VERSION "HNNBNNNYNNNNNNNNNNNNNNNNNNNNNNNNNNNNNNNNNN/4/%%%/4/'%**4NNN///"

NS_ :

BS_:

BU_: BAP_Tester BedienDisp_mi BedienDisp_vo_mi CDI ConMod_CD DashCAM Gateway_Max ICC_IO_Node LSH OCU RDK_RS3 Sound_MIB_ab_Gen3 STH ZR_MIB_EINSTIEG_ab_Gen3 ZR_MIB_OPTION_ab_Gen3 ZR_MIB_TOP_ab_Gen3

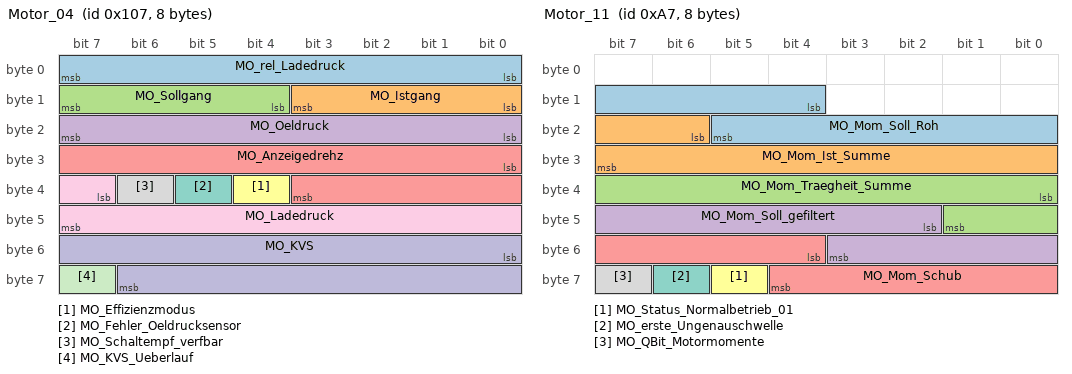
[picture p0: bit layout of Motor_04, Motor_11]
BO_ 263 Motor_04: 8 Gateway_Max
 SG_ MO_rel_Ladedruck : 0|8@1+ (0.4,0) [0.0|100.0] "Unit_PerCent"  ZR_MIB_EINSTIEG_ab_Gen3,ZR_MIB_OPTION_ab_Gen3,ZR_MIB_TOP_ab_Gen3
 SG_ MO_Istgang : 8|4@1+ (1.0,0.0) [0.0|15] ""  OCU,ZR_MIB_EINSTIEG_ab_Gen3,ZR_MIB_OPTION_ab_Gen3,ZR_MIB_TOP_ab_Gen3
 SG_ MO_Sollgang : 12|4@1+ (1.0,0.0) [0.0|15] ""  OCU,ZR_MIB_EINSTIEG_ab_Gen3,ZR_MIB_OPTION_ab_Gen3,ZR_MIB_TOP_ab_Gen3
 SG_ MO_Oeldruck : 16|8@1+ (0.04,0) [0.00|10.00] "Unit_Bar"  Vector__XXX
 SG_ MO_Anzeigedrehz : 24|12@1+ (3,0) [0|12282] "Unit_MinutInver"  OCU,ZR_MIB_EINSTIEG_ab_Gen3,ZR_MIB_OPTION_ab_Gen3,ZR_MIB_TOP_ab_Gen3
 SG_ MO_Effizienzmodus : 36|1@1+ (1.0,0.0) [0.0|1] ""  Vector__XXX
 SG_ MO_Fehler_Oeldrucksensor : 37|1@1+ (1.0,0.0) [0.0|1] ""  OCU
 SG_ MO_Schaltempf_verfbar : 38|1@1+ (1.0,0.0) [0.0|1] ""  OCU,ZR_MIB_EINSTIEG_ab_Gen3,ZR_MIB_OPTION_ab_Gen3,ZR_MIB_TOP_ab_Gen3
 SG_ MO_Ladedruck : 39|9@1+ (0.01,0) [0.00|5.10] "Unit_Bar"  OCU,ZR_MIB_EINSTIEG_ab_Gen3,ZR_MIB_OPTION_ab_Gen3,ZR_MIB_TOP_ab_Gen3
 SG_ MO_KVS : 48|15@1+ (1,0) [0|32767] "Unit_MicroLiter"  OCU
 SG_ MO_KVS_Ueberlauf : 63|1@1+ (1.0,0.0) [0.0|1] ""  OCU

BO_ 1600 Motor_07: 8 Gateway_Max
 SG_ MO_QBit_Ansaugluft_Temp : 0|1@1+ (1.0,0.0) [0.0|1] ""  Vector__XXX
 SG_ MO_QBit_Oel_Temp : 1|1@1+ (1.0,0.0) [0.0|1] ""  OCU,ZR_MIB_OPTION_ab_Gen3
 SG_ MO_QBit_Kuehlmittel_Temp : 2|1@1+ (1.0,0.0) [0.0|1] ""  OCU,ZR_MIB_OPTION_ab_Gen3
 SG_ MO_KL15_Abschaltempfehlung : 3|1@1+ (1.0,0.0) [0.0|1] ""  Vector__XXX
 SG_ MO_HYB_Fehler_HV_Netz : 4|1@1+ (1.0,0.0) [0.0|1] ""  Vector__XXX
 SG_ MO_aktives_Getriebeheizen : 5|1@1+ (1.0,0.0) [0.0|1] ""  Vector__XXX
 SG_ MO_Absperrventil_oeffnen : 6|2@1+ (1.0,0.0) [0.0|3] ""  Vector__XXX
 SG_ MO_Ansaugluft_Temp : 8|8@1+ (0.75,-48) [-48.00|141.75] "Unit_DegreCelsi"  OCU
 SG_ MO_Oel_Temp : 16|8@1+ (1,-60) [-60|192] "Unit_DegreCelsi"  OCU,ZR_MIB_OPTION_ab_Gen3
 SG_ MO_Kuehlmittel_Temp : 24|8@1+ (0.75,-48) [-48.00|141.75] "Unit_DegreCelsi"  OCU,STH,ZR_MIB_OPTION_ab_Gen3
 SG_ MO_Hoeheninfo : 32|8@1+ (0.00781,0) [0.00000|1.98374] ""  LSH,OCU,STH
 SG_ MO_Kennfeldk : 40|1@1+ (1.0,0.0) [0.0|1] ""  Vector__XXX
 SG_ MO_Versionsinfo_02 : 41|5@1+ (1.0,0.0) [0.0|31] ""  Vector__XXX
 SG_ MO_QBit_Hoeheninfo : 46|1@1+ (1.0,0.0) [0.0|1] ""  Vector__XXX
 SG_ MO_Getriebe_kuehlen : 47|1@1+ (1.0,0.0) [0.0|1] ""  Vector__XXX
 SG_ MO_Mom_Traegheit_02 : 48|5@1+ (0.01,0) [0.00|0.31] "Unit_KiloGramMeterSquar"  OCU
 SG_ MO_Heizungspumpenansteuerung : 53|4@1+ (10,0) [0|100] "Unit_PerCent"  STH
 SG_ MO_SpannungsAnf : 57|1@1+ (1.0,0.0) [0.0|1] ""  Vector__XXX
 SG_ MO_Nachlaufzeit_Heizungspumpe : 58|6@1+ (15,0) [0|945] "Unit_Secon"  STH

BO_ 1607 Motor_09: 8 Gateway_Max
 SG_ MO_ITM_Kuehlmittel_Temp : 0|8@1+ (0.75,-48) [-45.75|143.25] "Unit_DegreCelsi"  ZR_MIB_OPTION_ab_Gen3
 SG_ MO_E85_Sensor : 8|4@1+ (10,0) [0|100] "Unit_PerCent"  LSH,STH
 SG_ SCR_Anz_Motorstarts : 12|4@1+ (1.0,0.0) [0.0|15] ""  Vector__XXX
 SG_ SCR_Reichweite : 16|15@1+ (1,0) [0|32766] "Unit_KiloMeter"  Vector__XXX
 SG_ MO_Ethanol_Spuelhinweis : 31|1@1+ (1.0,0.0) [0.0|1] ""  Vector__XXX
 SG_ SCR_Warnstufe_1 : 32|1@1+ (1.0,0.0) [0.0|1] ""  Vector__XXX
 SG_ SCR_Warnstufe_2 : 33|1@1+ (1.0,0.0) [0.0|1] ""  Vector__XXX
 SG_ SCR_Text : 34|3@1+ (1.0,0.0) [0.0|7] ""  Vector__XXX
 SG_ SCR_Akustik : 37|2@1+ (1.0,0.0) [0.0|3] ""  Vector__XXX
 SG_ SCR_verbaut : 39|1@1+ (1.0,0.0) [0.0|1] ""  Vector__XXX
 SG_ MO_Kraftstofffilter_Wasser : 40|1@1+ (1.0,0.0) [0.0|1] ""  Vector__XXX
 SG_ SCR_Systemfehler : 41|1@1+ (1.0,0.0) [0.0|1] ""  Vector__XXX
 SG_ SCR_Inducement_Strategie : 42|2@1+ (1.0,0.0) [0.0|3] ""  Vector__XXX
 SG_ MO_CO2_Faktor : 44|12@1+ (1,0) [1|4094] "Unit_GramPerLiter"  Vector__XXX
 SG_ MO_MKB_MUX M  : 56|2@1+ (1.0,0.0) [0.0|3] ""  Vector__XXX
 SG_ MO_MKB_01 m0  : 59|5@1+ (1.0,0.0) [0.0|31] ""  Vector__XXX
 SG_ MO_MKB_02 m1  : 59|5@1+ (1.0,0.0) [0.0|31] ""  Vector__XXX
 SG_ MO_MKB_03 m2  : 59|5@1+ (1.0,0.0) [0.0|31] ""  Vector__XXX
 SG_ MO_MKB_04 m3  : 59|5@1+ (1.0,0.0) [0.0|31] ""  Vector__XXX

BO_ 167 Motor_11: 8 Gateway_Max
 SG_ MO_Mom_Soll_Roh : 12|10@1+ (1,-509) [-509|509] ""  Vector__XXX
 SG_ MO_Mom_Ist_Summe : 22|10@1+ (1,-509) [-509|509] ""  OCU,ZR_MIB_EINSTIEG_ab_Gen3,ZR_MIB_OPTION_ab_Gen3,ZR_MIB_TOP_ab_Gen3
 SG_ MO_Mom_Traegheit_Summe : 32|10@1+ (1,-509) [-509|509] ""  Vector__XXX
 SG_ MO_Mom_Soll_gefiltert : 42|10@1+ (1,-509) [-509|509] ""  Vector__XXX
 SG_ MO_Mom_Schub : 52|9@1+ (1,-509) [-509|0] ""  Vector__XXX
 SG_ MO_Status_Normalbetrieb_01 : 61|1@1+ (1.0,0.0) [0.0|1] ""  Vector__XXX
 SG_ MO_erste_Ungenauschwelle : 62|1@1+ (1.0,0.0) [0.0|1] ""  Vector__XXX
 SG_ MO_QBit_Motormomente : 63|1@1+ (1.0,0.0) [0.0|1] ""  Vector__XXX

BO_ 958 Motor_14: 8 Gateway_Max
 SG_ Motor_14_CRC : 0|8@1+ (1,0) [0|255] ""  Vector__XXX
 SG_ Motor_14_BZ : 8|4@1+ (1,0) [0|15] ""  Vector__XXX
 SG_ MO_StartStopp_Status : 12|2@1+ (1.0,0.0) [0.0|3] ""  OCU,ZR_MIB_EINSTIEG_ab_Gen3
 SG_ MO_StartStopp_Wiederstart : 14|1@1+ (1.0,0.0) [0.0|1] ""  LSH,STH,ZR_MIB_EINSTIEG_ab_Gen3,ZR_MIB_OPTION_ab_Gen3,ZR_MIB_TOP_ab_Gen3
 SG_ MO_StartStopp_Motorstopp : 15|1@1+ (1.0,0.0) [0.0|1] ""  LSH,OCU,STH,ZR_MIB_EINSTIEG_ab_Gen3,ZR_MIB_OPTION_ab_Gen3,ZR_MIB_TOP_ab_Gen3
 SG_ MO_Freig_Reku : 16|2@1+ (1.0,0.0) [0.0|3] ""  Vector__XXX
 SG_ MO_Kl_75 : 18|1@1+ (1.0,0.0) [0.0|1] ""  OCU,ZR_MIB_EINSTIEG_ab_Gen3,ZR_MIB_OPTION_ab_Gen3,ZR_MIB_TOP_ab_Gen3
 SG_ MO_Kl_50 : 19|1@1+ (1.0,0.0) [0.0|1] ""  ICC_IO_Node,OCU,STH,ZR_MIB_EINSTIEG_ab_Gen3,ZR_MIB_OPTION_ab_Gen3,ZR_MIB_TOP_ab_Gen3
 SG_ MO_Gangposition : 20|4@1+ (1.0,0.0) [0.0|15] ""  OCU,ZR_MIB_EINSTIEG_ab_Gen3,ZR_MIB_OPTION_ab_Gen3
 SG_ MO_StartStopp_Fahrerwunsch : 24|2@1+ (1.0,0.0) [0.0|3] ""  Vector__XXX
 SG_ MO_HYB_Fahrbereitschaft : 26|1@1+ (1.0,0.0) [0.0|1] ""  OCU
 SG_ MO_Ext_E_Fahrt_aktiv : 27|1@1+ (1.0,0.0) [0.0|1] ""  Vector__XXX
 SG_ MO_Fahrer_bremst : 28|1@1+ (1.0,0.0) [0.0|1] ""  OCU,ZR_MIB_EINSTIEG_ab_Gen3,ZR_MIB_OPTION_ab_Gen3,ZR_MIB_TOP_ab_Gen3
 SG_ MO_QBit_Fahrer_bremst : 29|1@1+ (1.0,0.0) [0.0|1] ""  OCU,ZR_MIB_EINSTIEG_ab_Gen3,ZR_MIB_OPTION_ab_Gen3,ZR_MIB_TOP_ab_Gen3
 SG_ MO_BLS : 30|1@1+ (1.0,0.0) [0.0|1] ""  Vector__XXX
 SG_ MO_Konsistenz_Bremsped : 31|1@1+ (1.0,0.0) [0.0|1] ""  Vector__XXX
 SG_ MO_Timeout_ESP : 32|1@1+ (1.0,0.0) [0.0|1] ""  Vector__XXX
 SG_ MO_Klima_Eingr : 33|2@1+ (1.0,0.0) [0.0|3] ""  Vector__XXX
 SG_ MO_Aussp_Anlass : 35|1@1+ (1.0,0.0) [0.0|1] ""  Vector__XXX
 SG_ MO_Freig_Anlass : 36|1@1+ (1.0,0.0) [0.0|1] ""  Vector__XXX
 SG_ MO_Kuppl_schalter : 37|1@1+ (1.0,0.0) [0.0|1] ""  OCU,ZR_MIB_EINSTIEG_ab_Gen3,ZR_MIB_OPTION_ab_Gen3,ZR_MIB_TOP_ab_Gen3
 SG_ MO_Interlock : 38|1@1+ (1.0,0.0) [0.0|1] ""  Vector__XXX
 SG_ MO_Motor_laeuft : 39|1@1+ (1.0,0.0) [0.0|1] ""  LSH,OCU
 SG_ MO_Kickdown : 40|1@1+ (1.0,0.0) [0.0|1] ""  OCU,ZR_MIB_EINSTIEG_ab_Gen3,ZR_MIB_OPTION_ab_Gen3,ZR_MIB_TOP_ab_Gen3
 SG_ MO_QBit_KL_75 : 41|1@1+ (1.0,0.0) [0.0|1] ""  Vector__XXX
 SG_ MO_EKlKomLeiRed : 42|2@1+ (1.0,0.0) [0.0|3] ""  Vector__XXX
 SG_ MO_Handshake_STH : 44|1@1+ (1.0,0.0) [0.0|1] ""  STH
 SG_ MO_BKV_Unterdruckwarnung : 45|1@1+ (1.0,0.0) [0.0|1] ""  Vector__XXX
 SG_ MO_Freigabe_Segeln : 46|1@1+ (1.0,0.0) [0.0|1] ""  Vector__XXX
 SG_ MO_PTC_Status : 47|3@1+ (1.0,0.0) [0.0|7] ""  Vector__XXX
 SG_ MO_QBit_Gangposition : 50|1@1+ (1.0,0.0) [0.0|1] ""  OCU,ZR_MIB_EINSTIEG_ab_Gen3
 SG_ MO_Signalquelle_Gangposition : 51|1@1+ (1.0,0.0) [0.0|1] ""  Vector__XXX
 SG_ MO_Remotestart_Betrieb : 52|1@1+ (1.0,0.0) [0.0|1] ""  OCU
 SG_ MO_Remotestart_moeglich : 53|1@1+ (1.0,0.0) [0.0|1] ""  Vector__XXX
 SG_ MO_FMAus_aktiv : 55|1@1+ (1.0,0.0) [0.0|1] ""  Vector__XXX
 SG_ MO_FMAus_Startvariante : 56|2@1+ (1.0,0.0) [0.0|3] ""  Vector__XXX
 SG_ MO_BMS_NV_Anf_stuetzen : 58|1@1+ (1.0,0.0) [0.0|1] ""  Vector__XXX
 SG_ MO_Zylinderabschaltung : 59|2@1+ (1.0,0.0) [0.0|3] ""  Vector__XXX
 SG_ MO_HYB_VM_aktiv : 61|1@1+ (1.0,0.0) [0.0|1] ""  Vector__XXX
 SG_ MO_StartVorauss_erfuellt : 62|2@1+ (1.0,0.0) [0.0|3] ""  Vector__XXX

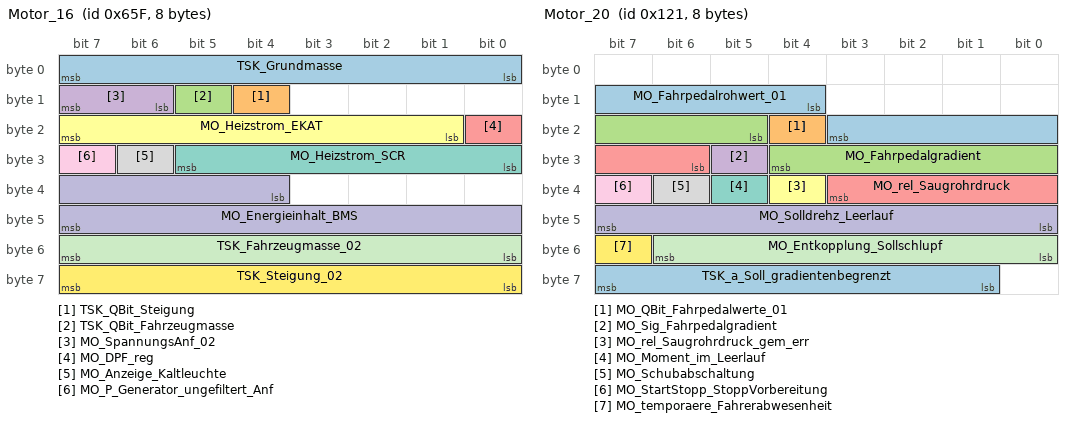
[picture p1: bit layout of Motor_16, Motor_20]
BO_ 1631 Motor_16: 8 Gateway_Max
 SG_ TSK_Grundmasse : 0|8@1+ (32,0) [0|8128] "Unit_KiloGram"  Vector__XXX
 SG_ TSK_QBit_Steigung : 12|1@1+ (1.0,0.0) [0.0|1] ""  OCU,ZR_MIB_EINSTIEG_ab_Gen3,ZR_MIB_TOP_ab_Gen3
 SG_ TSK_QBit_Fahrzeugmasse : 13|1@1+ (1.0,0.0) [0.0|1] ""  Vector__XXX
 SG_ MO_SpannungsAnf_02 : 14|2@1+ (1.0,0.0) [0.0|3] ""  Vector__XXX
 SG_ MO_DPF_reg : 16|1@1+ (1.0,0.0) [0.0|1] ""  OCU
 SG_ MO_Heizstrom_EKAT : 17|7@1+ (1,0) [0|126] "Unit_Amper"  Vector__XXX
 SG_ MO_Heizstrom_SCR : 24|6@1+ (1,0) [0|62] "Unit_Amper"  Vector__XXX
 SG_ MO_Anzeige_Kaltleuchte : 30|1@1+ (1.0,0.0) [0.0|1] ""  Vector__XXX
 SG_ MO_P_Generator_ungefiltert_Anf : 31|1@1+ (1.0,0.0) [0.0|1] ""  Vector__XXX
 SG_ MO_Energieinhalt_BMS : 36|12@1+ (25,0) [0|102325] "Unit_WattHour"  Vector__XXX
 SG_ TSK_Fahrzeugmasse_02 : 48|8@1+ (32,0) [0|8128] "Unit_KiloGram"  OCU
 SG_ TSK_Steigung_02 : 56|8@1+ (0.8,-101.6) [-100.8|101.6] "Unit_PerCent"  OCU,ZR_MIB_EINSTIEG_ab_Gen3

BO_ 1648 Motor_18: 8 Gateway_Max
 SG_ MO_max_Ladedruck : 0|6@1+ (0.1,0) [0.0|6.3] "Unit_Bar"  ZR_MIB_EINSTIEG_ab_Gen3,ZR_MIB_OPTION_ab_Gen3,ZR_MIB_TOP_ab_Gen3
 SG_ MO_ANC_Kennfeld_Anf : 6|2@1+ (1.0,0.0) [0.0|3] ""  Vector__XXX
 SG_ MO_Bremslicht_Reku : 8|1@1+ (1.0,0.0) [0.0|1] ""  Vector__XXX
 SG_ MO_StartStopp_PopUp : 9|2@1+ (1.0,0.0) [0.0|3] ""  Vector__XXX
 SG_ MO1_Sperr_Info_WFS : 11|1@1+ (1.0,0.0) [0.0|1] ""  Vector__XXX
 SG_ MO1_Freigabe_Info_WFS : 12|1@1+ (1.0,0.0) [0.0|1] ""  Vector__XXX
 SG_ MO_EPCL : 13|3@1+ (1.0,0.0) [0.0|7] ""  OCU
 SG_ MO_Zylabsch_Texte_02 : 16|4@1+ (1.0,0.0) [0.0|15] ""  Vector__XXX
 SG_ MO_Fahrzeugtyp : 20|3@1+ (1.0,0.0) [0.0|7] ""  ConMod_CD,OCU
 SG_ MO_NMAX_Schaltanzeige : 23|9@1+ (25,0) [0|12775] "Unit_MinutInver"  Vector__XXX
 SG_ MO_Abstellzeit : 32|8@1+ (8,0) [0|2024] "Unit_Minut"  OCU
 SG_ MO_Abstellzeit_Status : 40|2@1+ (1.0,0.0) [0.0|3] ""  Vector__XXX
 SG_ MO1_Freigabe_Verfallsinfo_WFS : 42|1@1+ (1.0,0.0) [0.0|1] ""  Vector__XXX
 SG_ MO_Hybrid_StartStopp_LED : 43|2@1+ (1.0,0.0) [0.0|3] ""  Vector__XXX
 SG_ MO_Fehler_Zylabsch : 45|2@1+ (1.0,0.0) [0.0|3] ""  Vector__XXX
 SG_ MO_Anzahl_Abgesch_Zyl : 47|3@1+ (1.0,0.0) [0.0|7] ""  Vector__XXX
 SG_ MO_Zylabsch_Texte : 50|2@1+ (1.0,0.0) [0.0|3] ""  Vector__XXX
 SG_ MO_Ethanol_BS_Texte : 52|3@1+ (1.0,0.0) [0.0|7] ""  Vector__XXX
 SG_ MO_Drehzahl_Warnung : 55|1@1+ (1.0,0.0) [0.0|1] ""  Vector__XXX
 SG_ MO_obere_Drehzahlgrenze : 56|8@1+ (50,0) [50|12750] "Unit_MinutInver"  Vector__XXX

BO_ 289 Motor_20: 8 Gateway_Max
 SG_ MO_Fahrpedalrohwert_01 : 12|8@1+ (0.4,0) [0.0|101.6] "Unit_PerCent"  OCU,ZR_MIB_EINSTIEG_ab_Gen3,ZR_MIB_OPTION_ab_Gen3,ZR_MIB_TOP_ab_Gen3
 SG_ MO_QBit_Fahrpedalwerte_01 : 20|1@1+ (1.0,0.0) [0.0|1] ""  Vector__XXX
 SG_ MO_Fahrpedalgradient : 21|8@1+ (25,0) [0|6350] "Unit_PerCentPerSecon"  OCU
 SG_ MO_Sig_Fahrpedalgradient : 29|1@1+ (1.0,0.0) [0.0|1] ""  Vector__XXX
 SG_ MO_rel_Saugrohrdruck : 30|6@1+ (18,0) [0|1116] "Unit_MilliBar"  OCU
 SG_ MO_rel_Saugrohrdruck_gem_err : 36|1@1+ (1.0,0.0) [0.0|1] ""  Vector__XXX
 SG_ MO_Moment_im_Leerlauf : 37|1@1+ (1.0,0.0) [0.0|1] ""  Vector__XXX
 SG_ MO_Schubabschaltung : 38|1@1+ (1.0,0.0) [0.0|1] ""  Vector__XXX
 SG_ MO_StartStopp_StoppVorbereitung : 39|1@1+ (1.0,0.0) [0.0|1] ""  Vector__XXX
 SG_ MO_Solldrehz_Leerlauf : 40|8@1+ (10,0) [0|2540] "Unit_MinutInver"  Vector__XXX
 SG_ MO_Entkopplung_Sollschlupf : 48|7@1+ (20,0) [0|2480] "Unit_MinutInver"  Vector__XXX
 SG_ MO_temporaere_Fahrerabwesenheit : 55|1@1+ (1.0,0.0) [0.0|1] ""  Vector__XXX
 SG_ TSK_a_Soll_gradientenbegrenzt : 57|7@1+ (0.1,-7.2) [-7.2|5.4] "Unit_MeterPerSeconSquar"  Vector__XXX

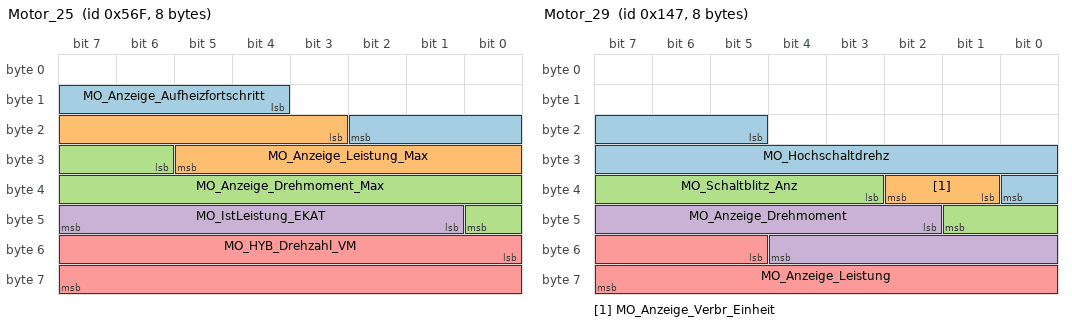
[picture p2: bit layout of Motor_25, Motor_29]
BO_ 1391 Motor_25: 8 Gateway_Max
 SG_ MO_Anzeige_Aufheizfortschritt : 12|7@1+ (1,0) [0|100] "Unit_PerCent"  Vector__XXX
 SG_ MO_Anzeige_Leistung_Max : 19|11@1+ (0.6,0) [0.0|1227.0] "Unit_KiloWatt"  ZR_MIB_TOP_ab_Gen3
 SG_ MO_Anzeige_Drehmoment_Max : 30|11@1+ (1,0) [0|2045] "Unit_NewtoMeter"  ZR_MIB_EINSTIEG_ab_Gen3,ZR_MIB_OPTION_ab_Gen3,ZR_MIB_TOP_ab_Gen3
 SG_ MO_IstLeistung_EKAT : 41|7@1+ (20,0) [0|2500] "Unit_Watt"  Vector__XXX
 SG_ MO_HYB_Drehzahl_VM : 48|16@1+ (0.25,0) [0.00|16256.00] "Unit_MinutInver"  Vector__XXX

BO_ 967 Motor_26: 8 Gateway_Max
 SG_ MO_Kuehlerluefter_MUX M  : 0|1@1+ (1.0,0.0) [0.0|1] ""  Vector__XXX
 SG_ MO_Kuehlerluefter_1 m0  : 1|7@1+ (1,0) [0|100] "Unit_PerCent"  OCU
 SG_ MO_Kuehlerluefter_2 m1  : 1|7@1+ (1,0) [0|100] "Unit_PerCent"  OCU
 SG_ MO_EFLEX_Lampe : 8|2@1+ (1.0,0.0) [0.0|3] ""  Vector__XXX
 SG_ MO_KJS_nicht_bereit : 10|1@1+ (1.0,0.0) [0.0|1] ""  Vector__XXX
 SG_ MO_ITM_Warnung_Pumpe : 11|1@1+ (1.0,0.0) [0.0|1] ""  OCU
 SG_ WIV_Anzeige_aktiv : 12|1@1+ (1.0,0.0) [0.0|1] ""  ZR_MIB_EINSTIEG_ab_Gen3,ZR_MIB_OPTION_ab_Gen3,ZR_MIB_TOP_ab_Gen3
 SG_ WIV_Oelmin_Warn : 13|1@1+ (1.0,0.0) [0.0|1] ""  OCU,ZR_MIB_EINSTIEG_ab_Gen3,ZR_MIB_OPTION_ab_Gen3,ZR_MIB_TOP_ab_Gen3
 SG_ WIV_Sensorfehler : 14|1@1+ (1.0,0.0) [0.0|1] ""  ZR_MIB_EINSTIEG_ab_Gen3,ZR_MIB_OPTION_ab_Gen3,ZR_MIB_TOP_ab_Gen3
 SG_ WIV_Schieflage : 15|1@1+ (1.0,0.0) [0.0|1] ""  OCU,ZR_MIB_EINSTIEG_ab_Gen3,ZR_MIB_OPTION_ab_Gen3,ZR_MIB_TOP_ab_Gen3
 SG_ WIV_Oelstand : 16|4@1+ (12.5,0) [0.0|100.0] "Unit_PerCent"  OCU,ZR_MIB_EINSTIEG_ab_Gen3,ZR_MIB_OPTION_ab_Gen3,ZR_MIB_TOP_ab_Gen3
 SG_ MO_Zustand_HWP : 20|2@1+ (1.0,0.0) [0.0|3] ""  Vector__XXX
 SG_ OLEV_Systemstoerung : 22|1@1+ (1.0,0.0) [0.0|1] ""  ZR_MIB_EINSTIEG_ab_Gen3,ZR_MIB_OPTION_ab_Gen3,ZR_MIB_TOP_ab_Gen3
 SG_ MO_Oelwarnung_max : 23|1@1+ (1.0,0.0) [0.0|1] ""  OCU
 SG_ WIV_Oelsystem_aktiv : 24|1@1+ (1.0,0.0) [0.0|1] ""  ZR_MIB_EINSTIEG_ab_Gen3,ZR_MIB_OPTION_ab_Gen3,ZR_MIB_TOP_ab_Gen3
 SG_ WIV_nicht_betriebswarm : 25|1@1+ (1.0,0.0) [0.0|1] ""  OCU,ZR_MIB_EINSTIEG_ab_Gen3,ZR_MIB_OPTION_ab_Gen3,ZR_MIB_TOP_ab_Gen3
 SG_ WIV_Ueberfuell_Warn : 26|1@1+ (1.0,0.0) [0.0|1] ""  ZR_MIB_EINSTIEG_ab_Gen3,ZR_MIB_OPTION_ab_Gen3,ZR_MIB_TOP_ab_Gen3
 SG_ WIV_laufender_Motor : 27|1@1+ (1.0,0.0) [0.0|1] ""  ZR_MIB_EINSTIEG_ab_Gen3,ZR_MIB_OPTION_ab_Gen3,ZR_MIB_TOP_ab_Gen3
 SG_ MO_E_Warnungen : 28|4@1+ (1.0,0.0) [0.0|15] ""  Vector__XXX
 SG_ MO_Text_Motorstart : 32|4@1+ (1.0,0.0) [0.0|15] ""  Vector__XXX
 SG_ MO_E_Texte : 36|4@1+ (1.0,0.0) [0.0|15] ""  Vector__XXX
 SG_ WIV_Oeldyn_avl : 40|1@1+ (1.0,0.0) [0.0|1] ""  Vector__XXX
 SG_ MO_Text_Partikelfil_Reg : 41|1@1+ (1,0) [0|1] ""  OCU
 SG_ OLEV_Oelstand_nicht_vorhanden : 42|1@1+ (1.0,0.0) [0.0|1] ""  ZR_MIB_EINSTIEG_ab_Gen3,ZR_MIB_OPTION_ab_Gen3,ZR_MIB_TOP_ab_Gen3
 SG_ WIV_Oelmenge : 43|5@1+ (125,0) [0|3875] "Unit_MilliLiter"  OCU,ZR_MIB_EINSTIEG_ab_Gen3,ZR_MIB_OPTION_ab_Gen3,ZR_MIB_TOP_ab_Gen3
 SG_ MO_Systemlampe : 48|1@1+ (1.0,0.0) [0.0|1] ""  OCU
 SG_ MO_OBD2_Lampe : 49|1@1+ (1.0,0.0) [0.0|1] ""  OCU
 SG_ MO_Heissleuchte : 50|1@1+ (1.0,0.0) [0.0|1] ""  OCU,ZR_MIB_TOP_ab_Gen3
 SG_ MO_Partikel_Lampe : 51|1@1+ (1.0,0.0) [0.0|1] ""  OCU
 SG_ MO_RedFahrleistung_Lampe : 52|1@1+ (1.0,0.0) [0.0|1] ""  Vector__XXX
 SG_ WIV_Oelstand_nicht_vorhanden : 53|1@1+ (1.0,0.0) [0.0|1] ""  ZR_MIB_EINSTIEG_ab_Gen3,ZR_MIB_OPTION_ab_Gen3,ZR_MIB_TOP_ab_Gen3
 SG_ WIV_nachfuellanzeige_ein : 54|1@1+ (1.0,0.0) [0.0|1] ""  Vector__XXX
 SG_ WIV_Ueberfuell_deaktiv : 55|1@1+ (1.0,0.0) [0.0|1] ""  Vector__XXX
 SG_ WIV_Unterfuell_Warn : 56|1@1+ (1.0,0.0) [0.0|1] ""  ZR_MIB_EINSTIEG_ab_Gen3,ZR_MIB_OPTION_ab_Gen3,ZR_MIB_TOP_ab_Gen3
 SG_ MO_Tankdeckel_Lampe : 57|1@1+ (1.0,0.0) [0.0|1] ""  Vector__XXX
 SG_ MO_Text_Tankdeckelwarn : 58|1@1+ (1.0,0.0) [0.0|1] ""  Vector__XXX
 SG_ MO_Vorglueh_Lampe : 59|1@1+ (1.0,0.0) [0.0|1] ""  Vector__XXX
 SG_ WIV_Oeldr_Warn_Motor : 60|1@1+ (1.0,0.0) [0.0|1] ""  OCU
 SG_ MO_E_Mode : 61|3@1+ (1.0,0.0) [0.0|7] ""  Vector__XXX

BO_ 327 Motor_29: 8 Gateway_Max
 SG_ MO_Hochschaltdrehz : 21|12@1+ (3,0) [3|12282] "Unit_MinutInver"  Vector__XXX
 SG_ MO_Anzeige_Verbr_Einheit : 33|2@1+ (1.0,0.0) [0.0|3] ""  Vector__XXX
 SG_ MO_Schaltblitz_Anz : 35|7@1+ (1,0) [0|100] "Unit_PerCent"  Vector__XXX
 SG_ MO_Anzeige_Drehmoment : 42|11@1+ (1,0) [0|2045] "Unit_NewtoMeter"  OCU,ZR_MIB_EINSTIEG_ab_Gen3,ZR_MIB_OPTION_ab_Gen3,ZR_MIB_TOP_ab_Gen3
 SG_ MO_Anzeige_Leistung : 53|11@1+ (0.6,0) [0.0|1227.0] "Unit_KiloWatt"  ZR_MIB_EINSTIEG_ab_Gen3,ZR_MIB_OPTION_ab_Gen3,ZR_MIB_TOP_ab_Gen3

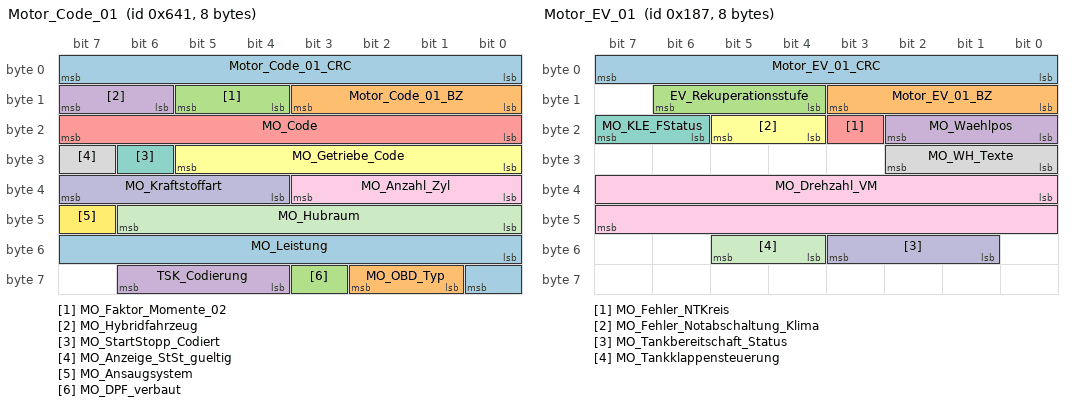
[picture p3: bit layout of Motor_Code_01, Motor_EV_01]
BO_ 1601 Motor_Code_01: 8 Gateway_Max
 SG_ Motor_Code_01_CRC : 0|8@1+ (1,0) [0|255] ""  Vector__XXX
 SG_ Motor_Code_01_BZ : 8|4@1+ (1,0) [0|15] ""  Vector__XXX
 SG_ MO_Faktor_Momente_02 : 12|2@1+ (1,0) [1|3] "Unit_NewtoMeter"  OCU,ZR_MIB_EINSTIEG_ab_Gen3,ZR_MIB_OPTION_ab_Gen3,ZR_MIB_TOP_ab_Gen3
 SG_ MO_Hybridfahrzeug : 14|2@1+ (1.0,0.0) [0.0|3] ""  ConMod_CD,OCU
 SG_ MO_Code : 16|8@1+ (1,0) [0|255] ""  OCU
 SG_ MO_Getriebe_Code : 24|6@1+ (1.0,0.0) [0.0|63] ""  OCU
 SG_ MO_StartStopp_Codiert : 30|1@1+ (1.0,0.0) [0.0|1] ""  Vector__XXX
 SG_ MO_Anzeige_StSt_gueltig : 31|1@1+ (1.0,0.0) [0.0|1] ""  Vector__XXX
 SG_ MO_Anzahl_Zyl : 32|4@1+ (1.0,0.0) [0.0|15] ""  Vector__XXX
 SG_ MO_Kraftstoffart : 36|4@1+ (1.0,0.0) [0.0|15] ""  ConMod_CD,LSH,OCU,STH,ZR_MIB_EINSTIEG_ab_Gen3,ZR_MIB_TOP_ab_Gen3
 SG_ MO_Hubraum : 40|7@1+ (0.1,0) [0.0|12.7] "Unit_Liter"  OCU,ZR_MIB_EINSTIEG_ab_Gen3,ZR_MIB_OPTION_ab_Gen3,ZR_MIB_TOP_ab_Gen3
 SG_ MO_Ansaugsystem : 47|1@1+ (1.0,0.0) [0.0|1] ""  ZR_MIB_EINSTIEG_ab_Gen3,ZR_MIB_OPTION_ab_Gen3,ZR_MIB_TOP_ab_Gen3
 SG_ MO_Leistung : 48|9@1+ (1,0) [0|511] "Unit_KiloWatt"  OCU,ZR_MIB_EINSTIEG_ab_Gen3,ZR_MIB_OPTION_ab_Gen3,ZR_MIB_TOP_ab_Gen3
 SG_ MO_OBD_Typ : 57|2@1+ (1.0,0.0) [0.0|3] ""  OCU
 SG_ MO_DPF_verbaut : 59|1@1+ (1.0,0.0) [0.0|1] ""  Vector__XXX
 SG_ TSK_Codierung : 60|3@1+ (1.0,0.0) [0.0|7] ""  OCU

BO_ 391 Motor_EV_01: 8 Gateway_Max
 SG_ Motor_EV_01_CRC : 0|8@1+ (1,0) [0|255] ""  Vector__XXX
 SG_ Motor_EV_01_BZ : 8|4@1+ (1,0) [0|15] ""  Vector__XXX
 SG_ EV_Rekuperationsstufe : 12|3@1+ (1.0,0.0) [0.0|7] ""  Vector__XXX
 SG_ MO_Waehlpos : 16|3@1+ (1.0,0.0) [0.0|7] ""  ZR_MIB_EINSTIEG_ab_Gen3,ZR_MIB_OPTION_ab_Gen3
 SG_ MO_Fehler_NTKreis : 19|1@1+ (1.0,0.0) [0.0|1] ""  Vector__XXX
 SG_ MO_Fehler_Notabschaltung_Klima : 20|2@1+ (1.0,0.0) [0.0|3] ""  Vector__XXX
 SG_ MO_KLE_FStatus : 22|2@1+ (1.0,0.0) [0.0|3] ""  Vector__XXX
 SG_ MO_WH_Texte : 24|3@1+ (1.0,0.0) [0.0|7] ""  Vector__XXX
 SG_ MO_Drehzahl_VM : 32|16@1+ (0.25,0) [0.00|16383.00] "Unit_MinutInver"  Vector__XXX
 SG_ MO_Tankbereitschaft_Status : 49|3@1+ (1.0,0.0) [0.0|7] ""  Vector__XXX
 SG_ MO_Tankklappensteuerung : 52|2@1+ (1.0,0.0) [0.0|3] ""  Vector__XXX

BO_ 813 Motor_Gas_01: 8 Gateway_Max
 SG_ MO_Fuellstand_LPG m1  : 0|10@1+ (0.125,0) [0.000|127.625] "Unit_Liter"  Vector__XXX
 SG_ MO_CNG_LPG M  : 12|1@1+ (1.0,0.0) [0.0|1] ""  Vector__XXX
 SG_ MO_CNG_Tankstopp m0  : 15|1@1+ (1.0,0.0) [0.0|1] ""  ZR_MIB_TOP_ab_Gen3
 SG_ MO_LPG_Tankstopp m1  : 15|1@1+ (1.0,0.0) [0.0|1] ""  Vector__XXX
 SG_ MO_AnzeigeGasbetrieb : 16|4@1+ (1.0,0.0) [0.0|15] ""  Vector__XXX
 SG_ MO_akt_Betrieb : 20|1@1+ (1.0,0.0) [0.0|1] ""  Vector__XXX
 SG_ MO_Erdgasqualitaet : 21|3@1+ (1.0,0.0) [0.0|7] ""  Vector__XXX
 SG_ MO_Verbrauchsaequivalent : 24|8@1+ (0.008,0) [0.008|2.000] "Unit_None"  Vector__XXX
 SG_ MO_Tankmasse_CNG m0  : 32|8@1+ (0.25,0) [0.25|63.50] "Unit_KiloGram"  Vector__XXX
 SG_ MO_Tankvolumen_LPG m1  : 32|8@1+ (0.5,0) [0.5|127.0] "Unit_Liter"  Vector__XXX
 SG_ MO_Fuellungsgrad_CNG m0  : 40|8@1+ (0.4,0) [0.0|101.2] "Unit_PerCent"  OCU
 SG_ MO_Fuellungsgrad_LPG m1  : 40|8@1+ (0.4,0) [0.0|101.2] "Unit_PerCent"  Vector__XXX
 SG_ MO_CNG_Ueberlauf m0  : 48|1@1+ (1.0,0.0) [0.0|1] ""  Vector__XXX
 SG_ MO_LPG_Ueberlauf m1  : 48|1@1+ (1.0,0.0) [0.0|1] ""  Vector__XXX
 SG_ MO_Verbrauch_CNG m0  : 49|15@1+ (1,0) [0|32767] "Unit_MilliGram"  Vector__XXX
 SG_ MO_Verbrauch_LPG m1  : 49|15@1+ (1,0) [0|32767] "Unit_MicroLiter"  Vector__XXX

BO_ 2589284112 Motor_VTD_01: 8 Gateway_Max
 SG_ MO_VTD_TD_L : 0|32@1+ (0.1,0) [0.0|429496729.3] "Unit_KiloMeter"  ZR_MIB_OPTION_ab_Gen3,ZR_MIB_TOP_ab_Gen3
 SG_ MO_VTD_CDEODT_L : 32|32@1+ (0.1,0) [0.0|429496729.3] "Unit_KiloMeter"  ZR_MIB_OPTION_ab_Gen3,ZR_MIB_TOP_ab_Gen3

BO_ 2589284113 Motor_VTD_01_SOK_Signatur: 8 Gateway_Max
 SG_ SOK_Motor_VTD_01_Signatur : 0|64@1+ (1,0) [0|18446744073709551615] ""  ZR_MIB_OPTION_ab_Gen3,ZR_MIB_TOP_ab_Gen3

BO_ 2589284114 Motor_VTD_02: 8 Gateway_Max
 SG_ MO_VTD_CDFC_L : 0|32@1+ (0.01,0) [0.00|42949672.93] "Unit_Liter"  ZR_MIB_OPTION_ab_Gen3,ZR_MIB_TOP_ab_Gen3
 SG_ MO_VTD_CDERDT_L : 32|32@1+ (0.1,0) [0.0|429496729.3] "Unit_KiloMeter"  ZR_MIB_OPTION_ab_Gen3,ZR_MIB_TOP_ab_Gen3

BO_ 2589284115 Motor_VTD_02_SOK_Signatur: 8 Gateway_Max
 SG_ SOK_Motor_VTD_02_Signatur : 0|64@1+ (1,0) [0|18446744073709551615] ""  ZR_MIB_OPTION_ab_Gen3,ZR_MIB_TOP_ab_Gen3

BO_ 2589284116 Motor_VTD_03: 8 Gateway_Max
 SG_ MO_VTD_CIDT_L : 0|32@1+ (0.1,0) [0.0|429496729.3] "Unit_KiloMeter"  ZR_MIB_OPTION_ab_Gen3,ZR_MIB_TOP_ab_Gen3
 SG_ MO_VTD_GE_L : 32|32@1+ (0.1,0) [0.0|429496729.3] "Unit_KiloWattHour"  ZR_MIB_OPTION_ab_Gen3,ZR_MIB_TOP_ab_Gen3

BO_ 2589284117 Motor_VTD_03_SOK_Signatur: 8 Gateway_Max
 SG_ SOK_Motor_VTD_03_Signatur : 0|64@1+ (1,0) [0|18446744073709551615] ""  ZR_MIB_OPTION_ab_Gen3,ZR_MIB_TOP_ab_Gen3

BO_ 2589284118 Motor_VTD_04: 8 Gateway_Max
 SG_ MO_VTD_CIFC_L : 0|32@1+ (0.01,0) [0.00|42949672.93] "Unit_Liter"  ZR_MIB_OPTION_ab_Gen3,ZR_MIB_TOP_ab_Gen3
 SG_ MO_VTD_FC_L : 32|32@1+ (0.01,0) [0.00|42949672.93] "Unit_Liter"  ZR_MIB_OPTION_ab_Gen3,ZR_MIB_TOP_ab_Gen3

BO_ 2589284119 Motor_VTD_04_SOK_Signatur: 8 Gateway_Max
 SG_ SOK_Motor_VTD_04_Signatur : 0|64@1+ (1,0) [0|18446744073709551615] ""  ZR_MIB_OPTION_ab_Gen3,ZR_MIB_TOP_ab_Gen3

BO_ 2583737729 NAD_AuthTime_SSN_Req: 8 ConMod_CD
 SG_ NAD_AuthTime_SSN_Req_Data : 0|64@1+ (1.0,0.0) [0.0|18446744073709551615] ""  Gateway_Max

BO_ 2583868801 NAD_AuthTime_SSN_Resp: 8 Gateway_Max
 SG_ NAD_AuthTime_SSN_Resp_Data : 0|64@1+ (1.0,0.0) [0.0|18446744073709551615] ""  ConMod_CD

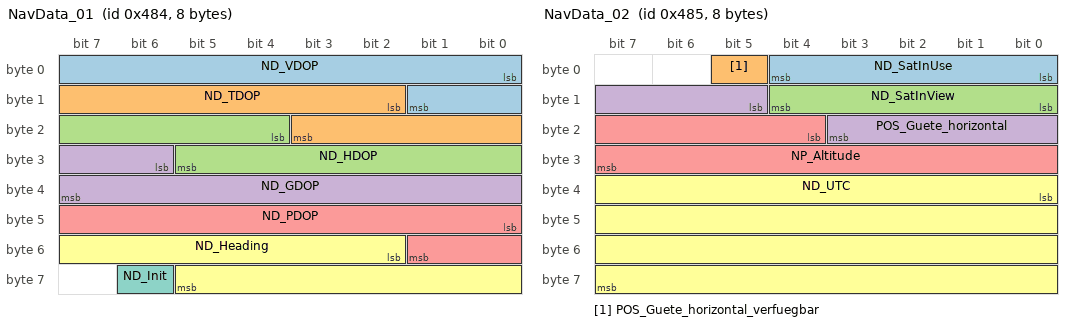
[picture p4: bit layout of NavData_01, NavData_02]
BO_ 1156 NavData_01: 8 ZR_MIB_EINSTIEG_ab_Gen3
 SG_ ND_VDOP : 0|10@1+ (0.025,0) [0.000|25.000] ""  Gateway_Max,OCU
 SG_ ND_TDOP : 10|10@1+ (0.025,0) [0.000|25.000] ""  Gateway_Max,OCU
 SG_ ND_HDOP : 20|10@1+ (0.025,0) [0.000|25.000] ""  Gateway_Max,OCU
 SG_ ND_GDOP : 30|10@1+ (0.025,0) [0.000|25.000] ""  Gateway_Max,OCU
 SG_ ND_PDOP : 40|10@1+ (0.025,0) [0.000|25.000] ""  Gateway_Max,OCU
 SG_ ND_Heading : 50|12@1+ (0.1,0) [0.0|359.9] "Unit_DegreOfArc"  Gateway_Max,OCU
 SG_ ND_Init : 62|1@1+ (1.0,0.0) [0.0|1] ""  Gateway_Max,OCU

BO_ 1157 NavData_02: 8 ZR_MIB_EINSTIEG_ab_Gen3
 SG_ ND_SatInUse : 0|5@1+ (1,0) [0|29] ""  Gateway_Max,OCU
 SG_ POS_Guete_horizontal_verfuegbar : 5|1@1+ (1.0,0.0) [0.0|1] ""  Gateway_Max,OCU
 SG_ ND_SatInView : 8|5@1+ (1,0) [0|29] ""  Gateway_Max,OCU
 SG_ POS_Guete_horizontal : 13|7@1+ (2,0) [0|246] "Unit_Meter"  Gateway_Max,OCU
 SG_ NP_Altitude : 20|12@1+ (2,-500) [-500|7686] "Unit_Meter"  Gateway_Max,OCU
 SG_ ND_UTC : 32|32@1+ (1,0) [0|4294967293] "Unit_Secon"  Gateway_Max,OCU

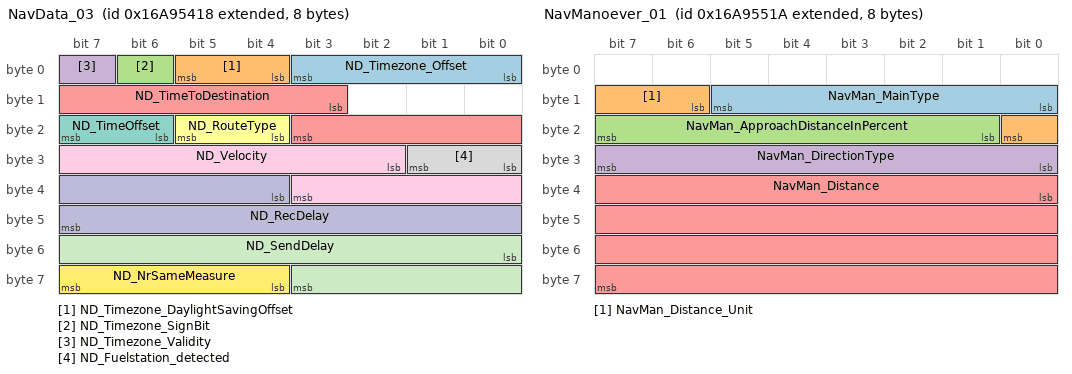
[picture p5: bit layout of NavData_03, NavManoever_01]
BO_ 2527679512 NavData_03: 8 ZR_MIB_TOP_ab_Gen3
 SG_ ND_Timezone_Offset : 0|4@1+ (1,0) [0|12] "Unit_Hours"  Vector__XXX
 SG_ ND_Timezone_DaylightSavingOffset : 4|2@1+ (30,0) [0|60] "Unit_Minut"  Vector__XXX
 SG_ ND_Timezone_SignBit : 6|1@1+ (1.0,0.0) [0.0|1] ""  Vector__XXX
 SG_ ND_Timezone_Validity : 7|1@1+ (1.0,0.0) [0.0|1] ""  Vector__XXX
 SG_ ND_TimeToDestination : 11|9@1+ (1,0) [0|509] "Unit_Minut"  Vector__XXX
 SG_ ND_RouteType : 20|2@1+ (1.0,0.0) [0.0|3] ""  Vector__XXX
 SG_ ND_TimeOffset : 22|2@1+ (1.0,0.0) [0.0|3] ""  Vector__XXX
 SG_ ND_Fuelstation_detected : 24|2@1+ (1.0,0.0) [0.0|3] ""  Vector__XXX
 SG_ ND_Velocity : 26|10@1+ (0.1,0) [0.0|102.1] "Unit_MeterPerSecon"  Vector__XXX
 SG_ ND_RecDelay : 36|12@1+ (1,0) [0|4093] "Unit_MilliSecon"  Vector__XXX
 SG_ ND_SendDelay : 48|12@1+ (1,0) [0|4093] "Unit_MilliSecon"  Vector__XXX
 SG_ ND_NrSameMeasure : 60|4@1+ (1,0) [0|8] ""  Vector__XXX

BO_ 2527679665 NavData_04: 8 Gateway_Max
 SG_ ND_PSD_Street_Category : 53|3@1+ (1.0,0.0) [0.0|7] ""  ConMod_CD,Gateway_Max,OCU
 SG_ ND_Avrg_Speed_RangeData : 56|8@1+ (1,0) [0|253] "Unit_KiloMeterPerHour"  Gateway_Max

BO_ 2527679770 NavManoever_01: 8 ZR_MIB_OPTION_ab_Gen3
 SG_ NavMan_MainType : 8|6@1+ (1.0,0.0) [0.0|63] ""  Gateway_Max
 SG_ NavMan_Distance_Unit : 14|3@1+ (1.0,0.0) [0.0|7] ""  Gateway_Max
 SG_ NavMan_ApproachDistanceInPercent : 17|7@1+ (1,0) [0|100] "Unit_PerCent"  Gateway_Max
 SG_ NavMan_DirectionType : 24|8@1+ (1.411764705882353,0) [0E-15|360.000000000000015] "Unit_DegreOfArc"  Gateway_Max
 SG_ NavMan_Distance : 32|32@1+ (0.1,0) [0.0|429496729.5] "Unit_None"  Gateway_Max

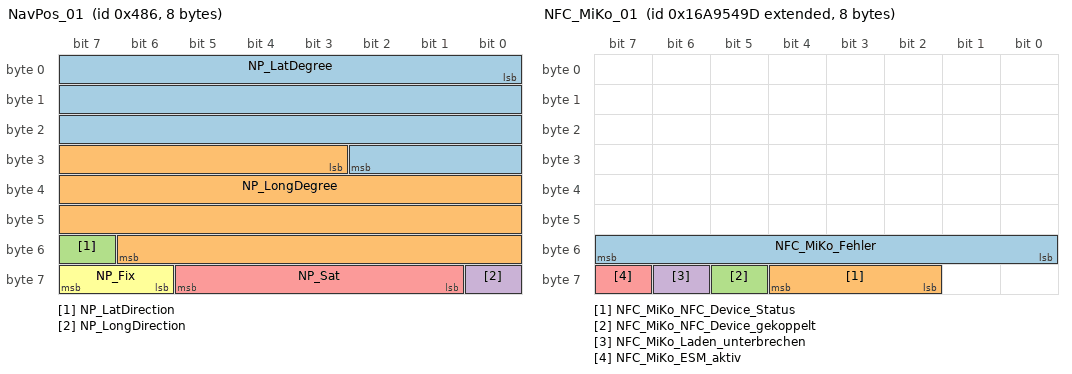
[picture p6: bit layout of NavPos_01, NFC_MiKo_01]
BO_ 1158 NavPos_01: 8 ZR_MIB_EINSTIEG_ab_Gen3
 SG_ NP_LatDegree : 0|27@1+ (0.000001,0) [0.000000|90.000000] "Unit_DegreOfArc"  Gateway_Max,OCU
 SG_ NP_LongDegree : 27|28@1+ (0.000001,0) [0.000000|180.000000] "Unit_DegreOfArc"  Gateway_Max,OCU
 SG_ NP_LatDirection : 55|1@1+ (1.0,0.0) [0.0|1] ""  Gateway_Max,OCU
 SG_ NP_LongDirection : 56|1@1+ (1.0,0.0) [0.0|1] ""  Gateway_Max,OCU
 SG_ NP_Sat : 57|5@1+ (1,0) [0|29] ""  Gateway_Max,OCU
 SG_ NP_Fix : 62|2@1+ (1.0,0.0) [0.0|3] ""  Gateway_Max,OCU

BO_ 2589283496 NavPos_02_Map_Matched: 8 Gateway_Max
 SG_ POS_MUX M  : 0|2@1+ (1.0,0.0) [0.0|3] ""  Gateway_Max,OCU
 SG_ POS_ODD_EVEN : 2|1@1+ (1.0,0.0) [0.0|1] ""  Gateway_Max,OCU
 SG_ POS_PosStati m0  : 3|4@1+ (1.0,0.0) [0.0|15] ""  Gateway_Max,OCU
 SG_ POS_Heading m1  : 4|12@1+ (0.1,0) [0.0|409.5] "Unit_DegreOfArc"  Gateway_Max,OCU
 SG_ POS_LatDirection m0  : 7|1@1+ (1.0,0.0) [0.0|1] ""  Gateway_Max,OCU
 SG_ POS_LatDegree m0  : 8|27@1+ (0.000001,0) [0.000000|90.000000] "Unit_DegreOfArc"  CDI,Gateway_Max,OCU
 SG_ POS_Last_GPS_Sync m1  : 16|14@1+ (1,0) [0|16383] "Unit_Secon"  Gateway_Max,OCU
 SG_ POS_Heading_Trust m1  : 30|2@1+ (1.0,0.0) [0.0|3] ""  Gateway_Max,OCU
 SG_ POS_UTC_REF m1  : 32|32@1+ (1,0) [0|4294967295] "Unit_Secon"  Gateway_Max,OCU
 SG_ POS_LongDirection m0  : 35|1@1+ (1.0,0.0) [0.0|1] ""  Gateway_Max,OCU
 SG_ POS_LongDegree m0  : 36|28@1+ (0.000001,0) [0.000000|180.000000] "Unit_DegreOfArc"  CDI,Gateway_Max,OCU

BO_ 2527679645 NFC_MiKo_01: 8 Gateway_Max
 SG_ NFC_MiKo_Fehler : 48|8@1+ (1.0,0.0) [0.0|255] ""  ICC_IO_Node,ZR_MIB_OPTION_ab_Gen3,ZR_MIB_TOP_ab_Gen3
 SG_ NFC_MiKo_NFC_Device_Status : 58|3@1+ (1.0,0.0) [0.0|7] ""  ICC_IO_Node,ZR_MIB_OPTION_ab_Gen3,ZR_MIB_TOP_ab_Gen3
 SG_ NFC_MiKo_NFC_Device_gekoppelt : 61|1@1+ (1.0,0.0) [0.0|1] ""  ICC_IO_Node,ZR_MIB_OPTION_ab_Gen3,ZR_MIB_TOP_ab_Gen3
 SG_ NFC_MiKo_Laden_unterbrechen : 62|1@1+ (1.0,0.0) [0.0|1] ""  ICC_IO_Node,ZR_MIB_OPTION_ab_Gen3,ZR_MIB_TOP_ab_Gen3
 SG_ NFC_MiKo_ESM_aktiv : 63|1@1+ (1.0,0.0) [0.0|1] ""  ICC_IO_Node,ZR_MIB_OPTION_ab_Gen3,ZR_MIB_TOP_ab_Gen3

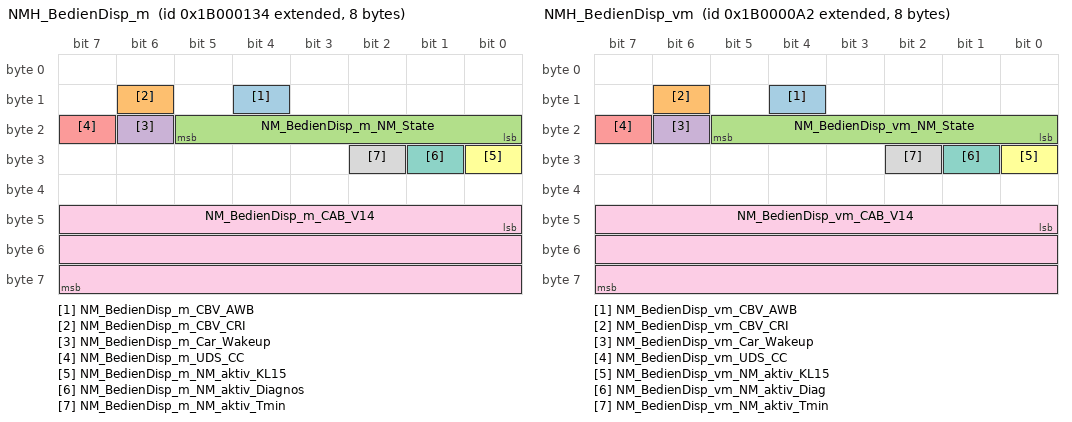
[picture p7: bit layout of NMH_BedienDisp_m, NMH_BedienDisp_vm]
BO_ 2600468788 NMH_BedienDisp_m: 8 BedienDisp_mi
 SG_ NM_BedienDisp_m_CBV_AWB : 12|1@1+ (1.0,0.0) [0.0|1] ""  Gateway_Max
 SG_ NM_BedienDisp_m_CBV_CRI : 14|1@1+ (1.0,0.0) [0.0|1] ""  Gateway_Max
 SG_ NM_BedienDisp_m_NM_State : 16|6@1+ (1.0,0.0) [0.0|63] ""  BedienDisp_vo_mi,CDI,ConMod_CD,DashCAM,ICC_IO_Node,LSH,OCU,RDK_RS3,Sound_MIB_ab_Gen3,STH,ZR_MIB_EINSTIEG_ab_Gen3,ZR_MIB_OPTION_ab_Gen3,ZR_MIB_TOP_ab_Gen3
 SG_ NM_BedienDisp_m_Car_Wakeup : 22|1@1+ (1.0,0.0) [0.0|1] ""  Gateway_Max
 SG_ NM_BedienDisp_m_UDS_CC : 23|1@1+ (1.0,0.0) [0.0|1] ""  Vector__XXX
 SG_ NM_BedienDisp_m_NM_aktiv_KL15 : 24|1@1+ (1.0,0.0) [0.0|1] ""  Vector__XXX
 SG_ NM_BedienDisp_m_NM_aktiv_Diagnos : 25|1@1+ (1.0,0.0) [0.0|1] ""  Vector__XXX
 SG_ NM_BedienDisp_m_NM_aktiv_Tmin : 26|1@1+ (1.0,0.0) [0.0|1] ""  Vector__XXX
 SG_ NM_BedienDisp_m_CAB_V14 : 40|24@1+ (1.0,0.0) [0.0|16777215] ""  Gateway_Max

BO_ 2600468642 NMH_BedienDisp_vm: 8 BedienDisp_vo_mi
 SG_ NM_BedienDisp_vm_CBV_AWB : 12|1@1+ (1.0,0.0) [0.0|1] ""  Gateway_Max
 SG_ NM_BedienDisp_vm_CBV_CRI : 14|1@1+ (1.0,0.0) [0.0|1] ""  Gateway_Max
 SG_ NM_BedienDisp_vm_NM_State : 16|6@1+ (1.0,0.0) [0.0|63] ""  BedienDisp_mi,CDI,ConMod_CD,DashCAM,ICC_IO_Node,LSH,OCU,RDK_RS3,Sound_MIB_ab_Gen3,STH,ZR_MIB_EINSTIEG_ab_Gen3,ZR_MIB_OPTION_ab_Gen3,ZR_MIB_TOP_ab_Gen3
 SG_ NM_BedienDisp_vm_Car_Wakeup : 22|1@1+ (1.0,0.0) [0.0|1] ""  Gateway_Max
 SG_ NM_BedienDisp_vm_UDS_CC : 23|1@1+ (1.0,0.0) [0.0|1] ""  Vector__XXX
 SG_ NM_BedienDisp_vm_NM_aktiv_KL15 : 24|1@1+ (1.0,0.0) [0.0|1] ""  Vector__XXX
 SG_ NM_BedienDisp_vm_NM_aktiv_Diag : 25|1@1+ (1.0,0.0) [0.0|1] ""  Vector__XXX
 SG_ NM_BedienDisp_vm_NM_aktiv_Tmin : 26|1@1+ (1.0,0.0) [0.0|1] ""  Vector__XXX
 SG_ NM_BedienDisp_vm_CAB_V14 : 40|24@1+ (1.0,0.0) [0.0|16777215] ""  Gateway_Max

BO_ 2600468583 NMH_eCall: 8 ConMod_CD
 SG_ NM_eCall_CBV_AWB : 12|1@1+ (1.0,0.0) [0.0|1] ""  Gateway_Max
 SG_ NM_eCall_CBV_CRI : 14|1@1+ (1.0,0.0) [0.0|1] ""  Gateway_Max
 SG_ NM_eCall_NM_State : 16|6@1+ (1.0,0.0) [0.0|63] ""  BedienDisp_mi,BedienDisp_vo_mi,CDI,DashCAM,ICC_IO_Node,LSH,RDK_RS3,Sound_MIB_ab_Gen3,STH,ZR_MIB_EINSTIEG_ab_Gen3,ZR_MIB_OPTION_ab_Gen3,ZR_MIB_TOP_ab_Gen3
 SG_ NM_eCall_Car_Wakeup : 22|1@1+ (1.0,0.0) [0.0|1] ""  Gateway_Max
 SG_ NM_eCall_UDS_CC : 23|1@1+ (1.0,0.0) [0.0|1] ""  Vector__XXX
 SG_ NM_eCall_NM_aktiv_KL15 : 24|1@1+ (1.0,0.0) [0.0|1] ""  Vector__XXX
 SG_ NM_eCall_NM_aktiv_Diagnose : 25|1@1+ (1.0,0.0) [0.0|1] ""  Vector__XXX
 SG_ NM_eCall_NM_aktiv_Tmin : 26|1@1+ (1.0,0.0) [0.0|1] ""  Vector__XXX
 SG_ NM_eCall_NM_aktiv_Laden : 27|1@1+ (1.0,0.0) [0.0|1] ""  Vector__XXX
 SG_ NM_eCall_NM_aktiv_Settings : 28|1@1+ (1.0,0.0) [0.0|1] ""  Vector__XXX
 SG_ NM_eCall_NM_aktiv_Klimatisieren : 29|1@1+ (1.0,0.0) [0.0|1] ""  Vector__XXX
 SG_ NM_eCall_NM_aktiv_Status : 30|1@1+ (1.0,0.0) [0.0|1] ""  Vector__XXX
 SG_ NM_eCall_NM_aktiv_Remote_Control : 31|1@1+ (1.0,0.0) [0.0|1] ""  Vector__XXX
 SG_ NM_eCall_NM_aktiv_Call : 32|1@1+ (1.0,0.0) [0.0|1] ""  Vector__XXX
 SG_ NM_eCall_NM_aktiv_Dienstabfrage : 33|1@1+ (1.0,0.0) [0.0|1] ""  Vector__XXX
 SG_ NM_eCall_NM_aktiv_IAA : 34|1@1+ (1.0,0.0) [0.0|1] ""  Vector__XXX
 SG_ NM_eCall_NM_aktiv_RemoteStart : 35|1@1+ (1.0,0.0) [0.0|1] ""  Vector__XXX
 SG_ NM_eCall_NM_aktiv_MQTT_GW : 36|1@1+ (1.0,0.0) [0.0|1] ""  Vector__XXX
 SG_ NM_eCall_NM_aktiv_RPA : 37|1@1+ (1.0,0.0) [0.0|1] ""  Vector__XXX
 SG_ NM_eCall_NM_aktiv_ORU_OCU : 38|1@1+ (1.0,0.0) [0.0|1] ""  Vector__XXX
 SG_ NM_eCall_NM_aktiv_PSO : 39|1@1+ (1.0,0.0) [0.0|1] ""  Vector__XXX
 SG_ NM_eCall_CAB_V14 : 40|24@1+ (1.0,0.0) [0.0|16777215] ""  Gateway_Max

BO_TX_BU_ 1156 :ZR_MIB_EINSTIEG_ab_Gen3,ZR_MIB_OPTION_ab_Gen3,ZR_MIB_TOP_ab_Gen3;
BO_TX_BU_ 1157 :ZR_MIB_EINSTIEG_ab_Gen3,ZR_MIB_OPTION_ab_Gen3,ZR_MIB_TOP_ab_Gen3;
BO_TX_BU_ 2527679665 :Gateway_Max,ZR_MIB_EINSTIEG_ab_Gen3,ZR_MIB_OPTION_ab_Gen3,ZR_MIB_TOP_ab_Gen3;
BO_TX_BU_ 1158 :ZR_MIB_EINSTIEG_ab_Gen3,ZR_MIB_OPTION_ab_Gen3,ZR_MIB_TOP_ab_Gen3;
BO_TX_BU_ 2589283496 :Gateway_Max,ZR_MIB_EINSTIEG_ab_Gen3,ZR_MIB_OPTION_ab_Gen3,ZR_MIB_TOP_ab_Gen3;
BO_TX_BU_ 2600468583 :ConMod_CD,OCU;
CM_ BO_ 1600 "ab MQB mit QBit Höheneinfo und MO_Versionsinfo_02";
CM_ BO_ 1648 "Kombischnittstelle";
CM_ BO_ 967 "MQB - vorher Motor_06 / Umbenennung wg. ID-Wechsel";
CM_ BO_ 1601 "ab MQB mit CRC-8";
CM_ BO_ 813 "Gesendet nur bei CNG/LPG-Motorprojekten";

CM_ SG_ 263 MO_Anzeigedrehz "Optimierte Anzeigedrehzahl wegen sportlicherem Drehzahlmesser im Kombi. 
Bei Parallelhybrid: Anzeige VKM- Drehzahl nach Anzeigekonzept

Hinweis: Ehemaliger Fehlerwert 0xFFF wird senderseitig nicht unterstützt. Diesen Wert aus Kompatibilitätsgründen nic";
CM_ SG_ 263 MO_Effizienzmodus "Bei Handschaltern wird  das Fahrprogramm Effizienz signalisiert. 
Bei Automatikgetrieben wird das Fahrprogramm 'D' durch 'E' ersetzt.";
CM_ SG_ 263 MO_Fehler_Oeldrucksensor "Steuert  im Kombiinstrument die gelbe zentrale Warnlampe und das Symbol 'gelbe Ölkanne'  mit der Textmeldung 'Sensorfehler: Werkstatt aufsuchen' an
";
CM_ SG_ 263 MO_Istgang "Aktueller Gang für Anzeige Hochschaltempfehlung (gültig, wenn MO_Schaltempf_verfbar = 1).

Anzeige im Kombi:
Sollgang == Istgang         ==> Anzeige Istgang
Sollgang !=   Istgang         ==> Schaltempfehlung
Sollgang == Istgang == 0 ==> keine Anzeige";
CM_ SG_ 263 MO_KVS "Motorsteuergerätinterner Verbrauchszähler, der vom Kombi zyklisch ausgelesen wird, um die Einspritzmenge zur Verbrauchsmessung aufzusummieren; aus diesem Zählerstand werden Momentan- und Durchschnittsverbrauch berechnet; das Überlauf-Bit ist zu berücksich";
CM_ SG_ 263 MO_KVS_Ueberlauf "Der motorsteuergeräteinterne Verbrauchszähler ist mindestens einmal übergelaufen. Dieses Bit wird genutzt, um erkennen zu können, daß das Motorsteuergerät aus dem Reset-Zustand hochläuft.";
CM_ SG_ 263 MO_Ladedruck "absoluter Ladedruck";
CM_ SG_ 263 MO_Oeldruck "Öldruck analog zur Anzeige";
CM_ SG_ 263 MO_rel_Ladedruck "relativer Ladedruck (für Boostanzeige)";
CM_ SG_ 263 MO_Schaltempf_verfbar "Info, ob Schaltempfehlung im Fzg. verfügbar. Statischer Wert, ändert sich für ein Fzg. nicht!";
CM_ SG_ 263 MO_Sollgang "Motor sendet den Sollgang in den der Fahrer schalten soll. Wird im Kombi als Hochschaltempfehlung hervorgehoben (gültig, wenn MO_Schaltempf_verfbar = 1).

Anzeige im Kombi:
Sollgang == Istgang          ==> Anzeige Istgang
Sollgang !=  Istgang         ";

CM_ SG_ 1600 MO_Absperrventil_oeffnen "Signal an Klima-SG das Absperrrventil anzusteuern. Ab D4 auch 0x3 Ventil_schließen.

Im MQB wird hier der Soll-Status des Absperrventils ausgegeben.
Achtung: bei z. B. klemmendem Ventil entspricht das Signal nicht dem tatsächlichen Status!";
CM_ SG_ 1600 MO_aktives_Getriebeheizen "Information für Getriebe, ob ein Ventil für Getriebheizen angesteuert werden muss";
CM_ SG_ 1600 MO_Ansaugluft_Temp "In Fahrzeugen ohne Außentemperatur vom Kombi kann aus der Ansauglufttemperatur auf die Außentemperatur geschlossen werden. Beim SDI ist das mit einer gewissen Genauigkeit gegeben. Genutzt wird es vom ASG.";
CM_ SG_ 1600 MO_Getriebe_kuehlen "Anforderung Getriebekühlventilansteuerung";
CM_ SG_ 1600 MO_Heizungspumpenansteuerung "Anforderung Heizungspumpenansteuerung
MQB und Hybrid: Status der Heizungsunterstützungspumpe am MSG
";
CM_ SG_ 1600 MO_Hoeheninfo "Korrekturfaktor Höhe (1 entspricht 1013 mbar)";
CM_ SG_ 1600 MO_HYB_Fehler_HV_Netz "Im HV-Bordnetz ist fehlerbedingt kein generatorischer Betrieb möglich. Das 12V-Bordnetz wird über den DC/DC-Wandler allein aus der Traktionsbatterie gespeist. Um diesen Zustand möglichst lange aufrechterhalten zu können, sollten Komfort-Verbraucher abgesc";
CM_ SG_ 1600 MO_Kennfeldk "Die Kennfeldkühlung ist in diesem Fahrzeug verbaut und hat keinen Systemfehler";
CM_ SG_ 1600 MO_KL15_Abschaltempfehlung "Kessy Abschaltempfehlung nach Verlassen des Fahrzeugs";
CM_ SG_ 1600 MO_Kuehlmittel_Temp "Kuehlmitteltemperatur";
CM_ SG_ 1600 MO_Mom_Traegheit_02 "Massenträgheit (J) der Motors bzw. der Antriebsmaschinen in kgm².

Zur Berücksichtigung des E-Motor in Hybrid-Projekten:
in MLB-Projekten wird nur der J-Wert des Verbrennungsmotors und nicht der J-Wert des E-Motors berücksichtigt.
In MQB/MLBevo-Projek";
CM_ SG_ 1600 MO_Nachlaufzeit_Heizungspumpe "Nachlaufzeit für Heizungspumpe für Turboladerschutz";
CM_ SG_ 1600 MO_Oel_Temp "Realer Meßbereich ca. -40..150 Grad";
CM_ SG_ 1600 MO_QBit_Ansaugluft_Temp "
";
CM_ SG_ 1600 MO_QBit_Hoeheninfo "Qualifizierungsbit der Höheninfo. Gesetzt bei Ersatzwert, Init oder Fehler.";
CM_ SG_ 1600 MO_QBit_Kuehlmittel_Temp "
";
CM_ SG_ 1600 MO_SpannungsAnf "Forderung des Motor-SGs zur Spannungsanhebung";
CM_ SG_ 1600 MO_Versionsinfo_02 "Versioninformation vom Motor zur Steuerung bei inkompatiblen KMatrix-Änderung bzw. Einführung von neuen Funktionen, die in den Empfängern verriegelt werden müssen. Zu jedem Ereignis wird ein fixer Zählerstand zugeordnet, um dem Empfänger die funktionale Ä";

CM_ SG_ 1607 MO_CO2_Faktor "dynamischer Umrechnungsfaktor von l in CO2";
CM_ SG_ 1607 MO_E85_Sensor "Information über den E85 Gehalt (%-mass.) im Ottokraftstoff";
CM_ SG_ 1607 MO_Ethanol_Spuelhinweis "Hinweis das der Fahrer beim nächsten Tanken Ethanol armen Sprit tanken soll.";
CM_ SG_ 1607 MO_ITM_Kuehlmittel_Temp "Kuehlmitteltemperatur: Ersatzkühlmitteltemperatur für Motoren mit ITM (Thermomanagement)

ACHTUNG: Ab MQB wird in diesem Signal das Anzeigeplateau durch das MSG dargestellt!";
CM_ SG_ 1607 MO_Kraftstofffilter_Wasser "Für Schlechtkraftstoffländer wird das Wasserabscheidevolumen im Dieselkraftstofffilter mit einem  Wassersensor überwacht. Ist das Volumen erschöpft, erfolgt im Kombi eine entsprechende Anzeige.";
CM_ SG_ 1607 MO_MKB_01 "Motorkennbuchstabe 1";
CM_ SG_ 1607 MO_MKB_02 "Motorkennbuchstabe 2";
CM_ SG_ 1607 MO_MKB_03 "Motorkennbuchstabe 3";
CM_ SG_ 1607 MO_MKB_04 "Motorkennbuchstabe 4";
CM_ SG_ 1607 MO_MKB_MUX "Die vier Motorkennbuchstaben werden gemultiplext in MO_MKB übertragen. Das Signal MO_MKB_MUX stellt das Steuersignal für diesen Multiplexer dar.";
CM_ SG_ 1607 SCR_Akustik "Ansteuerung von Summer/Gong bei Aktivieren der SCR-Warnungen.
Bedienung des Signals nur bei Dieseln mit SCR-System. Andere senden Initwert.";
CM_ SG_ 1607 SCR_Anz_Motorstarts "Anzahl noch möglicher Motorstarts, wenn Reichweite = 0 ist
0..13 = Anzeige 'x mögliche Restarts'
14 = Eingeschränkte Fahrfunktion (z. Zt. Audi)
15 = keine Einschränkung (Anzeige Reichweite)
Bedienung des Signals nur bei Dieseln mit SCR-System.";
CM_ SG_ 1607 SCR_Inducement_Strategie "Art des Motor-Inducement-Konzepts. Abhängig von diesem Signal sind die Warntexte zwischen 'Kein Motorstart (in...km)' und 'eingeschränkte Fahrbarkeit (in ...km)' auszuwählen.";
CM_ SG_ 1607 SCR_Reichweite "Gesamtreichweite in km der aktuellen SCR-Tankfüllung, sofern die Reichweite kleiner 2400 km ist. Bei einer Reichweite größer 2400 km wird grundsätzlich der Initwert (32767) übertragen. Bedienung des Signals nur bei Dieseln mit SCR-System.";
CM_ SG_ 1607 SCR_Systemfehler "Ansteuerung Anzeige für SCR-Systemfehler";
CM_ SG_ 1607 SCR_Text "Warntext (z. B. in Kombination mit SCR Warnstufe und SCR-Systemfehler).
Bedienung des Signals nur bei Dieseln mit SCR-System. Andere senden Initwert.";
CM_ SG_ 1607 SCR_verbaut "Die SCR-Signale deren Initwert ungleich 0 sind, werden nur dann ausgewertet, wenn SCR_verbaut == 1 den Verbau des SCR Systems zeigt.";
CM_ SG_ 1607 SCR_Warnstufe_1 "Ansteuerung der SCR Füllstandswarnlampe (Stufe 1) (gelbe Lampe) SCR_Warnstufe_1 (Prio 2).
Bedienung des Signals nur bei Dieseln mit SCR-System. Andere senden Initwert.";
CM_ SG_ 1607 SCR_Warnstufe_2 "Ansteuerung der SCR Füllstandswarnlampe (Stufe 2) (Blinkbit für gelbe Lampe oder rote Lampe) SCR_Warnstufe_2 (Prio 1).
Bedienung des Signals nur bei Dieseln mit SCR-System. Andere senden Initwert.";

CM_ SG_ 167 MO_erste_Ungenauschwelle "Zusätzliche Ungenauigkeit (zur Grundungenauigkeit). Motormomente ungenau >8% (kleinste Ungenauschwelle)
";
CM_ SG_ 167 MO_Mom_Ist_Summe "Einheitenloser Wert! Faktor in MO_Faktor_Momente_02 in Motor_Code_01 beachten!

Ist-Moment als Summe aus Verbrennungsmotor und E-Motor (bei Hybrid-Konzepten) incl. allen Eingriffen und Korrekturen

In Fahrzeugen mit einer Antriebsachse bzw. mit mechan";
CM_ SG_ 167 MO_Mom_Schub "Einheitenloser Wert! Faktor in MO_Faktor_Momente_02 in Motor_Code_01 beachten!

Moment das sich einstellt, wenn der Fahrer 0% Fahrpedal gibt; bei konventionellen Projekten = alle Verluste (mechanische Reibung und sonstige Verluste) des Verbrennungsmotor";
CM_ SG_ 167 MO_Mom_Soll_gefiltert "Einheitenloser Wert! Faktor in MO_Faktor_Momente_02 in Motor_Code_01 beachten!

MO_Mom_Soll_Roh nach Fahrverhaltensfilter, begrenzt nach oben mit MO_Mom_Begr_dyn, Einrechnung der plausibilisierten Bremsen-Eingriffe; ohne Getriebe-Schalt-Eingriffe, ohne ";
CM_ SG_ 167 MO_Mom_Soll_Roh "Einheitenloser Wert! Faktor in MO_Faktor_Momente_02 in Motor_Code_01 beachten!

Momentenanforderung aus Fahrpedal bzw. von ACC/GRA bzw. aus dem Leerlaufregler (quasistatischer Anteil) bzw. aus Rekuperationsanforderung; keine Begrenzungen, keine Filterun";
CM_ SG_ 167 MO_Mom_Traegheit_Summe "Einheitenloser Wert! Faktor in MO_Faktor_Momente (CAN V6.x) bzw. MO_Faktor_Momente_02 (CAN V7.x) in Motor_Code_01 beachten!

Moment, das zur Beschleunigung der trägen Massen aufgewendet wird bzw. frei wird; Summen aus Anteilen für Verbrennungsmotor und ";
CM_ SG_ 167 MO_QBit_Motormomente "AUDI D4: Zykluszeit: 10ms (siehe Zykluszeit schnell/Cycletime Fast)

Ungenaue Momentenangaben, weil die Momente aus Ersatzwerten berechnet wurden (z.B. HFM ausgefallen). Qualifizierungsbit für die Motormomente.

Achtung:
Reduktion der Zykluszeit Moto";
CM_ SG_ 167 MO_Status_Normalbetrieb_01 "Das Motorsteuergerät sendet das Informationsbit, wenn die Initialisierungsphase des Steuergerätes abgeschlossen ist. Zusätzlich muss die Klemme 15 eingeschalten sein und eine applizierbare Mindestdrehzahlschwelle (Kennlinie in Abh. von der Kühlwassertempe";

CM_ SG_ 958 MO_Aussp_Anlass "Das Signal zeigt an, ob die Wiederholstartsperre aktiv ist. D. h. eine Ansteuerung des Anlassers wird auch bei erfüllten Startvoraussetzungen (HS: Interlock betätigt bzw. AT: P/N eingelegt und Bremse betätigt) nicht erfolgen.";
CM_ SG_ 958 MO_BKV_Unterdruckwarnung "Über die Unterdruckwarnung signalisiert das MSG dem ESP, dass kein ausreichender Unterdruck für den BKV zur Verfügung gestellt werden kann.";
CM_ SG_ 958 MO_BLS "Ungefiltertes Rohsignal des Bremslichtschalters, nur wenn HW-Eingang bestückt und ausgewertet wird. Bei Motoren ohne genutzten HW-Eingang wird kein Ersatzwert (bspw. SW-Signal über CAN) ausgegeben!
Bei AUDI muss das Signal wg. Bremslichtfunktion immer be";
CM_ SG_ 958 MO_BMS_NV_Anf_stuetzen "Garantierte Unterstützung des Zusatzspeichers ist erforderlich. Zusatzspeicher muss an das Versorgungsnezt angebunden werden. ";
CM_ SG_ 958 MO_EKlKomLeiRed "Anforderung an die Klimasteuerung, die Leistungsaufnahme des E-Kompressors bei schlechtem SOC und in bestimmten Fahrsituationen zu begrenzen. (Das bereits bestehende Signal 'Klimakompressor aus' als stets umzusetzende Anforderung bleibt unverändert besteh";
CM_ SG_ 958 MO_Ext_E_Fahrt_aktiv "Funktionsrückmeldung zum erw. E-Fahr-Betrieb über Lampe/LED im E-Mode-Taster";
CM_ SG_ 958 MO_Fahrer_bremst "Redundante Bremsinformation vom Motor.

MLB:
AUDI D4: Zykluszeit: 10ms (siehe Zykluszeit schnell/Cycletime Fast)
Im AUDI B8 wird in diesem Bit der Wert der ESP-CAN-Information 'ESP_Fahrer_bremst' ausgegeben.

Achtung:
Reduktion der Zykluszeit Motor";
CM_ SG_ 958 MO_FMAus_aktiv "Das Signal gibt Rückmeldung ob Freilauf Motor aus aktiv ist. Beleibt auch 0km/h (unterhalb der StartStopp Schwelle) weiterhin aktiv.";
CM_ SG_ 958 MO_FMAus_Startvariante "Startvariante beim Motorstart aus der Freilauf-Motor-AUS Phase";
CM_ SG_ 958 MO_Freig_Anlass "Bit wird gesetzt, wenn der Motor beim Automatikstart gestartet werden darf (Motorstillstand, Emissionsmaßnahmen sind erfüllt).";
CM_ SG_ 958 MO_Freig_Reku "Empfehlung des Motor-SG's zur Spannungsabsenkung/-anhebung für den Rekuperationsbetrieb";
CM_ SG_ 958 MO_Freigabe_Segeln "Freigabebit des Segelbetriebs im Getriebe. Bedingt durch bestimmte Diagnosen und Adaptionen des MSGs, die nur im Schub möglich sind, darf nicht jede Schubphase für einen Segelbetrieb genutzt werden. Eine Freigabe bleibt auch außerhalb einer Schubphase bes";
CM_ SG_ 958 MO_Gangposition "MLB:
Stellung des Wählhebels in der Schaltgasse des Handschaltgetriebes.
MLBevo: 
Ausweitung der Bedienung auch auf Automatikgetriebe;
Routing des Signals GE_Fahrstufe: 
1. Position_R (dez. 6) auf MO_Gangposition: Gang_R (dez. 13) wegen Entfall Signa";
CM_ SG_ 958 MO_Handshake_STH "Es gilt: Signalspec MO_Handshake v1.0

Handshake zwischen MSG und STH. Wenn das MSG die EKP aufgrund einer STH-Anforderung ansteuert und kein Fehlereintrag bzgl. EKP/KPE/NDR vorliegt, wird das Bit gesetzt.";
CM_ SG_ 958 MO_HYB_Fahrbereitschaft "Signal steuert u.a. in der Lenkhilfe zusammen mit weiteren Informationen den Modewechsel in den 'Drivemode'
Grüne Anzeige im Kombiinstrument zur Signalisierung der Bereitschaft des Hybridsystems.";
CM_ SG_ 958 MO_HYB_VM_aktiv "0 = VMotor wird nicht aktiv gehalten (nVM < n_min und keine LL-Regelung aktiv)
1 = VMotor aktiv (ab der ersten Einspritzung; gilt auch für Schubbetrieb, wenn VMotor spätestens durch LLRegelung befeuert würde)
Verwendet zur Bestimmung des Ist-Zustandes";
CM_ SG_ 958 MO_Interlock "Das Motorsteuergerät gibt die Information aus, ab wann der Kupplungsschalter durch das Motorsteuergerät als getreten gesehen wird.
Bei Systemen für Start Stopp muss das Interlocksignal für einen Start durch das MSG generiert werden, sobald der Schalthebe";
CM_ SG_ 958 MO_Kickdown "Es gilt: Signalspec MO_Kickdown v1.0";
CM_ SG_ 958 MO_Kl_50 "Klemme 50: Startausführung durch Ritzelstarter

MLB: nicht von allen Motoren gesendet
MQB/MLBevo: gesendet von allen Motoren";
CM_ SG_ 958 MO_Kl_75 "Klemme X
";
CM_ SG_ 958 MO_Klima_Eingr "Eingriffe des Motor bei der Klima";
CM_ SG_ 958 MO_Konsistenz_Bremsped "MLB:

AUDI D4: Zykluszeit: 10ms (siehe Zykluszeit schnell/Cycletime Fast)
Siehe 'Funktionsspezifikation Bremslichtinfo B8'

Achtung:
Reduktion der Zykluszeit Motor_03 auf 10ms geplant.
Projektabhängig soll künftig mit 10ms gesendet werden.
Empfäng";
CM_ SG_ 958 MO_Kuppl_schalter "MLB:
Das Motorsteuergerät gibt die Information aus, ab wann der Kupplungsschalter durch das Motorsteuergerät als getreten gesehen wird
0x0: Schalter sagt betätigt (Ausgekuppelt)
0x1: Schalter sagt nicht betätigt (Eingekuppelt)

MQB:
Nur Handschalter";
CM_ SG_ 958 MO_Motor_laeuft "Das Motorsteuergerät gibt die Information aus, ab wann der Motor verbrennungsbedingt autark läuft und durch zuschaltbare Nebenaggregate mechanisch belastbar ist (z.B. durch Generator, Klimakompressor, etc.).

Die 'Motor läuft' Information wird ausgegebe";
CM_ SG_ 958 MO_PTC_Status "Status-Rückmeldung vom MSG zum aktuellen PTC-Status (stufiges PTC, Relais am MSG). Bei Ansteuerung eines stufigen PTC durch ein anderes SG beschreibt das Signal die vom MSG freigegebene PTC-Stufe.";
CM_ SG_ 958 MO_QBit_Fahrer_bremst "MLB:
AUDI D4: Zykluszeit: 10ms (siehe Zykluszeit schnell/Cycletime Fast)

Achtung:
Reduktion der Zykluszeit Motor_03 auf 10ms geplant.
Projektabhängig soll künftig mit 10ms gesendet werden.
Empfänger die in weiteren Konzern-Projekten eingesetzt werd";
CM_ SG_ 958 MO_QBit_Gangposition "Qualitätsbit zum Signal MO_Gangposition";
CM_ SG_ 958 MO_QBit_KL_75 "Q - Bit für das KL 75 Signal zur Vermeidung der fehlerhaften Erkennung von Motorstarts. 
Wird auf 1 gesetzt, solange das Motorsteuergerät KL15 = AUS erkannt hat.";
CM_ SG_ 958 MO_Remotestart_Betrieb "Das MSG ist für den Remotestart-Betrieb bereit. Nach Empfang der Motorstartanforderung für RSt-Betrieb durch BCM wird der Fahrzeugmotor gestartet und solange der Motor läuft, bleibt dieses Bit aktiv. Dieses Signal ist nur zur Verwendung durch das BCM zur ";
CM_ SG_ 958 MO_Remotestart_moeglich "Wenn Bit gesetzt, würde das MSG bei entsprechender Anforderung durch das BCM den Remotestartbetrieb einleiten, d.h. das MSG ist remotestartfähig und es liegen aktuell keine relevanten Fehler oder andere Abbruchgründe vor.";
CM_ SG_ 958 MO_Signalquelle_Gangposition "Signalquelle des Signals MO_Gangposition
0: Signalquelle Gangpositionssensor
1: Signalquelle Modellwert (v/n)";
CM_ SG_ 958 MO_StartStopp_Fahrerwunsch "Fahreraktivität Start/Stop";
CM_ SG_ 958 MO_StartStopp_Motorstopp "Motor-Stopp durch Start/Stopp-Koordinator
HYBRID:
Wenn MO_Hybridfahrzeug = 1 gilt:
Verbrennungsmotor durch Hybrid-Koordinator im MSG ausgeschaltet. 
Die definierten Start/Stopp-Signale beziehen sich nur auf den Verbrennungsmotor!";
CM_ SG_ 958 MO_StartStopp_Status "Aktivitätsstatus Start/Stopp-Koordinator
HYBRID:
Wenn MO_Hybridfahrzeug = 1 gilt:
Signal bezieht sich nur auf den Verbrennungsmotor, nicht auf den Hybridantrieb
";
CM_ SG_ 958 MO_StartStopp_Wiederstart "Motorwiederstart durch Start/Stopp-Koordinator
HYBRID:
Wenn MO_Hybridfahrzeug =1 gilt:
Warnung vor Spannungseinbruch beim Zustart des Verbrennungsmotors. 
-nicht relevant, da derzeit kein Start über 12V-Starter geplant-
Dieses Signal wird nur vom Hyb";
CM_ SG_ 958 MO_StartVorauss_erfuellt "Dient der Fallunterscheidung bei ZAT-Betätigung im Zustand 'KL15 ein' (bei nicht gesetztem Signal folgt KL15 aus, bei gesetztem Signal folgt setzen KL50-Anf.)

0: Signal nicht bedient 
1: Voraussetzungen zur Antriebsstrangaktivierung / Startvoraussetzu";
CM_ SG_ 958 MO_Timeout_ESP "500 ms Timeout auf Bremsen-Botschaft ist >= 1 mal aufgelaufen, Löschen des Bits nach Neustart (KL15).

MLB:
AUDI D4: Zykluszeit: 10ms (siehe Zykluszeit schnell/Cycletime Fast)

Achtung:
Reduktion der Zykluszeit Motor_03 auf 10ms geplant.
Projektabh";
CM_ SG_ 958 MO_Zylinderabschaltung "Status Zylinderabschaltung Motor";
CM_ SG_ 958 Motor_14_CRC "Ab MQB und MLBevo:
'Berechnung siehe Lastenheft 'End-to-End Kommunikationsabsicherung'

Endwerte siehe Begleitdokument 'S-PDU Kennungsfolgen'";

CM_ SG_ 1631 MO_Anzeige_Kaltleuchte "Fahrleistungseinschänkungen aus dem Motor-Abgasmanagement zur Anzeige als Lampe ohne Hinweistext im Kombiinstrument";
CM_ SG_ 1631 MO_DPF_reg "Regeneration Diesel-Partikel-Filter";
CM_ SG_ 1631 MO_Energieinhalt_BMS "Restenergieinhalt der Traktionsbatterie, beeinflusst durch Fahrstrategie und weiteren Faktoren der Antriebssteuerung.";
CM_ SG_ 1631 MO_Heizstrom_EKAT "Aktuelle Gesamtstromaufnahme des E-Katalysators";
CM_ SG_ 1631 MO_Heizstrom_SCR "Aktuelle Gesamtstromaufnahme der Tank-, Fördermodul- und Leitungsheizung des SCR-Systems";
CM_ SG_ 1631 MO_P_Generator_ungefiltert_Anf "Bei Empfang der Anforderung soll der Sender BEM_P_Generator ungefiltert befüllen.";
CM_ SG_ 1631 MO_SpannungsAnf_02 "Forderung des Motor-SG's zur Spannungsanhebung";
CM_ SG_ 1631 TSK_Fahrzeugmasse_02 "Neue Definition ab D4
Fahrzeugmasse in kg. Das Signal dient der Anpassung der Sollbeschleunigung vom ACC


";
CM_ SG_ 1631 TSK_Grundmasse "Fahrzeuggrundmasse in kg. Das Signal dient der Anpassung der Sollbeschleunigung vom ACC

Hinweis: Ehemaliger Fehlerwert 0x7F wird senderseitig nicht unterstützt. Diesen Wert aus Kompatibilitätsgründen nicht neu belegen!";
CM_ SG_ 1631 TSK_Steigung_02 "Steigung in % Berg. Das Signal dient der Anpassung der Sollbeschleunigung vom ACC

Positive Werte > bergauf; 
Negative Werte < bergab

Fehler: Die Steigung aufgrund eines Fehlers (mit KD-Fehlereintrag) nicht mehr berechnet werden";

CM_ SG_ 1648 MO1_Freigabe_Info_WFS "WFS-Freigabeinformation";
CM_ SG_ 1648 MO1_Freigabe_Verfallsinfo_WFS "WFS-Freigabeverfallsinformation";
CM_ SG_ 1648 MO1_Sperr_Info_WFS "WFS-Sperrinformation";
CM_ SG_ 1648 MO_Abstellzeit "Abstelldauer nach letztem KL15 aus

Hinweis: 
Ehemaliger Fehlerwert 0xFF wird senderseitig nicht unterstützt. 
Diesen Wert aus Kompatibilitätsgründen nicht neu belegen!";
CM_ SG_ 1648 MO_Abstellzeit_Status "Statusinformation zur Abstellzeit
0: Die dem Status zugeordnete Variable konnte noch nicht berechnet werden. 
1: Die dem Status zugehörige Variable wurde korrekt berechnet. 
2: Der Wert der zugehörigen Variablen ist nur ein Minimalwert. 
3: Der Wert d";
CM_ SG_ 1648 MO_ANC_Kennfeld_Anf "Anforderung ANC Kennfeldumschaltung";
CM_ SG_ 1648 MO_Anzahl_Abgesch_Zyl "Gibt die Anzahl der abgeschalteten Zylinder an. In Übergangszuständen wird der Zielbetriebszustand angezeigt.";
CM_ SG_ 1648 MO_Bremslicht_Reku "Bremslicht (ggf. bei Rekuperation durch E-Motor) wird angesteuert";
CM_ SG_ 1648 MO_Drehzahl_Warnung "Warnhinweis zum Kombi im Fall einer fehlerbehafteten Drehzahlbegrenzung";
CM_ SG_ 1648 MO_EPCL "Die Anforderung der EPC-Lampe vom MSG ans Kombi soll durch das Bus-Signal MO_EPCL gemäß folgender Logik erfolgen:
MO_EPCL = 0 dez -> EPC Lampe aus, kein Text
MO_EPCL = 1 dez -> gelbe EPC-Symbolik, Text „Antrieb: Störung! Bitte Service aufsuchen“
MO_EPC";
CM_ SG_ 1648 MO_Ethanol_BS_Texte "Ethanol Brennstoff-Texte im Kombi

0 = kein Text
1 = E85 Warm_Up
2 = FlexFuel Warnung 3.Stufe (Too cold for ethanol)
3 = Warmfahrempfehlung MQB / FlexFuel Warnung 1.Stufe (Refuel with gasoline)
4 = FlexFuel Warnung 2. Stufe (Refuel with gasoline)
5";
CM_ SG_ 1648 MO_Fahrzeugtyp "Unterscheidet die Fahrzeugtypen bzgl. der Antriebsart";
CM_ SG_ 1648 MO_Fehler_Zylabsch "Fehlerstatus der Funktion Zylinderabschaltung ";
CM_ SG_ 1648 MO_Hybrid_StartStopp_LED "Ansteuerung der Funktions-LED der Hybrid Taste bzw. Start/Stop Deaktivierungstaste.
Der Start/Stopp-Master (derzeit im MSG) (oder ein künftiger Hybrid-Master) soll die Ansteuerung senden.";
CM_ SG_ 1648 MO_max_Ladedruck "maximal möglicher Ladedruck (zur Anpassung des Anzeigebereichs bei absoluter Ladedruckanzeige)";
CM_ SG_ 1648 MO_NMAX_Schaltanzeige "Maximaldrehzahl für Schaltanzeige";
CM_ SG_ 1648 MO_obere_Drehzahlgrenze "obere Drehzahlgrenze des Motors";
CM_ SG_ 1648 MO_StartStopp_PopUp "Das Signal zeigt an, ob der StSt-Status mittels Deaktivierungstaster geändert wurde. Ein Wechsel auf die Werte 01 oder 10 löst im Kombi ein entsprechendes PopUp aus. Bei einem Statuswechsel durch andere Signalquellen (z.B. Charisma, fehlerbedingte Abschal";
CM_ SG_ 1648 MO_Zylabsch_Texte "Zylinderabschaltung mode in Kombi, fuer Zylinderabschaltung";
CM_ SG_ 1648 MO_Zylabsch_Texte_02 "ZAS-Anzeige für den Fahrer im Kombi
0: kein ZAS (generell keinerlei ZAS-Anzeigen)  (Init für nicht ZAS-Motor)
1: ZAS im Vollmotorbetrieb  (Init für ZAS-Motor)
2: ZAS im Abschaltbetrieb: 1 Zyl aktiv
3: ZAS im Abschaltbetrieb: 2 Zyl aktiv
4: ZAS im Abs";

CM_ SG_ 289 MO_Entkopplung_Sollschlupf "MSG fordert von GSG an, das Anfahrelement (Fahr-/Wandlerkupplung) zu entkoppeln; das GSG soll die gesendete Drehzahl als Schlupf einstellen und ggf. die Regler-Parameter umschalten, damit Rucke aus dem Antrieb nicht im Fahrzeug spürbar werden; nutzbar z.B";
CM_ SG_ 289 MO_Fahrpedalgradient "Das Motorsteuergerät besitzt 2 analoge Fahrpedalsignale. Das Signal des ersten Kanals wird alle 4ms abgetastet. Um Bitschwankungen des A/D-Wandler herauszufiltern wird das Signal entjittert. Anschließend wird der Gradient berechnet. Entsprechend der Zyklu";
CM_ SG_ 289 MO_Fahrpedalrohwert_01 "AUDI D4: Zykluszeit: 10ms (siehe Zykluszeit schnell/Cycletime Fast)

Stellung des Fahrpedales (Rohwert, ohne Überlagerung durch GRA-Eingriffe etc.)

Die Funktionen zur Berechung des Fahrpedalrohwerts laufen im 10ms Raster. Der Fahrpedalwert berechnet ";
CM_ SG_ 289 MO_Moment_im_Leerlauf "Fahrerwunschmoment ist minimal: keine Momentenanforderung durch Fahrpedal, ACC oder GRA+; (Das Signal ist unabhängig von Momentenerhöhungen durch Leerlaufregler oder MSR).

AUDI D4: Zykluszeit: 10ms (siehe Zykluszeit schnell/Cycletime Fast)

Achtung:";
CM_ SG_ 289 MO_QBit_Fahrpedalwerte_01 "AUDI D4: Zykluszeit: 10ms (siehe Zykluszeit schnell/Cycletime Fast)

QBit für beide Fahrpedalwerte des Motors (Fahrpedalrohsignal für ESP, EPB, ACC; Fahrpedalwert für Getriebe)

Achtung:
Reduktion der Zykluszeit Motor_03 auf 10ms geplant.
Projektabh";
CM_ SG_ 289 MO_rel_Saugrohrdruck "Der Wert gibt an, um wieviel mbar der Saugrohrdruck unterhalb des Umgebungsdrucks liegt. Überdruck im Saugrohr wird nicht ausgegeben.
0: Saugrohrdruck=Umgebungsdruck";
CM_ SG_ 289 MO_rel_Saugrohrdruck_gem_err "0: mind. eine Modellrechnung wird zur Berechnung des relativen Saugdrucks herangezogen
1: Relativer Saugrohrdruck wird ausschließlich über Messgrößen bestimmt";
CM_ SG_ 289 MO_Schubabschaltung "ESP plausibilisiert Unterdrucksensor nur bei aktiver Schubabschaltung

MLBevo:
Signal wird nur in MLBevo Projekten mit PDKII Getriebe bedient. In allen anderen MLBevo Projekten wird das Signal mit '0' bedient
PDKII berücksichtigt Verzugszeiten, die in";
CM_ SG_ 289 MO_Sig_Fahrpedalgradient "Kennzeichnet das Vorzeichen des Signal 'Fahrpedalgradient'. Die Ausgabe erfolgt nur parallel statisch mit gesendetem Signal: 'Steuerungsbit Fahrpedalgradient' ";
CM_ SG_ 289 MO_Solldrehz_Leerlauf "Leerlaufsolldrehzahl, die im Motor eingestellt ist (Bei Parallelhybrid im E-Fahr-Betrieb Leerlaufsolldrehzahl der E-Maschine). Der Motor paßt aufgrund der Anforderung von anderen Steuergeräten seine Leerlaufsolldrehzahl an, bspw. Kat-Heizen, Anforderung v";
CM_ SG_ 289 MO_StartStopp_StoppVorbereitung "Zeigt allen aktiven Start-/Stoppteilnehmern einen möglichen Motorstopp im Anhaltevorgang an (Empfänger notwendige Vorbereitungen treffen)
Es liegen keine Vetos vor.";
CM_ SG_ 289 MO_temporaere_Fahrerabwesenheit "Das Signal dient zur Signalisierung einer temporären Abwesenheit des Fahrers. In dieser Zeit ist es ihm möglich, sich durch gewisse ¿ im Verlassenskonzept definierte ¿ Fahreraktionen im aktuellen Fahrzyklus zurückzumelden.
Das Signal wird gesetzt, sobald";
CM_ SG_ 289 TSK_a_Soll_gradientenbegrenzt "TSK Sollbeschleunigung für Fahrerassistenzsysteme mit aktiver Längsführung (GRA, ACC, IPA...). Der Wert stellt den ruckbegrenzten Sollwert der TSK-Regelung dar und ist Basis der TSK-Antriebs- und Bremsmomentenvorsteuerung.";

CM_ SG_ 1391 MO_Anzeige_Aufheizfortschritt "Anzeigesignal des Aufheizfortschritts des Abgastrakts im Rahmen der Kaltabfahrbegrenzung";
CM_ SG_ 1391 MO_Anzeige_Drehmoment_Max "Signal gibt das max. verfügbare Drehmoment wieder. Bedient die Drehmomentanzeige im Kombiinstrument. ";
CM_ SG_ 1391 MO_Anzeige_Leistung_Max "Signal gibt die max. verfügbare Motorleistung wieder. Bedient die Leistungsanzeige im Kombiinstrument. ";
CM_ SG_ 1391 MO_HYB_Drehzahl_VM "für OBD freeze frame";
CM_ SG_ 1391 MO_IstLeistung_EKAT "Gesamt IST-Leistung der elektrischen Heizscheibe(n)";

CM_ SG_ 967 MO_E_Mode "Anforderung der E-Mode Statusanzeige";
CM_ SG_ 967 MO_E_Texte "Anforderung von Hinweistexten des E-Systems separat für HEV/BEV bzw. erweiterbar für PHEV";
CM_ SG_ 967 MO_E_Warnungen "Anforderung von Warnanzeigen des E-Systems separat für HEV/BEV bzw. erweiterbar für PHEV";
CM_ SG_ 967 MO_EFLEX_Lampe "Um ein Starten mit E100 zu ermöglichen, wird Kraftstoff ggf. vorgeheizt. Das Signal dient der Anzeige des Heizungsstatus.

Heizung aus -> Lampe aus
Heizung ein -> Lampe ein
Heizung ein und Startversuch -> Lampe blinkend
Heizung nicht möglich -> Lampe";
CM_ SG_ 967 MO_Heissleuchte "Ansteuerung der Kühlwassertemperatur-Heißleuchte (Sensor nur noch am Motorsteuergerät): Temperaturschaltschwellen mit Hysterese (bei VW D1/Colorado Kombi derzeit noch nicht genutzt).";
CM_ SG_ 967 MO_ITM_Warnung_Pumpe "Textanzeige: 'Motor sofort abstellen, geschaltete Wasserpumpe defekt / klemmt'";
CM_ SG_ 967 MO_KJS_nicht_bereit "Dieses Signal zeigen einen Fehler der Kühlerjalousie mit unbekannter Stellung der Lamellen. ";
CM_ SG_ 967 MO_Kuehlerluefter_1 "Ansteuertastverhaeltnis (PWM) der Kuehlerluefterendstufe 1";
CM_ SG_ 967 MO_Kuehlerluefter_2 "Ansteuertastverhaeltnis (PWM) der Kuehlerluefterendstufe 2";
CM_ SG_ 967 MO_Kuehlerluefter_MUX "Multiplexer für das Signal 'MO_Kuehlerlüfter'";
CM_ SG_ 967 MO_OBD2_Lampe "OBD bzw. MIL-Lampe wird vom Motorsteuergerät angesteuert, die Information im Signal GE_OBD_Status wird vom Motorsteuergerät an das Kombi weitergereicht";
CM_ SG_ 967 MO_Oelwarnung_max "Ölstandswarnung mit der Aufforderung zum Ölwechsel.
Hintergrund: Bei Kraftstoffeintrag (B20) ins Öl verbleibt der RME-Anteil irreversibel im Öl.";
CM_ SG_ 967 MO_Partikel_Lampe "Partikelfilter-Lampe wird eingeschaltet";
CM_ SG_ 967 MO_RedFahrleistung_Lampe "Ansteuerung der Turtle-Mode Lampe für E-Traktion Fahrzeuge";
CM_ SG_ 967 MO_Systemlampe "EGas Systemlampe (EPC) oder Vorglühlampe im Kombi, Kombi steuert immer gleiche
LED an, nur über Ziffernblatt wird die EPC von der Vorglühlampe differenziert";
CM_ SG_ 967 MO_Tankdeckel_Lampe "Ansteuerung Tankdeckel-Warnlampe Kombiinstrument (nur Ottomotoren) z.Zt. Vorhalt VW";
CM_ SG_ 967 MO_Text_Motorstart "Anzeigetexte für Start/Stopp und Motor-Start
0xB Fehler_Kupplungsschalter nur für PAG-MLB";
CM_ SG_ 967 MO_Text_Partikelfil_Reg "Über dieses Bit im Kombi wird ein Klartextanzeige erzeugt werden: 'Partikelfilter benötigt Regeneration'.
";
CM_ SG_ 967 MO_Text_Tankdeckelwarn "Textbit der Tankdeckelwarnung, z.Zt. Vorhalt VW";
CM_ SG_ 967 MO_Vorglueh_Lampe "Vorglühlampe im Kombi, Kombi steuert immer gleiche LED an. 
Mit Einführung des Einheits-Kombis sind getrennte Signalwege für Vorglühlampe und EPCL notwendig.";
CM_ SG_ 967 MO_Zustand_HWP "Rückmeldung des  Ansteuerzustand der Hauptwasserpumpe an das Klima-SG .
Der Zustand 'HWP fördert' wird übermittelt, wenn die Schaufeln der Hauptwasserpumpe frei drehen können und die Motordrehzahl und damit die Wasserpumpendrehzahl größer als Null ist. B";
CM_ SG_ 967 OLEV_Oelstand_nicht_vorhanden "Kein aktueller Ölstand vorhanden";
CM_ SG_ 967 OLEV_Systemstoerung "Systemstörung im Ölsystem";
CM_ SG_ 967 WIV_Anzeige_aktiv "Peilstabsanzeigefunktion aktiv";
CM_ SG_ 967 WIV_laufender_Motor "Messung bei laufendem Motor nicht möglich";
CM_ SG_ 967 WIV_nachfuellanzeige_ein "Steuert das Aufblenden der Nachfüllanzeige im Kombi, nach Klemme 15 ein und geöffneter Motorhaube";
CM_ SG_ 967 WIV_nicht_betriebswarm "Motor nicht betriebswarm, Messung ungenau";
CM_ SG_ 967 WIV_Oeldr_Warn_Motor "Löst im Kombiinstrument die rote Prio1-Öldruckwarnung (inkl. 3xBeep) aus.
nur MLB: die Warnauslösung erfolgt nur bei gleichzeitig gesetztem 'WIV_Enable_Oeldr_Motor'";
CM_ SG_ 967 WIV_Oeldyn_avl "Ölstand aus dynamischer Messung vorhanden";
CM_ SG_ 967 WIV_Oelmenge "Ölmenge zwischen Min und Max";
CM_ SG_ 967 WIV_Oelmin_Warn "Signal gibt an wenn der Ölstand die Min-Schwelle unterschritten hat";
CM_ SG_ 967 WIV_Oelstand "8 Segmente zur Balkenanzeige des Ölstands";
CM_ SG_ 967 WIV_Oelstand_nicht_vorhanden "Kein aktueller Ölstand vorhanden";
CM_ SG_ 967 WIV_Oelsystem_aktiv "Gesamtölsystem aktiv (entspricht Ölsensor verbaut) und das Ölstand-Untermenu im MMI aktiv";
CM_ SG_ 967 WIV_Schieflage "Fahrzeug steht nicht waagerecht, Messung ungenau";
CM_ SG_ 967 WIV_Sensorfehler "Ölstand/Öltemperatursensor (TOG) defekt";
CM_ SG_ 967 WIV_Ueberfuell_deaktiv "Unterdrückung der Warnung im Kombi die durch Signal WIV_Ueberfuel_Warn ausgelöst wird";
CM_ SG_ 967 WIV_Ueberfuell_Warn "Ölstand hat die Überfüllschwelle überschritten";
CM_ SG_ 967 WIV_Unterfuell_Warn "Ölstand hat die Unterfüllschwelle unterschritten";

CM_ SG_ 327 MO_Anzeige_Drehmoment "Drehmomentssignal für Sport-HMI im Kombi.";
CM_ SG_ 327 MO_Anzeige_Leistung "Leistungssignal für Sport-HMI im Kombi.";
CM_ SG_ 327 MO_Anzeige_Verbr_Einheit "Signal steht im Kontext MO_Anzeige_Verbrauch und überträgt die Verbrauchseinheit der aktuellen Antriebsart. Signal muss in der gleichen Botschaft wie MO_Anzeige_Verbrauch übertragen werden";
CM_ SG_ 327 MO_Hochschaltdrehz "Hochschaltdrehzahl bei manuellem Gangwechsel über Lenkrad Tip-Up oder Gangwahlhebel falls dieser in Tippgasse.
Nur AUDI RS-Modelle!";
CM_ SG_ 327 MO_Schaltblitz_Anz "Signalisierung der drehzahlabhängigen Schaltblitzanzeige im Kombiinstrument (0-100%)";

CM_ SG_ 1601 MO_Ansaugsystem "Art des Ansaugsystems des Verbrennungsmotors";
CM_ SG_ 1601 MO_Anzahl_Zyl "Zylinderzahl des Verbrennungsmotors";
CM_ SG_ 1601 MO_Anzeige_StSt_gueltig "Zeigt die Gültigkeit der neuen StSt-Anzeigesignale an, MO_Anzeige_StSt_Text und  MO_Anzeige_Symbol. Mo_Text_Motorstart 1..5 sind zu ignorieren.";
CM_ SG_ 1601 MO_Code "Motorcodierinformation Version 16 (Details siehe Anhang)";
CM_ SG_ 1601 MO_DPF_verbaut "Verbauinformation Diesel-Partikel-Filter
";
CM_ SG_ 1601 MO_Faktor_Momente_02 "Dieses Signal schaltet den Wertebereich aller Momente vom Motor, Getriebe, TSK, Bremse ... um! Die Momente besitzen somit einen variablen Wertebereich, weil sich durch den Faktor die Momente sowohl in Auflösung als auch Maximalwerten ändert.

0x0 nicht ";
CM_ SG_ 1601 MO_Getriebe_Code "Getriebecodierung des Motors";
CM_ SG_ 1601 MO_Hubraum "Hubraum des Verbrennungsmotors";
CM_ SG_ 1601 MO_Hybridfahrzeug "Anhand dieses Signals plausibilisiert die Lenkhilfe das Bit Fahrbereitschaft.

Im Projekt Cayenne PHEV (und ggf. auch VW526 PHEV) ist aus Gründen der Abwärtskompatibilität der Wert '2' zu senden.";
CM_ SG_ 1601 MO_Kraftstoffart "Primärkraftstoff zum Antrieb des Fahrzeugs";
CM_ SG_ 1601 MO_Leistung "Nennleistung des Verbrennungsmotors

Im reinen E-Fahrzeug (BEV): Ausgabe der elektrischen Systemleistung";
CM_ SG_ 1601 MO_OBD_Typ "Abgastyp OBD
Hinweis: In Fahrzeugen mit dem Zielmarkt China und einer Zertifizierung ab China 6 muss auf dem Signal 'MO_OBD_Typ' der Wert 'US_OBD' gesendet werden.";
CM_ SG_ 1601 MO_StartStopp_Codiert "Funktion StartStopp im aktuellen Klemmenzyklus verbaut";
CM_ SG_ 1601 Motor_Code_01_CRC "Für MLB:
'Berechnung siehe Lastenheft 'Kommunikationsabsicherung für FlexRay und CAN''

Ab MQB und MLBevo:
'Berechnung siehe Lastenheft 'End-to-End Kommunikationsabsicherung''

Endwerte siehe Begleitdokument 'S-PDU Kennungsfolgen'";
CM_ SG_ 1601 TSK_Codierung "Information über den plausibilisierten Codierungszustand des Triebstrangskoordinators auf ACC oder GRA.";

CM_ SG_ 391 EV_Rekuperationsstufe "Im Kombi anzuzeigende Rekuperationsstufe";
CM_ SG_ 391 MO_Drehzahl_VM "Motordrehzahl des Verbrennungsmotors

für OBD freeze frame

Hinweis: 
Ehemaliger Fehlerwert 0xFFFF wird senderseitig nicht unterstützt. 
Diesen Wert aus Kompatibilitätsgründen nicht neu belegen!";
CM_ SG_ 391 MO_Fehler_Notabschaltung_Klima "Das Signal dient der schnellen Abschaltung der Klimakomponenten (EKK, HV-Heizung) durch den HV-Koordinator (MSG) nach einem HV-Interlock Ereignis.";
CM_ SG_ 391 MO_Fehler_NTKreis "Fehlerstatus Niedertemperaturkreis";
CM_ SG_ 391 MO_KLE_FStatus "Fehlerstatus der Kühlerlüfterelektronik";
CM_ SG_ 391 MO_Tankbereitschaft_Status "Meldung der Tankbereitschaft";
CM_ SG_ 391 MO_Tankklappensteuerung "Ansteuerungsanforderung der Tankklappe";
CM_ SG_ 391 MO_Waehlpos "Wählhebelposition (im VW120/7 und MQB BEV ist der Wählhebel am HCAN mit Master Motor-SG angeschlossen)

(wenn das Signal zusätzlich in Botschaft MSG_HYB_03 verortet ist, gilt: Signal nur in der CAN-Welt PQ35/25 zu verwenden, da dort am ACAN die Wählhebe";
CM_ SG_ 391 MO_WH_Texte "Fahrerhinweise für das Kombi";
CM_ SG_ 391 Motor_EV_01_BZ "Fehlende Beschreibung (Import)";
CM_ SG_ 391 Motor_EV_01_CRC "Für MLB:
'Berechnung siehe Lastenheft 'Kommunikationsabsicherung für FlexRay und CAN''

Ab MQB und MLBevo:
'Berechnung siehe Lastenheft 'End-to-End Kommunikationsabsicherung''

Endwerte siehe Begleitdokument 'S-PDU Kennungsfolgen'";

CM_ SG_ 813 MO_akt_Betrieb "Motor läuft aktuell im Benzin- oder Gasbetrieb";
CM_ SG_ 813 MO_AnzeigeGasbetrieb "Anzeige des Betriebszustands bei Umschaltung zwischen Gas- und Benzinbetrieb";
CM_ SG_ 813 MO_CNG_Tankstopp "Der CNG-Tankalgorithmus hat einen Tankstopp (CNG-Tank) erkannt.
Bei separatem CNG-SG gatet das MSG die Information.";
CM_ SG_ 813 MO_CNG_Ueberlauf "Der motorsteuergeräteinterne Verbrauchszähler ist mindestens einmal übergelaufen. Dieses Bit wird genutzt, um erkennen zu können, dass das Motorsteuergerät aus dem Reset-Zustand hochläuft.";
CM_ SG_ 813 MO_Erdgasqualitaet "Erdgas-Qualität abgestuft in 70%, 80%, 90% und 100% (bei CNG bezogen auf 100% Methan). Berechnung erfolgt einmalig nach jeder Betankungserkennung.";
CM_ SG_ 813 MO_Fuellstand_LPG "Tankfüllstand LPG (Sensor am MSG/LPG-SG)";
CM_ SG_ 813 MO_Fuellungsgrad_CNG "Gefilterter temperaturkompensierter Gasdruckwert als Prozentwert vom Maximalwert wird im Kombi als Zeiger dargestellt.";
CM_ SG_ 813 MO_Fuellungsgrad_LPG "Füllungsgrad des LPG-Tanks in %";
CM_ SG_ 813 MO_LPG_Tankstopp "Der LPG-Tankalgorithmus hat einen Tankstopp (LPG-Tank) erkannt.
Bei separatem LPG-SG gatet das MSG die Information.";
CM_ SG_ 813 MO_LPG_Ueberlauf "Der motorsteuergeräteinterne Verbrauchszähler ist mindestens einmal übergelaufen. Dieses Bit wird genutzt, um erkennen zu können, dass das Motorsteuergerät aus dem Reset-Zustand hochläuft.";
CM_ SG_ 813 MO_Tankmasse_CNG "Max. Tankmasse in kg bei einem Tankdruck von 200bar, in Abhängigkeit vom max. Tankvolumen und der CNG-Tanktemperatur beim Befüllen (Verwendung im Kombi zur Reichweitenberechnung)";
CM_ SG_ 813 MO_Tankvolumen_LPG "Volumen des LPG-Tanks";
CM_ SG_ 813 MO_Verbrauch_CNG "Motorsteuergeräteinterner Verbrauchszähler, der vom Kombi zyklisch ausgelesen wird, um die Gasmenge zur Verbrauchsberechnung aufzusummieren; aus diesem Zählerstand werden Momentan- und Durchschnittsverbrauch berechnet; das Überlauf-Bit ist zu berücksichti";
CM_ SG_ 813 MO_Verbrauch_LPG "Motorsteuergeräteinterner Verbrauchszähler, der vom Kombi zyklisch ausgelesen wird, um die Gasmenge zur Verbrauchsberechnung aufzusummieren; aus diesem Zählerstand werden Momentan- und Durchschnittsverbrauch berechnet; das Überlauf-Bit ist zu berücksichti";
CM_ SG_ 813 MO_Verbrauchsaequivalent "Faktor zur Umrechnung des aktuellen/letzten Verbrauchs im LPG/CNG-Betrieb auf einen äquivalenten Benzin-Verbrauch (zur Ermittlung der Gesamtreichweite)";

CM_ SG_ 2589284112 MO_VTD_CDEODT_L "zurückgelegte Strecke insg. im Betrieb bei Entladung bei abgeschaltetem Motor

(Vehicle Tracking Data:Total distance traveled in charge depleting operation with engine off (Lifetime))";
CM_ SG_ 2589284112 MO_VTD_TD_L "zurückgelegte Strecke insgesamt

(Vehicle Tracking Data:Total Distance Traveled (Lifetime))";

CM_ SG_ 2589284113 SOK_Motor_VTD_01_Signatur "Signatur im Rahmen der durch SOK geschützten Broadcast-Kommunikation

Geschützte Funktion: PHEV
Geschützte Botschaft: Motor_VTD_01";

CM_ SG_ 2589284114 MO_VTD_CDERDT_L "zurückgelegte Strecke insg. im Betrieb bei Entladung bei eingeschaltetem Motor

(Vehicle Tracking Data: Total distance traveled in charge depleting operation with engine running (Lifetime))";
CM_ SG_ 2589284114 MO_VTD_CDFC_L "Kraftstoffverbrauch insgesamt im Betrieb bei Entladung

(Vehicle Tracking Data: Total fuel consumed in charge depleting operation (Lifetime))";

CM_ SG_ 2589284115 SOK_Motor_VTD_02_Signatur "Signatur im Rahmen der durch SOK geschützten Broadcast-Kommunikation

Geschützte Funktion: PHEV
Geschützte Botschaft: Motor_VTD_02";

CM_ SG_ 2589284116 MO_VTD_CIDT_L "zurückgelegte Strecke insg. im vom Fahrer wählbaren Betrieb der Ladungserhöhung

(Vehicle Tracking Data: Total distance traveled in driver-selectable charge increasing operation (Lifetime))";
CM_ SG_ 2589284116 MO_VTD_GE_L "der Batterie zugeführte Netzenergie insgesamt

(Vehicle Tracking Data: Total grid energy into the battery (Lifetime))";

CM_ SG_ 2589284117 SOK_Motor_VTD_03_Signatur "Signatur im Rahmen der durch SOK geschützten Broadcast-Kommunikation

Geschützte Funktion: PHEV
Geschützte Botschaft: Motor_VTD_03";

CM_ SG_ 2589284118 MO_VTD_CIFC_L "Kraftstoffverbrauch insgesamt im vom Fahrer wählbaren Betrieb der Ladungserhöhung.

(Vehicle Tracking Data: Total fuel consumed in driver-selectable charge increasing operation (Lifetime))";
CM_ SG_ 2589284118 MO_VTD_FC_L "Kraftstoffverbrauch insgesamt

(Vehicle Tracking Data: Total fuel consumed (Lifetime))";

CM_ SG_ 2589284119 SOK_Motor_VTD_04_Signatur "Signatur im Rahmen der durch SOK geschützten Broadcast-Kommunikation

Geschützte Funktion: PHEV
Geschützte Botschaft: Motor_VTD_04";

CM_ SG_ 2583737729 NAD_AuthTime_SSN_Req_Data "AuthTime - Authentische Zeit
ISO-TP Datenkanal - NA2FID

ConMod_NAD an Funktion Authentische Zeit (Request)";

CM_ SG_ 2583868801 NAD_AuthTime_SSN_Resp_Data "AuthTime - Authentische Zeit
ISO-TP Datenkanal - NA2FID
Response Funktion 0x18 AuthTime

Funktion Authentische Zeit an ConMod_NAD (Response)";

CM_ SG_ 1156 ND_GDOP "geometric dilution of precision (Gesamtgenauigkeit, 3D und Zeit) 
";
CM_ SG_ 1156 ND_HDOP "horizontal dilution of precision (Horizontalrichtung, 2D)
";
CM_ SG_ 1156 ND_Heading "Fahrtrichtung";
CM_ SG_ 1156 ND_Init "Initialisierung";
CM_ SG_ 1156 ND_PDOP "positional dilution of precision (Positionsgenauigkeit, 3D) 
";
CM_ SG_ 1156 ND_TDOP "time dilution of precision (Zeitgenauigkeit)
";
CM_ SG_ 1156 ND_VDOP "vertical dilution of precision (Vertikalrichtung, 1D)
";

CM_ SG_ 1157 ND_SatInUse "Anzahl der zur Berechnung verwendeten Satelliten";
CM_ SG_ 1157 ND_SatInView "Anzahl der sichtbaren Satelliten";
CM_ SG_ 1157 ND_UTC "UTC-Zeit, verstrichene Sekunden seit 01.01.1970 00:00
0xFFFFFFFE = Init
0xFFFFFFFF = Fehler bei Berechnung der UTC-Time";
CM_ SG_ 1157 NP_Altitude "Hoehe ueber NN
0xFFF = Fehler bei der Berechnung der Höhe über NN";
CM_ SG_ 1157 POS_Guete_horizontal "Horizontale Genauigkeit der Position in der Botschaft NavPos_02_MapMatched (Signale
POS_LatDegree, POS_LongDegree)

Abhängig vom Signal
POS_Guete_horizontal_verfuegbar";
CM_ SG_ 1157 POS_Guete_horizontal_verfuegbar "Bei gesetztem Bit wird das Signal POS_Guete_horizontal befüllt und ist verfügbar.";

CM_ SG_ 2527679512 ND_Fuelstation_detected "Signal gibt an ob eine Tankstelle erkannt wurde";
CM_ SG_ 2527679512 ND_NrSameMeasure "GPS Anzahl der gleichen Messungen";
CM_ SG_ 2527679512 ND_RecDelay "Für MLBevo:
Zeit in ms zwischen zwei Interruptauslösungen des GPS Receiver.

Für MLBevoGen2:
Zeit in ms zwischen UTC-Sekunde und Messzeitpunkt des GPS Receiver.";
CM_ SG_ 2527679512 ND_RouteType "Routentyp.";
CM_ SG_ 2527679512 ND_SendDelay "Zeit in ms zwischen Interruptauslösung GPS Receiver (Beginn der Messung) und Senden auf den CAN Bus.";
CM_ SG_ 2527679512 ND_TimeOffset "Offset zu ND_TimeToDestination.";
CM_ SG_ 2527679512 ND_TimeToDestination "Zeit in min bis zum Erreichen des Ziel. Wird ausgegeben bei aktiver Routenführung oder bei gelernter Route (MPR).";
CM_ SG_ 2527679512 ND_Timezone_DaylightSavingOffset "Offest der Sommerzeit/Winterzeit
 
0 = kein Offset ; 
1 = 0,5h;  
2 = 1h";
CM_ SG_ 2527679512 ND_Timezone_Offset "Aktuelle Zeitzonen-Offset des Fahrzeugs.
Vorzeichen und Gültigkeit beachten";
CM_ SG_ 2527679512 ND_Timezone_SignBit "Vorzeichen des Zeitzonenoffsets.";
CM_ SG_ 2527679512 ND_Timezone_Validity "Gültigkeit des Zeitzonensignals.";
CM_ SG_ 2527679512 ND_Velocity "GPS Geschwindigkeit";

CM_ SG_ 2527679665 ND_Avrg_Speed_RangeData "Durchschnittsgeschwindigkeit der aktuell befahrenen Strassenkante (Ist-Position Fahrzeug) fuer die Berechnung der routenbasierenden Reichweite.";
CM_ SG_ 2527679665 ND_PSD_Street_Category "The navigation system shall sent the street category for the current car position within the CAN signal ND_PSD_Street_Category.
The street category shall correspond to the category sent in the signal PSD_Strassenkategorie for this position.";

CM_ SG_ 2527679770 NavMan_ApproachDistanceInPercent "The distance to the maneuver point within the approach range as defined by the service for each maneuver. 100 = maximum distance to the maneuver within the approaching range, 0 = maneuver point reached.";
CM_ SG_ 2527679770 NavMan_DirectionType "The direction type of the maneuver
0 -> Straight
64 -> Left
128 -> Back
192 -> Right";
CM_ SG_ 2527679770 NavMan_Distance "Maneouvering Information for brand specific (SEAT) lighting events";
CM_ SG_ 2527679770 NavMan_Distance_Unit "Maneouvering Information for brand specific (SEAT) lighting events";
CM_ SG_ 2527679770 NavMan_MainType "The type of the requested maneuver encoded in a integer.";

CM_ SG_ 1158 NP_LatDegree "Latitude (Nord-Süd Wert)";
CM_ SG_ 1158 NP_LatDirection "Hemisphäre Nord/Süd";
CM_ SG_ 1158 NP_LongDegree "Longitude (Ost-West Wert)";
CM_ SG_ 1158 NP_LongDirection "Hemisphäre Ost/West";
CM_ SG_ 1158 NP_Sat "Nummer der verwendeten Sateliten beim letzten Fix";

CM_ SG_ 2589283496 POS_Heading "Heading of current position
MUX(1)";
CM_ SG_ 2589283496 POS_Heading_Trust "Vertrauenswert Heading 
MUX(1) ";
CM_ SG_ 2589283496 POS_Last_GPS_Sync "Letztes bekannte GPS Sync in [s]
MUX(1)";
CM_ SG_ 2589283496 POS_LatDegree "latitude - position data of navigation
MUX(0)";
CM_ SG_ 2589283496 POS_LatDirection "latitude direction nav position
MUX(0)";
CM_ SG_ 2589283496 POS_LongDegree "long - position data of navigation
MUX(0)";
CM_ SG_ 2589283496 POS_LongDirection "longitude direction nav position
MUX(0)";
CM_ SG_ 2589283496 POS_MUX "Multiplex-Signal zum schalten des Signals der Positionen von der Navigation.
MUX(0/1)";
CM_ SG_ 2589283496 POS_ODD_EVEN "Synchronisation der MUX Pos Signale
MUX(0/1)";
CM_ SG_ 2589283496 POS_PosStati "Aktueller Status der Navgation:
MUX(0)
0   init
1   no nav available (ready_4_nav)
2   no map available (sd_removed, not_enabled)
3   nav booting
4   nav error
5   nav calibrating
6   nav no gps resync since 1h
7   nav offroad  parkgarage ramp of";
CM_ SG_ 2589283496 POS_UTC_REF "Zeitstempel der Nav
MUX(1)

UTC-Zeit, verstrichene Sekunden seit 01.01.1970 00:00
0xFFFFFFFE = Init
0xFFFFFFFF = Fehler bei Berechnung der UTC-Time

Signal wird nur bei aktiver Navigation-Funktion zyklisch gesendet.";

CM_ SG_ 2527679645 NFC_MiKo_ESM_aktiv "Energiesparmodus ist aktiv, z.B. nach 72h Fahrzeugstillstand";
CM_ SG_ 2527679645 NFC_MiKo_Fehler "Das Steuergeraet hat einen Fehler und ist nicht komplett einsatzfaehig.";
CM_ SG_ 2527679645 NFC_MiKo_Laden_unterbrechen "Anforderung seitens Mittelkonsolen-STG das Laden in der Phonebox zu unterbrechen";
CM_ SG_ 2527679645 NFC_MiKo_NFC_Device_gekoppelt "Ein NFC-Device ist im Empfangsbereich und der NFC-Reader hat eine aktive Verbindung aufgebaut.";
CM_ SG_ 2527679645 NFC_MiKo_NFC_Device_Status "Status der aktuellen NFC Erkennung";

CM_ SG_ 2600468788 NM_BedienDisp_m_CAB_V14 "CAB = Clusteraktivbits (V14)";
CM_ SG_ 2600468788 NM_BedienDisp_m_Car_Wakeup "Car Wakeup (Busmaster wertet aus)";
CM_ SG_ 2600468788 NM_BedienDisp_m_CBV_AWB "Das Signal ist zu setzen, wenn das SG aktiv den Bus geweckt hat
0 = Passiver_WakeUp = SG hat das Netzwerk nicht aktiv geweckt
1 = Akitiver_WakeUp = SG hat das Netzwerk aktiv geweckt";
CM_ SG_ 2600468788 NM_BedienDisp_m_CBV_CRI "Das Signal ist dauerhaft gesetzt, wenn das NM-Layout Cluster- Anforderungen enthält";
CM_ SG_ 2600468788 NM_BedienDisp_m_NM_aktiv_Diagnos "Diagnose befindet sich nach VW80124 in einer NonDefaultDiagnostic-Session, z.B. ExtendedDiagnostic-Session";
CM_ SG_ 2600468788 NM_BedienDisp_m_NM_aktiv_KL15 "Steuergerät hat KL15-EIN erkannt";
CM_ SG_ 2600468788 NM_BedienDisp_m_NM_aktiv_Tmin "Mindestaktivzeit ist noch nicht abgelaufen (bei jedem Weckereignis wird die Mindestaktivzeit neu gestartet)";
CM_ SG_ 2600468788 NM_BedienDisp_m_NM_State "1 = Zustand Repeat Message (<-- Bus-Sleep Mode)
2 = Zustand Repeat Message (<-- Prepare Bus-Sleep Mode)
4 = Zustand Normal Operation (<-- Repeat Message)
8 = Zustand Normal Operation (<-- Ready Sleep)";
CM_ SG_ 2600468788 NM_BedienDisp_m_UDS_CC "Funktionseinschränkung aufgrund aktivem UDS-Communication Control; siehe VW80124";

CM_ SG_ 2600468642 NM_BedienDisp_vm_CAB_V14 "CAB = Clusteraktivbits (V14)";
CM_ SG_ 2600468642 NM_BedienDisp_vm_Car_Wakeup "Car Wakeup (Gateway wertet aus)";
CM_ SG_ 2600468642 NM_BedienDisp_vm_CBV_AWB "Das Signal ist zu setzen, wenn das SG aktiv den Bus geweckt hat";
CM_ SG_ 2600468642 NM_BedienDisp_vm_CBV_CRI "Das Signal ist dauerhaft gesetzt, wenn das NM-Layout dem neuen NM-Layout für Teilnetzbetrieb entspricht";
CM_ SG_ 2600468642 NM_BedienDisp_vm_NM_aktiv_Diag "Diagnose befindet sich nach VW80124 in einer NonDefaultDiagnostic-Session, z.B. ExtendedDiagnostic-Session";
CM_ SG_ 2600468642 NM_BedienDisp_vm_NM_aktiv_KL15 "Steuergerät hat KL15-EIN erkannt";
CM_ SG_ 2600468642 NM_BedienDisp_vm_NM_aktiv_Tmin "Mindestaktivzeit ist noch nicht abgelaufen (bei jedem Weckereignis wird die Mindestaktivzeit neu gestartet)";
CM_ SG_ 2600468642 NM_BedienDisp_vm_NM_State "1 = Zustand Repeat Message (<-- Bus-Sleep Mode)
2 = Zustand Repeat Message (<-- Prepare Bus-Sleep Mode)
4 = Zustand Normal Operation (<-- Repeat Message)
8 = Zustand Normal Operation (<-- Ready Sleep)";
CM_ SG_ 2600468642 NM_BedienDisp_vm_UDS_CC "Funktionseinschränkung aufgrund aktivem UDS-Communication Control, siehe VW80124";

CM_ SG_ 2600468583 NM_eCall_CAB_V14 "Cluster - CAB_02
OCU/ConMod: Laden (Lan-/ausschalten)
OCU: Programmierung eines Fzg.systems z.B. LMM
ConMod: PSO- Übernahme Nutzeränd. (max 60s nach KL15-Aus)
OCU/ConMod: Klimatisierung an oder ausschalten
Cluster - CAB_04
ConMod: PSO- Übernahme Nut";
CM_ SG_ 2600468583 NM_eCall_Car_Wakeup "Car Wakeup (Gateway wertet aus)
MQB:
-Laden an/aus, Klimatisieren an/aus, Programmieren, Abfrage Fahrzeugstatus/Batteriestatus, Anruf aktiv (max 10 Min).
-IAA: Identifizieren, Authentisieren, Autorisieren - Nutzeridentifikation/ Management (max. 10sec)";
CM_ SG_ 2600468583 NM_eCall_CBV_AWB "Das Signal ist zu setzen, wenn das SG aktiv den Bus geweckt hat
0 = Passiver_WakeUp = SG hat das Netzwerk nicht aktiv geweckt
1 = Akitiver_WakeUp = SG hat das Netzwerk aktiv geweckt";
CM_ SG_ 2600468583 NM_eCall_CBV_CRI "Das Signal ist dauerhaft gesetzt, wenn das NM-Layout Cluster- Anforderungen enthält";
CM_ SG_ 2600468583 NM_eCall_NM_aktiv_Call "Anruf aktiv (Automatic Crash Notification, Manual Emergency Call, Concierge Information Call, Roadside Assistance Call)";
CM_ SG_ 2600468583 NM_eCall_NM_aktiv_Diagnose "Diagnose befindet sich nach VW80124 in einer NonDefaultDiagnostic-Session, z.B. ExtendedDiagnostic-Session";
CM_ SG_ 2600468583 NM_eCall_NM_aktiv_Dienstabfrage "Nach Ausschalten der Klemme 15 werden erst alle Dienste in der OCU-SW abgefragt, bevor die CAN Kommunikation beendet wird. (Das hat nichts mit den Online-Diensten zu tun).
Die Abfrage dauert normalerweise ca. 1s.
Spätestens nach 5s ist die Abfrage beend";
CM_ SG_ 2600468583 NM_eCall_NM_aktiv_IAA "IAA: Nutzeridentifikation/ Management ist aktiv";
CM_ SG_ 2600468583 NM_eCall_NM_aktiv_KL15 "Steuergerät hat KL15-EIN erkannt";
CM_ SG_ 2600468583 NM_eCall_NM_aktiv_Klimatisieren "Klimatisieren aktiv";
CM_ SG_ 2600468583 NM_eCall_NM_aktiv_Laden "Laden an/aus, Abfrage SOC";
CM_ SG_ 2600468583 NM_eCall_NM_aktiv_MQTT_GW "MQTT Gateway ist aktiv";
CM_ SG_ 2600468583 NM_eCall_NM_aktiv_ORU_OCU "Anforderung PopUp für ORU der OCU";
CM_ SG_ 2600468583 NM_eCall_NM_aktiv_PSO "Personalisierung benötigt Kommunikation (nur ConMod)";
CM_ SG_ 2600468583 NM_eCall_NM_aktiv_Remote_Control "Remote Control aktiv";
CM_ SG_ 2600468583 NM_eCall_NM_aktiv_RemoteStart "RemoteStart aktiv";
CM_ SG_ 2600468583 NM_eCall_NM_aktiv_RPA "RPA Funktion benötigt Kommunikation";
CM_ SG_ 2600468583 NM_eCall_NM_aktiv_Settings "Settings aktiv";
CM_ SG_ 2600468583 NM_eCall_NM_aktiv_Status "Statusabfrage aktiv";
CM_ SG_ 2600468583 NM_eCall_NM_aktiv_Tmin "Mindestaktivzeit ist noch nicht abgelaufen (bei jedem Weckereignis wird die Mindestaktivzeit neu gestartet)";
CM_ SG_ 2600468583 NM_eCall_NM_State "1 = Zustand Repeat Message (<-- Bus-Sleep Mode)
2 = Zustand Repeat Message (<-- Prepare Bus-Sleep Mode)
4 = Zustand Normal Operation (<-- Repeat Message)
8 = Zustand Normal Operation (<-- Ready Sleep)";
CM_ SG_ 2600468583 NM_eCall_UDS_CC "Funktionseinschränkung aufgrund aktivem UDS-Communication Control, siehe VW80124";
BA_DEF_REL_ BU_SG_REL_  "GenSigTimeoutTime" INT 0 65535;
BA_DEF_ BO_  "DiagRequest" ENUM "No", "Yes";
BA_DEF_ BO_  "DiagResponse" ENUM "No", "Yes";
BA_DEF_ BO_  "DiagState" ENUM "No", "Yes";
BA_DEF_ BO_  "GenMsgChkConstant" HEX 0 4095;
BA_DEF_ BO_  "GenMsgCycleTime" INT 0 65535;
BA_DEF_ BO_  "GenMsgCycleTimeFast" INT 0 65535;
BA_DEF_ BO_  "GenMsgDelayTime" INT 0 100000;
BA_DEF_ BO_  "GenMsgILSupport" ENUM "No", "Yes";
BA_DEF_ BO_  "GenMsgNrOfRepetition" INT 0 100;
BA_DEF_ BO_  "GenMsgPDUConstants" STRING;
BA_DEF_ BO_  "GenMsgSendType" ENUM "Cyclic", "not_used", "not_used", "not_used", "not_used", "not_used", "not_used", "IfActive", "NoMsgSendType";
BA_DEF_ BO_  "GenMsgStartDelayTime" INT 0 100000;
BA_DEF_ BO_  "NmMessage" ENUM "No", "Yes";
BA_DEF_ BO_  "NmhMessage" ENUM "No", "Yes";
BA_DEF_ BO_  "MsgType" ENUM "Application", "NM ", "NMH", "TP2.0", "ISO-TP ", "BAP", "EID", "KS", "XCP_PRE_CONFIGURED", "XCP_RUNTIME_CONFIGURED";
BA_DEF_ BO_  "VAGTP20_API" HEX 0 255;
BA_DEF_ BO_  "VAGTP20_DynConnection" ENUM "No", "Yes";
BA_DEF_ BO_  "VAGTP20_DynSetup" ENUM "No", "Yes";
BA_DEF_ BO_  "VAGTP20_StatConnection" ENUM "No", "Yes";
BA_DEF_ SG_  "GenSigActiveRepetitions" INT -2147483648 2147483647;
BA_DEF_ SG_  "GenSigInactiveValue" INT -2147483648 2147483647;
BA_DEF_ SG_  "GenSigSendType" ENUM "Cyclic", "OnWrite", "OnWriteWithRepetition", "OnChange", "OnChangeWithRepetition", "IfActive", "IfActiveWithRepetition", "NoSigSendType", "OnChangeAndIfActive", "OnChangeAndIfActiveWithRepetition";
BA_DEF_ SG_  "GenSigStartValue" INT -2147483648 2147483647;
BA_DEF_ SG_  "NWM-WakeupAllowed" ENUM "No", "Yes";
BA_DEF_ SG_  "GenSigFuncType" ENUM "NoFunction", "MsgCounter", "CRC-8", "XOR", "XOR-2", "DatedBit", "SW-Kl15", "CHK", "Constant", "Protocol", "CRC-8-SAE_J1850", "CRC-32", "DataLength", "DataID", "MsgCounter16", "SOK-Signatur", "Cluster";
BA_DEF_ SG_  "GenSigSwitchedByIgnition" ENUM "No", "Yes";
BA_DEF_ SG_  "Fehlerwert" HEX 0 2147483647;
BA_DEF_ SG_  "GenSigMissingSourceValue" HEX 0 2147483647;
BA_DEF_DEF_REL_  "GenSigTimeoutTime" 0;
BA_DEF_DEF_  "DiagRequest" "No";
BA_DEF_DEF_  "DiagResponse" "No";
BA_DEF_DEF_  "DiagState" "No";
BA_DEF_DEF_  "GenMsgChkConstant" 0;
BA_DEF_DEF_  "GenMsgCycleTime" 0;
BA_DEF_DEF_  "GenMsgCycleTimeFast" 0;
BA_DEF_DEF_  "GenMsgDelayTime" 0;
BA_DEF_DEF_  "GenMsgILSupport" "No";
BA_DEF_DEF_  "GenMsgNrOfRepetition" 0;
BA_DEF_DEF_  "GenMsgPDUConstants" "";
BA_DEF_DEF_  "GenMsgSendType" "NoMsgSendType";
BA_DEF_DEF_  "GenMsgStartDelayTime" 0;
BA_DEF_DEF_  "NmMessage" "No";
BA_DEF_DEF_  "NmhMessage" "No";
BA_DEF_DEF_  "MsgType" "Application";
BA_DEF_DEF_  "VAGTP20_API" 0;
BA_DEF_DEF_  "VAGTP20_DynConnection" "No";
BA_DEF_DEF_  "VAGTP20_DynSetup" "No";
BA_DEF_DEF_  "VAGTP20_StatConnection" "No";
BA_DEF_DEF_  "GenSigActiveRepetitions" 0;
BA_DEF_DEF_  "GenSigInactiveValue" 0;
BA_DEF_DEF_  "GenSigSendType" "NoSigSendType";
BA_DEF_DEF_  "GenSigStartValue" 0;
BA_DEF_DEF_  "NWM-WakeupAllowed" "No";
BA_DEF_DEF_  "GenSigFuncType" "NoFunction";
BA_DEF_DEF_  "GenSigSwitchedByIgnition" "Yes";
BA_DEF_DEF_  "Fehlerwert" 0;
BA_DEF_DEF_  "GenSigMissingSourceValue" 0;
BA_ "GenMsgCycleTime" BO_ 263 20;
BA_ "GenMsgILSupport" BO_ 263 1;
BA_ "GenMsgSendType" BO_ 263 0;
BA_ "GenMsgCycleTime" BO_ 1600 500;
BA_ "GenMsgILSupport" BO_ 1600 1;
BA_ "GenMsgSendType" BO_ 1600 0;
BA_ "GenMsgCycleTime" BO_ 1607 500;
BA_ "GenMsgILSupport" BO_ 1607 1;
BA_ "GenMsgSendType" BO_ 1607 0;
BA_ "GenMsgCycleTime" BO_ 167 20;
BA_ "GenMsgILSupport" BO_ 167 1;
BA_ "GenMsgSendType" BO_ 167 0;
BA_ "GenMsgCycleTime" BO_ 958 100;
BA_ "GenMsgDelayTime" BO_ 958 10;
BA_ "GenMsgILSupport" BO_ 958 1;
BA_ "GenMsgPDUConstants" BO_ 958 "0x1f,0x28,0xc6,0x85,0xe6,0xf8,0xb0,0x19,0x5b,0x64,0x35,0x21,0xe4,0xf7,0x9c,0x24";
BA_ "GenMsgSendType" BO_ 958 0;
BA_ "GenMsgCycleTime" BO_ 1631 500;
BA_ "GenMsgILSupport" BO_ 1631 1;
BA_ "GenMsgSendType" BO_ 1631 0;
BA_ "GenMsgCycleTime" BO_ 1648 500;
BA_ "GenMsgDelayTime" BO_ 1648 20;
BA_ "GenMsgILSupport" BO_ 1648 1;
BA_ "GenMsgSendType" BO_ 1648 0;
BA_ "GenMsgCycleTime" BO_ 289 20;
BA_ "GenMsgILSupport" BO_ 289 1;
BA_ "GenMsgSendType" BO_ 289 0;
BA_ "GenMsgCycleTime" BO_ 1391 500;
BA_ "GenMsgILSupport" BO_ 1391 1;
BA_ "GenMsgSendType" BO_ 1391 0;
BA_ "GenMsgCycleTime" BO_ 967 100;
BA_ "GenMsgILSupport" BO_ 967 1;
BA_ "GenMsgSendType" BO_ 967 0;
BA_ "GenMsgCycleTime" BO_ 327 20;
BA_ "GenMsgILSupport" BO_ 327 1;
BA_ "GenMsgSendType" BO_ 327 0;
BA_ "GenMsgChkConstant" BO_ 1601 71;
BA_ "GenMsgCycleTime" BO_ 1601 1000;
BA_ "GenMsgILSupport" BO_ 1601 1;
BA_ "GenMsgPDUConstants" BO_ 1601 "0x47,0x47,0x47,0x47,0x47,0x47,0x47,0x47,0x47,0x47,0x47,0x47,0x47,0x47,0x47,0x47";
BA_ "GenMsgSendType" BO_ 1601 0;
BA_ "GenMsgCycleTime" BO_ 391 100;
BA_ "GenMsgDelayTime" BO_ 391 40;
BA_ "GenMsgILSupport" BO_ 391 1;
BA_ "GenMsgPDUConstants" BO_ 391 "0x7f,0xed,0x17,0xc2,0x7c,0xeb,0x44,0x21,0x01,0xfa,0xdb,0x15,0x4a,0x6b,0x23,0x05";
BA_ "GenMsgSendType" BO_ 391 0;
BA_ "GenMsgCycleTime" BO_ 813 50;
BA_ "GenMsgILSupport" BO_ 813 1;
BA_ "GenMsgSendType" BO_ 813 0;
BA_ "GenMsgCycleTime" BO_ 2589284112 2000;
BA_ "GenMsgILSupport" BO_ 2589284112 1;
BA_ "GenMsgSendType" BO_ 2589284112 0;
BA_ "GenMsgCycleTime" BO_ 2589284113 2000;
BA_ "GenMsgSendType" BO_ 2589284113 0;
BA_ "GenMsgCycleTime" BO_ 2589284114 2000;
BA_ "GenMsgILSupport" BO_ 2589284114 1;
BA_ "GenMsgSendType" BO_ 2589284114 0;
BA_ "GenMsgCycleTime" BO_ 2589284115 2000;
BA_ "GenMsgSendType" BO_ 2589284115 0;
BA_ "GenMsgCycleTime" BO_ 2589284116 2000;
BA_ "GenMsgILSupport" BO_ 2589284116 1;
BA_ "GenMsgSendType" BO_ 2589284116 0;
BA_ "GenMsgCycleTime" BO_ 2589284117 2000;
BA_ "GenMsgSendType" BO_ 2589284117 0;
BA_ "GenMsgCycleTime" BO_ 2589284118 2000;
BA_ "GenMsgILSupport" BO_ 2589284118 1;
BA_ "GenMsgSendType" BO_ 2589284118 0;
BA_ "GenMsgCycleTime" BO_ 2589284119 2000;
BA_ "GenMsgSendType" BO_ 2589284119 0;
BA_ "MsgType" BO_ 2583737729 4;
BA_ "MsgType" BO_ 2583868801 4;
BA_ "GenMsgCycleTime" BO_ 1156 200;
BA_ "GenMsgILSupport" BO_ 1156 1;
BA_ "GenMsgSendType" BO_ 1156 0;
BA_ "GenMsgCycleTime" BO_ 1157 200;
BA_ "GenMsgILSupport" BO_ 1157 1;
BA_ "GenMsgSendType" BO_ 1157 0;
BA_ "GenMsgCycleTime" BO_ 2527679512 200;
BA_ "GenMsgILSupport" BO_ 2527679512 1;
BA_ "GenMsgSendType" BO_ 2527679512 0;
BA_ "GenMsgStartDelayTime" BO_ 2527679512 60;
BA_ "GenMsgCycleTime" BO_ 2527679665 200;
BA_ "GenMsgILSupport" BO_ 2527679665 1;
BA_ "GenMsgSendType" BO_ 2527679665 0;
BA_ "GenMsgCycleTime" BO_ 2527679770 200;
BA_ "GenMsgILSupport" BO_ 2527679770 1;
BA_ "GenMsgSendType" BO_ 2527679770 0;
BA_ "GenMsgCycleTime" BO_ 1158 200;
BA_ "GenMsgILSupport" BO_ 1158 1;
BA_ "GenMsgSendType" BO_ 1158 0;
BA_ "GenMsgCycleTime" BO_ 2589283496 500;
BA_ "GenMsgILSupport" BO_ 2589283496 1;
BA_ "GenMsgSendType" BO_ 2589283496 0;
BA_ "GenMsgCycleTime" BO_ 2527679645 200;
BA_ "GenMsgILSupport" BO_ 2527679645 1;
BA_ "GenMsgSendType" BO_ 2527679645 0;
BA_ "GenMsgCycleTime" BO_ 2600468788 200;
BA_ "GenMsgCycleTimeFast" BO_ 2600468788 10;
BA_ "NmhMessage" BO_ 2600468788 1;
BA_ "MsgType" BO_ 2600468788 2;
BA_ "GenMsgCycleTime" BO_ 2600468642 200;
BA_ "GenMsgCycleTimeFast" BO_ 2600468642 10;
BA_ "NmhMessage" BO_ 2600468642 1;
BA_ "MsgType" BO_ 2600468642 2;
BA_ "GenMsgCycleTime" BO_ 2600468583 200;
BA_ "GenMsgCycleTimeFast" BO_ 2600468583 10;
BA_ "NmhMessage" BO_ 2600468583 1;
BA_ "MsgType" BO_ 2600468583 2;
BA_ "GenSigSendType" SG_ 263 MO_Anzeigedrehz 0;
BA_ "GenSigSwitchedByIgnition" SG_ 263 MO_Anzeigedrehz 0;
BA_ "GenSigSendType" SG_ 263 MO_Effizienzmodus 0;
BA_ "GenSigSwitchedByIgnition" SG_ 263 MO_Effizienzmodus 0;
BA_ "GenSigSendType" SG_ 263 MO_Fehler_Oeldrucksensor 0;
BA_ "GenSigSwitchedByIgnition" SG_ 263 MO_Fehler_Oeldrucksensor 0;
BA_ "Fehlerwert" SG_ 263 MO_Fehler_Oeldrucksensor 1;
BA_ "GenSigSendType" SG_ 263 MO_Istgang 0;
BA_ "GenSigSwitchedByIgnition" SG_ 263 MO_Istgang 0;
BA_ "GenSigSendType" SG_ 263 MO_KVS 0;
BA_ "GenSigSwitchedByIgnition" SG_ 263 MO_KVS 0;
BA_ "GenSigSendType" SG_ 263 MO_KVS_Ueberlauf 0;
BA_ "GenSigSwitchedByIgnition" SG_ 263 MO_KVS_Ueberlauf 0;
BA_ "GenSigSendType" SG_ 263 MO_Ladedruck 0;
BA_ "GenSigSwitchedByIgnition" SG_ 263 MO_Ladedruck 0;
BA_ "Fehlerwert" SG_ 263 MO_Ladedruck 511;
BA_ "GenSigSendType" SG_ 263 MO_Oeldruck 0;
BA_ "GenSigStartValue" SG_ 263 MO_Oeldruck 254;
BA_ "GenSigSwitchedByIgnition" SG_ 263 MO_Oeldruck 0;
BA_ "Fehlerwert" SG_ 263 MO_Oeldruck 255;
BA_ "GenSigSendType" SG_ 263 MO_rel_Ladedruck 0;
BA_ "GenSigSwitchedByIgnition" SG_ 263 MO_rel_Ladedruck 0;
BA_ "Fehlerwert" SG_ 263 MO_rel_Ladedruck 255;
BA_ "GenSigSendType" SG_ 263 MO_Schaltempf_verfbar 0;
BA_ "GenSigSwitchedByIgnition" SG_ 263 MO_Schaltempf_verfbar 0;
BA_ "GenSigSendType" SG_ 263 MO_Sollgang 0;
BA_ "GenSigSwitchedByIgnition" SG_ 263 MO_Sollgang 0;
BA_ "GenSigSendType" SG_ 1600 MO_Absperrventil_oeffnen 0;
BA_ "GenSigSwitchedByIgnition" SG_ 1600 MO_Absperrventil_oeffnen 0;
BA_ "GenSigSendType" SG_ 1600 MO_aktives_Getriebeheizen 0;
BA_ "GenSigSwitchedByIgnition" SG_ 1600 MO_aktives_Getriebeheizen 0;
BA_ "GenSigSendType" SG_ 1600 MO_Ansaugluft_Temp 0;
BA_ "GenSigStartValue" SG_ 1600 MO_Ansaugluft_Temp 254;
BA_ "GenSigSwitchedByIgnition" SG_ 1600 MO_Ansaugluft_Temp 0;
BA_ "Fehlerwert" SG_ 1600 MO_Ansaugluft_Temp 255;
BA_ "GenSigSendType" SG_ 1600 MO_Getriebe_kuehlen 0;
BA_ "GenSigSwitchedByIgnition" SG_ 1600 MO_Getriebe_kuehlen 0;
BA_ "GenSigSendType" SG_ 1600 MO_Heizungspumpenansteuerung 0;
BA_ "GenSigStartValue" SG_ 1600 MO_Heizungspumpenansteuerung 14;
BA_ "GenSigSwitchedByIgnition" SG_ 1600 MO_Heizungspumpenansteuerung 0;
BA_ "Fehlerwert" SG_ 1600 MO_Heizungspumpenansteuerung 13;
BA_ "GenSigSendType" SG_ 1600 MO_Hoeheninfo 0;
BA_ "GenSigSwitchedByIgnition" SG_ 1600 MO_Hoeheninfo 0;
BA_ "Fehlerwert" SG_ 1600 MO_Hoeheninfo 255;
BA_ "GenSigSendType" SG_ 1600 MO_HYB_Fehler_HV_Netz 0;
BA_ "GenSigSwitchedByIgnition" SG_ 1600 MO_HYB_Fehler_HV_Netz 0;
BA_ "GenSigSendType" SG_ 1600 MO_Kennfeldk 0;
BA_ "GenSigSwitchedByIgnition" SG_ 1600 MO_Kennfeldk 0;
BA_ "GenSigSendType" SG_ 1600 MO_KL15_Abschaltempfehlung 0;
BA_ "GenSigSwitchedByIgnition" SG_ 1600 MO_KL15_Abschaltempfehlung 0;
BA_ "GenSigSendType" SG_ 1600 MO_Kuehlmittel_Temp 0;
BA_ "GenSigStartValue" SG_ 1600 MO_Kuehlmittel_Temp 254;
BA_ "GenSigSwitchedByIgnition" SG_ 1600 MO_Kuehlmittel_Temp 0;
BA_ "Fehlerwert" SG_ 1600 MO_Kuehlmittel_Temp 255;
BA_ "GenSigSendType" SG_ 1600 MO_Mom_Traegheit_02 0;
BA_ "GenSigSwitchedByIgnition" SG_ 1600 MO_Mom_Traegheit_02 0;
BA_ "GenSigSendType" SG_ 1600 MO_Nachlaufzeit_Heizungspumpe 0;
BA_ "GenSigSwitchedByIgnition" SG_ 1600 MO_Nachlaufzeit_Heizungspumpe 0;
BA_ "GenSigSendType" SG_ 1600 MO_Oel_Temp 0;
BA_ "GenSigStartValue" SG_ 1600 MO_Oel_Temp 254;
BA_ "GenSigSwitchedByIgnition" SG_ 1600 MO_Oel_Temp 0;
BA_ "Fehlerwert" SG_ 1600 MO_Oel_Temp 255;
BA_ "GenSigSendType" SG_ 1600 MO_QBit_Ansaugluft_Temp 0;
BA_ "GenSigStartValue" SG_ 1600 MO_QBit_Ansaugluft_Temp 1;
BA_ "GenSigSwitchedByIgnition" SG_ 1600 MO_QBit_Ansaugluft_Temp 0;
BA_ "GenSigSendType" SG_ 1600 MO_QBit_Hoeheninfo 0;
BA_ "GenSigStartValue" SG_ 1600 MO_QBit_Hoeheninfo 1;
BA_ "GenSigSwitchedByIgnition" SG_ 1600 MO_QBit_Hoeheninfo 0;
BA_ "GenSigSendType" SG_ 1600 MO_QBit_Kuehlmittel_Temp 0;
BA_ "GenSigStartValue" SG_ 1600 MO_QBit_Kuehlmittel_Temp 1;
BA_ "GenSigSwitchedByIgnition" SG_ 1600 MO_QBit_Kuehlmittel_Temp 0;
BA_ "GenSigSendType" SG_ 1600 MO_QBit_Oel_Temp 0;
BA_ "GenSigStartValue" SG_ 1600 MO_QBit_Oel_Temp 1;
BA_ "GenSigSwitchedByIgnition" SG_ 1600 MO_QBit_Oel_Temp 0;
BA_ "GenSigSendType" SG_ 1600 MO_SpannungsAnf 0;
BA_ "GenSigSwitchedByIgnition" SG_ 1600 MO_SpannungsAnf 0;
BA_ "GenSigSendType" SG_ 1600 MO_Versionsinfo_02 0;
BA_ "GenSigSwitchedByIgnition" SG_ 1600 MO_Versionsinfo_02 0;
BA_ "GenSigSendType" SG_ 1607 MO_CO2_Faktor 0;
BA_ "GenSigSwitchedByIgnition" SG_ 1607 MO_CO2_Faktor 0;
BA_ "Fehlerwert" SG_ 1607 MO_CO2_Faktor 4095;
BA_ "GenSigSendType" SG_ 1607 MO_E85_Sensor 0;
BA_ "GenSigStartValue" SG_ 1607 MO_E85_Sensor 14;
BA_ "GenSigSwitchedByIgnition" SG_ 1607 MO_E85_Sensor 0;
BA_ "Fehlerwert" SG_ 1607 MO_E85_Sensor 15;
BA_ "GenSigSendType" SG_ 1607 MO_Ethanol_Spuelhinweis 0;
BA_ "GenSigSwitchedByIgnition" SG_ 1607 MO_Ethanol_Spuelhinweis 0;
BA_ "GenSigSendType" SG_ 1607 MO_ITM_Kuehlmittel_Temp 0;
BA_ "GenSigStartValue" SG_ 1607 MO_ITM_Kuehlmittel_Temp 1;
BA_ "GenSigSwitchedByIgnition" SG_ 1607 MO_ITM_Kuehlmittel_Temp 0;
BA_ "Fehlerwert" SG_ 1607 MO_ITM_Kuehlmittel_Temp 2;
BA_ "GenSigSendType" SG_ 1607 MO_Kraftstofffilter_Wasser 0;
BA_ "GenSigSwitchedByIgnition" SG_ 1607 MO_Kraftstofffilter_Wasser 0;
BA_ "GenSigSwitchedByIgnition" SG_ 1607 MO_MKB_01 0;
BA_ "GenSigSwitchedByIgnition" SG_ 1607 MO_MKB_02 0;
BA_ "GenSigSwitchedByIgnition" SG_ 1607 MO_MKB_03 0;
BA_ "GenSigSwitchedByIgnition" SG_ 1607 MO_MKB_04 0;
BA_ "GenSigSendType" SG_ 1607 MO_MKB_MUX 0;
BA_ "GenSigSwitchedByIgnition" SG_ 1607 MO_MKB_MUX 0;
BA_ "GenSigSendType" SG_ 1607 SCR_Akustik 0;
BA_ "GenSigSwitchedByIgnition" SG_ 1607 SCR_Akustik 0;
BA_ "GenSigSendType" SG_ 1607 SCR_Anz_Motorstarts 0;
BA_ "GenSigStartValue" SG_ 1607 SCR_Anz_Motorstarts 15;
BA_ "GenSigSwitchedByIgnition" SG_ 1607 SCR_Anz_Motorstarts 0;
BA_ "GenSigSendType" SG_ 1607 SCR_Inducement_Strategie 0;
BA_ "GenSigSwitchedByIgnition" SG_ 1607 SCR_Inducement_Strategie 0;
BA_ "GenSigSendType" SG_ 1607 SCR_Reichweite 0;
BA_ "GenSigStartValue" SG_ 1607 SCR_Reichweite 32767;
BA_ "GenSigSwitchedByIgnition" SG_ 1607 SCR_Reichweite 0;
BA_ "GenSigSendType" SG_ 1607 SCR_Systemfehler 0;
BA_ "GenSigSwitchedByIgnition" SG_ 1607 SCR_Systemfehler 0;
BA_ "GenSigSendType" SG_ 1607 SCR_Text 0;
BA_ "GenSigSwitchedByIgnition" SG_ 1607 SCR_Text 0;
BA_ "GenSigSendType" SG_ 1607 SCR_verbaut 0;
BA_ "GenSigFuncType" SG_ 1607 SCR_verbaut 8;
BA_ "GenSigSwitchedByIgnition" SG_ 1607 SCR_verbaut 0;
BA_ "GenSigSendType" SG_ 1607 SCR_Warnstufe_1 0;
BA_ "GenSigSwitchedByIgnition" SG_ 1607 SCR_Warnstufe_1 0;
BA_ "GenSigSendType" SG_ 1607 SCR_Warnstufe_2 0;
BA_ "GenSigSwitchedByIgnition" SG_ 1607 SCR_Warnstufe_2 0;
BA_ "GenSigSendType" SG_ 167 MO_erste_Ungenauschwelle 0;
BA_ "GenSigSwitchedByIgnition" SG_ 167 MO_erste_Ungenauschwelle 0;
BA_ "GenSigSendType" SG_ 167 MO_Mom_Ist_Summe 0;
BA_ "GenSigStartValue" SG_ 167 MO_Mom_Ist_Summe 1022;
BA_ "GenSigSwitchedByIgnition" SG_ 167 MO_Mom_Ist_Summe 0;
BA_ "GenSigSendType" SG_ 167 MO_Mom_Schub 0;
BA_ "GenSigStartValue" SG_ 167 MO_Mom_Schub 510;
BA_ "GenSigSwitchedByIgnition" SG_ 167 MO_Mom_Schub 0;
BA_ "GenSigSendType" SG_ 167 MO_Mom_Soll_gefiltert 0;
BA_ "GenSigStartValue" SG_ 167 MO_Mom_Soll_gefiltert 1022;
BA_ "GenSigSwitchedByIgnition" SG_ 167 MO_Mom_Soll_gefiltert 0;
BA_ "GenSigSendType" SG_ 167 MO_Mom_Soll_Roh 0;
BA_ "GenSigStartValue" SG_ 167 MO_Mom_Soll_Roh 1022;
BA_ "GenSigSwitchedByIgnition" SG_ 167 MO_Mom_Soll_Roh 0;
BA_ "GenSigSendType" SG_ 167 MO_Mom_Traegheit_Summe 0;
BA_ "GenSigStartValue" SG_ 167 MO_Mom_Traegheit_Summe 1022;
BA_ "GenSigSwitchedByIgnition" SG_ 167 MO_Mom_Traegheit_Summe 0;
BA_ "GenSigSendType" SG_ 167 MO_QBit_Motormomente 0;
BA_ "GenSigStartValue" SG_ 167 MO_QBit_Motormomente 1;
BA_ "GenSigSwitchedByIgnition" SG_ 167 MO_QBit_Motormomente 0;
BA_ "GenSigSendType" SG_ 167 MO_Status_Normalbetrieb_01 0;
BA_ "GenSigSwitchedByIgnition" SG_ 167 MO_Status_Normalbetrieb_01 0;
BA_ "GenSigSendType" SG_ 958 MO_Aussp_Anlass 3;
BA_ "GenSigSwitchedByIgnition" SG_ 958 MO_Aussp_Anlass 0;
BA_ "GenSigSendType" SG_ 958 MO_BKV_Unterdruckwarnung 0;
BA_ "GenSigSwitchedByIgnition" SG_ 958 MO_BKV_Unterdruckwarnung 0;
BA_ "GenSigSendType" SG_ 958 MO_BLS 3;
BA_ "GenSigSwitchedByIgnition" SG_ 958 MO_BLS 0;
BA_ "GenSigSendType" SG_ 958 MO_BMS_NV_Anf_stuetzen 3;
BA_ "GenSigSwitchedByIgnition" SG_ 958 MO_BMS_NV_Anf_stuetzen 0;
BA_ "GenSigSendType" SG_ 958 MO_EKlKomLeiRed 0;
BA_ "GenSigSwitchedByIgnition" SG_ 958 MO_EKlKomLeiRed 0;
BA_ "GenSigSendType" SG_ 958 MO_Ext_E_Fahrt_aktiv 3;
BA_ "NWM-WakeupAllowed" SG_ 958 MO_Ext_E_Fahrt_aktiv 1;
BA_ "GenSigSwitchedByIgnition" SG_ 958 MO_Ext_E_Fahrt_aktiv 0;
BA_ "GenSigSendType" SG_ 958 MO_Fahrer_bremst 3;
BA_ "GenSigSwitchedByIgnition" SG_ 958 MO_Fahrer_bremst 0;
BA_ "GenSigSendType" SG_ 958 MO_FMAus_aktiv 3;
BA_ "GenSigSwitchedByIgnition" SG_ 958 MO_FMAus_aktiv 0;
BA_ "GenSigSendType" SG_ 958 MO_FMAus_Startvariante 3;
BA_ "GenSigSwitchedByIgnition" SG_ 958 MO_FMAus_Startvariante 0;
BA_ "GenSigSendType" SG_ 958 MO_Freig_Anlass 3;
BA_ "GenSigSwitchedByIgnition" SG_ 958 MO_Freig_Anlass 0;
BA_ "GenSigSendType" SG_ 958 MO_Freig_Reku 0;
BA_ "GenSigSwitchedByIgnition" SG_ 958 MO_Freig_Reku 0;
BA_ "GenSigSendType" SG_ 958 MO_Freigabe_Segeln 0;
BA_ "GenSigSwitchedByIgnition" SG_ 958 MO_Freigabe_Segeln 0;
BA_ "GenSigSendType" SG_ 958 MO_Gangposition 3;
BA_ "GenSigStartValue" SG_ 958 MO_Gangposition 14;
BA_ "GenSigSwitchedByIgnition" SG_ 958 MO_Gangposition 0;
BA_ "Fehlerwert" SG_ 958 MO_Gangposition 15;
BA_ "GenSigSendType" SG_ 958 MO_Handshake_STH 0;
BA_ "GenSigSwitchedByIgnition" SG_ 958 MO_Handshake_STH 0;
BA_ "GenSigSendType" SG_ 958 MO_HYB_Fahrbereitschaft 0;
BA_ "GenSigSwitchedByIgnition" SG_ 958 MO_HYB_Fahrbereitschaft 0;
BA_ "GenSigSendType" SG_ 958 MO_HYB_VM_aktiv 3;
BA_ "GenSigSwitchedByIgnition" SG_ 958 MO_HYB_VM_aktiv 0;
BA_ "GenSigSendType" SG_ 958 MO_Interlock 3;
BA_ "GenSigSwitchedByIgnition" SG_ 958 MO_Interlock 0;
BA_ "GenSigSendType" SG_ 958 MO_Kickdown 3;
BA_ "GenSigSwitchedByIgnition" SG_ 958 MO_Kickdown 0;
BA_ "GenSigSendType" SG_ 958 MO_Kl_50 3;
BA_ "GenSigSwitchedByIgnition" SG_ 958 MO_Kl_50 0;
BA_ "GenSigSendType" SG_ 958 MO_Kl_75 3;
BA_ "GenSigSwitchedByIgnition" SG_ 958 MO_Kl_75 0;
BA_ "GenSigSendType" SG_ 958 MO_Klima_Eingr 3;
BA_ "GenSigSwitchedByIgnition" SG_ 958 MO_Klima_Eingr 0;
BA_ "GenSigSendType" SG_ 958 MO_Konsistenz_Bremsped 3;
BA_ "GenSigSwitchedByIgnition" SG_ 958 MO_Konsistenz_Bremsped 0;
BA_ "GenSigSendType" SG_ 958 MO_Kuppl_schalter 3;
BA_ "GenSigSwitchedByIgnition" SG_ 958 MO_Kuppl_schalter 0;
BA_ "GenSigSendType" SG_ 958 MO_Motor_laeuft 3;
BA_ "GenSigSwitchedByIgnition" SG_ 958 MO_Motor_laeuft 0;
BA_ "GenSigSendType" SG_ 958 MO_PTC_Status 0;
BA_ "GenSigSwitchedByIgnition" SG_ 958 MO_PTC_Status 0;
BA_ "GenSigSendType" SG_ 958 MO_QBit_Fahrer_bremst 3;
BA_ "GenSigStartValue" SG_ 958 MO_QBit_Fahrer_bremst 1;
BA_ "GenSigSwitchedByIgnition" SG_ 958 MO_QBit_Fahrer_bremst 0;
BA_ "GenSigSendType" SG_ 958 MO_QBit_Gangposition 3;
BA_ "GenSigStartValue" SG_ 958 MO_QBit_Gangposition 1;
BA_ "GenSigSwitchedByIgnition" SG_ 958 MO_QBit_Gangposition 0;
BA_ "GenSigSendType" SG_ 958 MO_QBit_KL_75 3;
BA_ "GenSigStartValue" SG_ 958 MO_QBit_KL_75 1;
BA_ "GenSigSwitchedByIgnition" SG_ 958 MO_QBit_KL_75 0;
BA_ "GenSigSendType" SG_ 958 MO_Remotestart_Betrieb 3;
BA_ "GenSigSwitchedByIgnition" SG_ 958 MO_Remotestart_Betrieb 0;
BA_ "GenSigSendType" SG_ 958 MO_Remotestart_moeglich 0;
BA_ "GenSigSwitchedByIgnition" SG_ 958 MO_Remotestart_moeglich 0;
BA_ "GenSigSendType" SG_ 958 MO_Signalquelle_Gangposition 0;
BA_ "GenSigSwitchedByIgnition" SG_ 958 MO_Signalquelle_Gangposition 0;
BA_ "GenSigSendType" SG_ 958 MO_StartStopp_Fahrerwunsch 0;
BA_ "GenSigSwitchedByIgnition" SG_ 958 MO_StartStopp_Fahrerwunsch 0;
BA_ "GenSigSendType" SG_ 958 MO_StartStopp_Motorstopp 3;
BA_ "GenSigSwitchedByIgnition" SG_ 958 MO_StartStopp_Motorstopp 0;
BA_ "GenSigSendType" SG_ 958 MO_StartStopp_Status 0;
BA_ "GenSigSwitchedByIgnition" SG_ 958 MO_StartStopp_Status 0;
BA_ "GenSigSendType" SG_ 958 MO_StartStopp_Wiederstart 3;
BA_ "GenSigSwitchedByIgnition" SG_ 958 MO_StartStopp_Wiederstart 0;
BA_ "GenSigSendType" SG_ 958 MO_StartVorauss_erfuellt 3;
BA_ "GenSigStartValue" SG_ 958 MO_StartVorauss_erfuellt 1;
BA_ "GenSigSwitchedByIgnition" SG_ 958 MO_StartVorauss_erfuellt 0;
BA_ "GenSigSendType" SG_ 958 MO_Timeout_ESP 3;
BA_ "GenSigSwitchedByIgnition" SG_ 958 MO_Timeout_ESP 0;
BA_ "GenSigSendType" SG_ 958 MO_Zylinderabschaltung 3;
BA_ "GenSigSwitchedByIgnition" SG_ 958 MO_Zylinderabschaltung 0;
BA_ "GenSigSendType" SG_ 958 Motor_14_BZ 0;
BA_ "GenSigFuncType" SG_ 958 Motor_14_BZ 1;
BA_ "GenSigSwitchedByIgnition" SG_ 958 Motor_14_BZ 0;
BA_ "GenSigSendType" SG_ 958 Motor_14_CRC 0;
BA_ "GenSigFuncType" SG_ 958 Motor_14_CRC 2;
BA_ "GenSigSwitchedByIgnition" SG_ 958 Motor_14_CRC 0;
BA_ "GenSigSendType" SG_ 1631 MO_Anzeige_Kaltleuchte 0;
BA_ "GenSigSwitchedByIgnition" SG_ 1631 MO_Anzeige_Kaltleuchte 0;
BA_ "GenSigSendType" SG_ 1631 MO_DPF_reg 0;
BA_ "GenSigSwitchedByIgnition" SG_ 1631 MO_DPF_reg 0;
BA_ "GenSigSendType" SG_ 1631 MO_Energieinhalt_BMS 0;
BA_ "GenSigStartValue" SG_ 1631 MO_Energieinhalt_BMS 4094;
BA_ "GenSigSwitchedByIgnition" SG_ 1631 MO_Energieinhalt_BMS 0;
BA_ "Fehlerwert" SG_ 1631 MO_Energieinhalt_BMS 4095;
BA_ "GenSigSendType" SG_ 1631 MO_Heizstrom_EKAT 0;
BA_ "GenSigSwitchedByIgnition" SG_ 1631 MO_Heizstrom_EKAT 0;
BA_ "Fehlerwert" SG_ 1631 MO_Heizstrom_EKAT 127;
BA_ "GenSigSendType" SG_ 1631 MO_Heizstrom_SCR 0;
BA_ "GenSigSwitchedByIgnition" SG_ 1631 MO_Heizstrom_SCR 0;
BA_ "Fehlerwert" SG_ 1631 MO_Heizstrom_SCR 63;
BA_ "GenSigSendType" SG_ 1631 MO_P_Generator_ungefiltert_Anf 0;
BA_ "GenSigSwitchedByIgnition" SG_ 1631 MO_P_Generator_ungefiltert_Anf 0;
BA_ "GenSigSendType" SG_ 1631 MO_SpannungsAnf_02 0;
BA_ "GenSigSwitchedByIgnition" SG_ 1631 MO_SpannungsAnf_02 0;
BA_ "GenSigSendType" SG_ 1631 TSK_Fahrzeugmasse_02 0;
BA_ "GenSigSwitchedByIgnition" SG_ 1631 TSK_Fahrzeugmasse_02 0;
BA_ "Fehlerwert" SG_ 1631 TSK_Fahrzeugmasse_02 255;
BA_ "GenSigSendType" SG_ 1631 TSK_Grundmasse 0;
BA_ "GenSigSwitchedByIgnition" SG_ 1631 TSK_Grundmasse 0;
BA_ "GenSigSendType" SG_ 1631 TSK_QBit_Fahrzeugmasse 0;
BA_ "GenSigStartValue" SG_ 1631 TSK_QBit_Fahrzeugmasse 1;
BA_ "GenSigSwitchedByIgnition" SG_ 1631 TSK_QBit_Fahrzeugmasse 0;
BA_ "GenSigSendType" SG_ 1631 TSK_QBit_Steigung 0;
BA_ "GenSigStartValue" SG_ 1631 TSK_QBit_Steigung 1;
BA_ "GenSigSwitchedByIgnition" SG_ 1631 TSK_QBit_Steigung 0;
BA_ "GenSigSendType" SG_ 1631 TSK_Steigung_02 0;
BA_ "GenSigSwitchedByIgnition" SG_ 1631 TSK_Steigung_02 0;
BA_ "Fehlerwert" SG_ 1631 TSK_Steigung_02 255;
BA_ "GenSigSendType" SG_ 1648 MO1_Freigabe_Info_WFS 3;
BA_ "GenSigSwitchedByIgnition" SG_ 1648 MO1_Freigabe_Info_WFS 0;
BA_ "GenSigSendType" SG_ 1648 MO1_Freigabe_Verfallsinfo_WFS 3;
BA_ "GenSigSwitchedByIgnition" SG_ 1648 MO1_Freigabe_Verfallsinfo_WFS 0;
BA_ "GenSigSendType" SG_ 1648 MO1_Sperr_Info_WFS 3;
BA_ "GenSigSwitchedByIgnition" SG_ 1648 MO1_Sperr_Info_WFS 0;
BA_ "GenSigSendType" SG_ 1648 MO_Abstellzeit 0;
BA_ "GenSigStartValue" SG_ 1648 MO_Abstellzeit 254;
BA_ "GenSigSwitchedByIgnition" SG_ 1648 MO_Abstellzeit 0;
BA_ "GenSigSendType" SG_ 1648 MO_Abstellzeit_Status 0;
BA_ "GenSigSwitchedByIgnition" SG_ 1648 MO_Abstellzeit_Status 0;
BA_ "GenSigSendType" SG_ 1648 MO_ANC_Kennfeld_Anf 3;
BA_ "GenSigSwitchedByIgnition" SG_ 1648 MO_ANC_Kennfeld_Anf 0;
BA_ "GenSigSendType" SG_ 1648 MO_Anzahl_Abgesch_Zyl 3;
BA_ "GenSigSwitchedByIgnition" SG_ 1648 MO_Anzahl_Abgesch_Zyl 0;
BA_ "GenSigSendType" SG_ 1648 MO_Bremslicht_Reku 3;
BA_ "GenSigSwitchedByIgnition" SG_ 1648 MO_Bremslicht_Reku 0;
BA_ "GenSigSendType" SG_ 1648 MO_Drehzahl_Warnung 0;
BA_ "GenSigSwitchedByIgnition" SG_ 1648 MO_Drehzahl_Warnung 0;
BA_ "GenSigSendType" SG_ 1648 MO_EPCL 3;
BA_ "GenSigSwitchedByIgnition" SG_ 1648 MO_EPCL 0;
BA_ "GenSigSendType" SG_ 1648 MO_Ethanol_BS_Texte 0;
BA_ "GenSigSwitchedByIgnition" SG_ 1648 MO_Ethanol_BS_Texte 0;
BA_ "GenSigSendType" SG_ 1648 MO_Fahrzeugtyp 0;
BA_ "GenSigFuncType" SG_ 1648 MO_Fahrzeugtyp 8;
BA_ "GenSigSwitchedByIgnition" SG_ 1648 MO_Fahrzeugtyp 0;
BA_ "GenSigSendType" SG_ 1648 MO_Fehler_Zylabsch 0;
BA_ "GenSigSwitchedByIgnition" SG_ 1648 MO_Fehler_Zylabsch 0;
BA_ "GenSigSendType" SG_ 1648 MO_Hybrid_StartStopp_LED 3;
BA_ "GenSigSwitchedByIgnition" SG_ 1648 MO_Hybrid_StartStopp_LED 0;
BA_ "GenSigSendType" SG_ 1648 MO_max_Ladedruck 0;
BA_ "GenSigFuncType" SG_ 1648 MO_max_Ladedruck 8;
BA_ "GenSigSwitchedByIgnition" SG_ 1648 MO_max_Ladedruck 0;
BA_ "GenSigSendType" SG_ 1648 MO_NMAX_Schaltanzeige 3;
BA_ "GenSigSwitchedByIgnition" SG_ 1648 MO_NMAX_Schaltanzeige 0;
BA_ "GenSigSendType" SG_ 1648 MO_obere_Drehzahlgrenze 0;
BA_ "GenSigSwitchedByIgnition" SG_ 1648 MO_obere_Drehzahlgrenze 0;
BA_ "GenSigSendType" SG_ 1648 MO_StartStopp_PopUp 3;
BA_ "GenSigSwitchedByIgnition" SG_ 1648 MO_StartStopp_PopUp 0;
BA_ "GenSigSendType" SG_ 1648 MO_Zylabsch_Texte 0;
BA_ "GenSigSwitchedByIgnition" SG_ 1648 MO_Zylabsch_Texte 0;
BA_ "GenSigSendType" SG_ 1648 MO_Zylabsch_Texte_02 3;
BA_ "GenSigSwitchedByIgnition" SG_ 1648 MO_Zylabsch_Texte_02 0;
BA_ "GenSigSendType" SG_ 289 MO_Entkopplung_Sollschlupf 0;
BA_ "GenSigStartValue" SG_ 289 MO_Entkopplung_Sollschlupf 126;
BA_ "GenSigSwitchedByIgnition" SG_ 289 MO_Entkopplung_Sollschlupf 0;
BA_ "GenSigSendType" SG_ 289 MO_Fahrpedalgradient 0;
BA_ "GenSigSwitchedByIgnition" SG_ 289 MO_Fahrpedalgradient 0;
BA_ "Fehlerwert" SG_ 289 MO_Fahrpedalgradient 255;
BA_ "GenSigSendType" SG_ 289 MO_Fahrpedalrohwert_01 0;
BA_ "GenSigSwitchedByIgnition" SG_ 289 MO_Fahrpedalrohwert_01 0;
BA_ "Fehlerwert" SG_ 289 MO_Fahrpedalrohwert_01 255;
BA_ "GenSigSendType" SG_ 289 MO_Moment_im_Leerlauf 0;
BA_ "GenSigSwitchedByIgnition" SG_ 289 MO_Moment_im_Leerlauf 0;
BA_ "GenSigSendType" SG_ 289 MO_QBit_Fahrpedalwerte_01 0;
BA_ "GenSigStartValue" SG_ 289 MO_QBit_Fahrpedalwerte_01 1;
BA_ "GenSigSwitchedByIgnition" SG_ 289 MO_QBit_Fahrpedalwerte_01 0;
BA_ "GenSigSendType" SG_ 289 MO_rel_Saugrohrdruck 0;
BA_ "GenSigSwitchedByIgnition" SG_ 289 MO_rel_Saugrohrdruck 0;
BA_ "Fehlerwert" SG_ 289 MO_rel_Saugrohrdruck 63;
BA_ "GenSigSendType" SG_ 289 MO_rel_Saugrohrdruck_gem_err 0;
BA_ "GenSigSwitchedByIgnition" SG_ 289 MO_rel_Saugrohrdruck_gem_err 0;
BA_ "GenSigSendType" SG_ 289 MO_Schubabschaltung 0;
BA_ "GenSigSwitchedByIgnition" SG_ 289 MO_Schubabschaltung 0;
BA_ "GenSigSendType" SG_ 289 MO_Sig_Fahrpedalgradient 0;
BA_ "GenSigSwitchedByIgnition" SG_ 289 MO_Sig_Fahrpedalgradient 0;
BA_ "GenSigSendType" SG_ 289 MO_Solldrehz_Leerlauf 0;
BA_ "GenSigSwitchedByIgnition" SG_ 289 MO_Solldrehz_Leerlauf 0;
BA_ "GenSigSendType" SG_ 289 MO_StartStopp_StoppVorbereitung 0;
BA_ "GenSigSwitchedByIgnition" SG_ 289 MO_StartStopp_StoppVorbereitung 0;
BA_ "GenSigSendType" SG_ 289 MO_temporaere_Fahrerabwesenheit 0;
BA_ "GenSigSwitchedByIgnition" SG_ 289 MO_temporaere_Fahrerabwesenheit 0;
BA_ "GenSigSendType" SG_ 289 TSK_a_Soll_gradientenbegrenzt 0;
BA_ "GenSigStartValue" SG_ 289 TSK_a_Soll_gradientenbegrenzt 127;
BA_ "GenSigSwitchedByIgnition" SG_ 289 TSK_a_Soll_gradientenbegrenzt 0;
BA_ "GenSigSendType" SG_ 1391 MO_Anzeige_Aufheizfortschritt 0;
BA_ "GenSigStartValue" SG_ 1391 MO_Anzeige_Aufheizfortschritt 126;
BA_ "GenSigSwitchedByIgnition" SG_ 1391 MO_Anzeige_Aufheizfortschritt 0;
BA_ "Fehlerwert" SG_ 1391 MO_Anzeige_Aufheizfortschritt 127;
BA_ "GenSigSendType" SG_ 1391 MO_Anzeige_Drehmoment_Max 0;
BA_ "GenSigSwitchedByIgnition" SG_ 1391 MO_Anzeige_Drehmoment_Max 0;
BA_ "GenSigSendType" SG_ 1391 MO_Anzeige_Leistung_Max 0;
BA_ "GenSigSwitchedByIgnition" SG_ 1391 MO_Anzeige_Leistung_Max 0;
BA_ "GenSigSendType" SG_ 1391 MO_HYB_Drehzahl_VM 0;
BA_ "GenSigSwitchedByIgnition" SG_ 1391 MO_HYB_Drehzahl_VM 0;
BA_ "Fehlerwert" SG_ 1391 MO_HYB_Drehzahl_VM 65280;
BA_ "GenSigSendType" SG_ 1391 MO_IstLeistung_EKAT 0;
BA_ "GenSigStartValue" SG_ 1391 MO_IstLeistung_EKAT 126;
BA_ "GenSigSwitchedByIgnition" SG_ 1391 MO_IstLeistung_EKAT 0;
BA_ "Fehlerwert" SG_ 1391 MO_IstLeistung_EKAT 127;
BA_ "GenSigSendType" SG_ 967 MO_E_Mode 0;
BA_ "GenSigSwitchedByIgnition" SG_ 967 MO_E_Mode 0;
BA_ "GenSigSendType" SG_ 967 MO_E_Texte 0;
BA_ "GenSigSwitchedByIgnition" SG_ 967 MO_E_Texte 0;
BA_ "GenSigSendType" SG_ 967 MO_E_Warnungen 0;
BA_ "GenSigSwitchedByIgnition" SG_ 967 MO_E_Warnungen 0;
BA_ "GenSigSendType" SG_ 967 MO_EFLEX_Lampe 0;
BA_ "GenSigSwitchedByIgnition" SG_ 967 MO_EFLEX_Lampe 0;
BA_ "GenSigSendType" SG_ 967 MO_Heissleuchte 0;
BA_ "GenSigSwitchedByIgnition" SG_ 967 MO_Heissleuchte 0;
BA_ "GenSigSendType" SG_ 967 MO_ITM_Warnung_Pumpe 0;
BA_ "GenSigSwitchedByIgnition" SG_ 967 MO_ITM_Warnung_Pumpe 0;
BA_ "GenSigSendType" SG_ 967 MO_KJS_nicht_bereit 0;
BA_ "GenSigSwitchedByIgnition" SG_ 967 MO_KJS_nicht_bereit 0;
BA_ "Fehlerwert" SG_ 967 MO_KJS_nicht_bereit 1;
BA_ "GenSigStartValue" SG_ 967 MO_Kuehlerluefter_1 126;
BA_ "GenSigSwitchedByIgnition" SG_ 967 MO_Kuehlerluefter_1 0;
BA_ "Fehlerwert" SG_ 967 MO_Kuehlerluefter_1 127;
BA_ "GenSigStartValue" SG_ 967 MO_Kuehlerluefter_2 126;
BA_ "GenSigSwitchedByIgnition" SG_ 967 MO_Kuehlerluefter_2 0;
BA_ "Fehlerwert" SG_ 967 MO_Kuehlerluefter_2 127;
BA_ "GenSigSendType" SG_ 967 MO_Kuehlerluefter_MUX 0;
BA_ "GenSigSwitchedByIgnition" SG_ 967 MO_Kuehlerluefter_MUX 0;
BA_ "GenSigSendType" SG_ 967 MO_OBD2_Lampe 0;
BA_ "GenSigSwitchedByIgnition" SG_ 967 MO_OBD2_Lampe 0;
BA_ "GenSigSendType" SG_ 967 MO_Oelwarnung_max 0;
BA_ "GenSigSwitchedByIgnition" SG_ 967 MO_Oelwarnung_max 0;
BA_ "GenSigSendType" SG_ 967 MO_Partikel_Lampe 0;
BA_ "GenSigSwitchedByIgnition" SG_ 967 MO_Partikel_Lampe 0;
BA_ "GenSigSendType" SG_ 967 MO_RedFahrleistung_Lampe 0;
BA_ "GenSigSwitchedByIgnition" SG_ 967 MO_RedFahrleistung_Lampe 0;
BA_ "GenSigSendType" SG_ 967 MO_Systemlampe 0;
BA_ "GenSigSwitchedByIgnition" SG_ 967 MO_Systemlampe 0;
BA_ "GenSigSendType" SG_ 967 MO_Tankdeckel_Lampe 0;
BA_ "GenSigSwitchedByIgnition" SG_ 967 MO_Tankdeckel_Lampe 0;
BA_ "GenSigSendType" SG_ 967 MO_Text_Motorstart 0;
BA_ "GenSigSwitchedByIgnition" SG_ 967 MO_Text_Motorstart 0;
BA_ "GenSigSendType" SG_ 967 MO_Text_Partikelfil_Reg 0;
BA_ "GenSigSwitchedByIgnition" SG_ 967 MO_Text_Partikelfil_Reg 0;
BA_ "GenSigSendType" SG_ 967 MO_Text_Tankdeckelwarn 0;
BA_ "GenSigSwitchedByIgnition" SG_ 967 MO_Text_Tankdeckelwarn 0;
BA_ "GenSigSendType" SG_ 967 MO_Vorglueh_Lampe 0;
BA_ "GenSigSwitchedByIgnition" SG_ 967 MO_Vorglueh_Lampe 0;
BA_ "GenSigSendType" SG_ 967 MO_Zustand_HWP 0;
BA_ "GenSigStartValue" SG_ 967 MO_Zustand_HWP 1;
BA_ "GenSigSwitchedByIgnition" SG_ 967 MO_Zustand_HWP 0;
BA_ "GenSigSendType" SG_ 967 OLEV_Oelstand_nicht_vorhanden 0;
BA_ "GenSigSwitchedByIgnition" SG_ 967 OLEV_Oelstand_nicht_vorhanden 0;
BA_ "GenSigSendType" SG_ 967 OLEV_Systemstoerung 0;
BA_ "GenSigSwitchedByIgnition" SG_ 967 OLEV_Systemstoerung 0;
BA_ "GenSigSendType" SG_ 967 WIV_Anzeige_aktiv 0;
BA_ "GenSigSwitchedByIgnition" SG_ 967 WIV_Anzeige_aktiv 0;
BA_ "GenSigSendType" SG_ 967 WIV_laufender_Motor 0;
BA_ "GenSigSwitchedByIgnition" SG_ 967 WIV_laufender_Motor 0;
BA_ "GenSigSendType" SG_ 967 WIV_nachfuellanzeige_ein 0;
BA_ "GenSigSwitchedByIgnition" SG_ 967 WIV_nachfuellanzeige_ein 0;
BA_ "GenSigSendType" SG_ 967 WIV_nicht_betriebswarm 0;
BA_ "GenSigSwitchedByIgnition" SG_ 967 WIV_nicht_betriebswarm 0;
BA_ "GenSigSendType" SG_ 967 WIV_Oeldr_Warn_Motor 0;
BA_ "GenSigSwitchedByIgnition" SG_ 967 WIV_Oeldr_Warn_Motor 0;
BA_ "GenSigSendType" SG_ 967 WIV_Oeldyn_avl 0;
BA_ "GenSigSwitchedByIgnition" SG_ 967 WIV_Oeldyn_avl 0;
BA_ "GenSigSendType" SG_ 967 WIV_Oelmenge 0;
BA_ "GenSigSwitchedByIgnition" SG_ 967 WIV_Oelmenge 0;
BA_ "GenSigSendType" SG_ 967 WIV_Oelmin_Warn 0;
BA_ "GenSigSwitchedByIgnition" SG_ 967 WIV_Oelmin_Warn 0;
BA_ "GenSigSendType" SG_ 967 WIV_Oelstand 0;
BA_ "GenSigSwitchedByIgnition" SG_ 967 WIV_Oelstand 0;
BA_ "GenSigSendType" SG_ 967 WIV_Oelstand_nicht_vorhanden 0;
BA_ "GenSigSwitchedByIgnition" SG_ 967 WIV_Oelstand_nicht_vorhanden 0;
BA_ "GenSigSendType" SG_ 967 WIV_Oelsystem_aktiv 0;
BA_ "GenSigSwitchedByIgnition" SG_ 967 WIV_Oelsystem_aktiv 0;
BA_ "GenSigSendType" SG_ 967 WIV_Schieflage 0;
BA_ "GenSigSwitchedByIgnition" SG_ 967 WIV_Schieflage 0;
BA_ "GenSigSendType" SG_ 967 WIV_Sensorfehler 0;
BA_ "GenSigSwitchedByIgnition" SG_ 967 WIV_Sensorfehler 0;
BA_ "GenSigSendType" SG_ 967 WIV_Ueberfuell_deaktiv 0;
BA_ "GenSigSwitchedByIgnition" SG_ 967 WIV_Ueberfuell_deaktiv 0;
BA_ "GenSigSendType" SG_ 967 WIV_Ueberfuell_Warn 0;
BA_ "GenSigSwitchedByIgnition" SG_ 967 WIV_Ueberfuell_Warn 0;
BA_ "GenSigSendType" SG_ 967 WIV_Unterfuell_Warn 0;
BA_ "GenSigSwitchedByIgnition" SG_ 967 WIV_Unterfuell_Warn 0;
BA_ "GenSigSendType" SG_ 327 MO_Anzeige_Drehmoment 0;
BA_ "GenSigSwitchedByIgnition" SG_ 327 MO_Anzeige_Drehmoment 0;
BA_ "Fehlerwert" SG_ 327 MO_Anzeige_Drehmoment 2047;
BA_ "GenSigSendType" SG_ 327 MO_Anzeige_Leistung 0;
BA_ "GenSigSwitchedByIgnition" SG_ 327 MO_Anzeige_Leistung 0;
BA_ "Fehlerwert" SG_ 327 MO_Anzeige_Leistung 2047;
BA_ "GenSigSendType" SG_ 327 MO_Anzeige_Verbr_Einheit 0;
BA_ "GenSigSwitchedByIgnition" SG_ 327 MO_Anzeige_Verbr_Einheit 0;
BA_ "GenSigSendType" SG_ 327 MO_Hochschaltdrehz 0;
BA_ "GenSigSwitchedByIgnition" SG_ 327 MO_Hochschaltdrehz 0;
BA_ "Fehlerwert" SG_ 327 MO_Hochschaltdrehz 4095;
BA_ "GenSigSendType" SG_ 327 MO_Schaltblitz_Anz 0;
BA_ "GenSigStartValue" SG_ 327 MO_Schaltblitz_Anz 126;
BA_ "GenSigSwitchedByIgnition" SG_ 327 MO_Schaltblitz_Anz 0;
BA_ "Fehlerwert" SG_ 327 MO_Schaltblitz_Anz 127;
BA_ "GenSigSendType" SG_ 1601 MO_Ansaugsystem 0;
BA_ "GenSigFuncType" SG_ 1601 MO_Ansaugsystem 8;
BA_ "GenSigSwitchedByIgnition" SG_ 1601 MO_Ansaugsystem 0;
BA_ "GenSigSendType" SG_ 1601 MO_Anzahl_Zyl 0;
BA_ "GenSigFuncType" SG_ 1601 MO_Anzahl_Zyl 8;
BA_ "GenSigSwitchedByIgnition" SG_ 1601 MO_Anzahl_Zyl 0;
BA_ "GenSigSendType" SG_ 1601 MO_Anzeige_StSt_gueltig 0;
BA_ "GenSigSwitchedByIgnition" SG_ 1601 MO_Anzeige_StSt_gueltig 0;
BA_ "GenSigSendType" SG_ 1601 MO_Code 0;
BA_ "GenSigSwitchedByIgnition" SG_ 1601 MO_Code 0;
BA_ "GenSigSendType" SG_ 1601 MO_DPF_verbaut 0;
BA_ "GenSigFuncType" SG_ 1601 MO_DPF_verbaut 8;
BA_ "GenSigSwitchedByIgnition" SG_ 1601 MO_DPF_verbaut 0;
BA_ "GenSigSendType" SG_ 1601 MO_Faktor_Momente_02 0;
BA_ "GenSigFuncType" SG_ 1601 MO_Faktor_Momente_02 8;
BA_ "GenSigSwitchedByIgnition" SG_ 1601 MO_Faktor_Momente_02 0;
BA_ "GenSigSendType" SG_ 1601 MO_Getriebe_Code 0;
BA_ "GenSigSwitchedByIgnition" SG_ 1601 MO_Getriebe_Code 0;
BA_ "GenSigSendType" SG_ 1601 MO_Hubraum 0;
BA_ "GenSigFuncType" SG_ 1601 MO_Hubraum 8;
BA_ "GenSigSwitchedByIgnition" SG_ 1601 MO_Hubraum 0;
BA_ "GenSigSendType" SG_ 1601 MO_Hybridfahrzeug 0;
BA_ "GenSigFuncType" SG_ 1601 MO_Hybridfahrzeug 8;
BA_ "GenSigSwitchedByIgnition" SG_ 1601 MO_Hybridfahrzeug 0;
BA_ "GenSigSendType" SG_ 1601 MO_Kraftstoffart 0;
BA_ "GenSigFuncType" SG_ 1601 MO_Kraftstoffart 8;
BA_ "GenSigSwitchedByIgnition" SG_ 1601 MO_Kraftstoffart 0;
BA_ "GenSigSendType" SG_ 1601 MO_Leistung 0;
BA_ "GenSigSwitchedByIgnition" SG_ 1601 MO_Leistung 0;
BA_ "GenSigSendType" SG_ 1601 MO_OBD_Typ 0;
BA_ "GenSigSwitchedByIgnition" SG_ 1601 MO_OBD_Typ 0;
BA_ "GenSigSendType" SG_ 1601 MO_StartStopp_Codiert 0;
BA_ "GenSigFuncType" SG_ 1601 MO_StartStopp_Codiert 8;
BA_ "GenSigSwitchedByIgnition" SG_ 1601 MO_StartStopp_Codiert 0;
BA_ "GenSigSendType" SG_ 1601 Motor_Code_01_BZ 0;
BA_ "GenSigFuncType" SG_ 1601 Motor_Code_01_BZ 1;
BA_ "GenSigSwitchedByIgnition" SG_ 1601 Motor_Code_01_BZ 0;
BA_ "GenSigSendType" SG_ 1601 Motor_Code_01_CRC 0;
BA_ "GenSigFuncType" SG_ 1601 Motor_Code_01_CRC 2;
BA_ "GenSigSwitchedByIgnition" SG_ 1601 Motor_Code_01_CRC 0;
BA_ "GenSigSendType" SG_ 1601 TSK_Codierung 0;
BA_ "GenSigStartValue" SG_ 1601 TSK_Codierung 7;
BA_ "GenSigSwitchedByIgnition" SG_ 1601 TSK_Codierung 0;
BA_ "GenSigSendType" SG_ 391 EV_Rekuperationsstufe 0;
BA_ "GenSigSwitchedByIgnition" SG_ 391 EV_Rekuperationsstufe 0;
BA_ "GenSigSendType" SG_ 391 MO_Drehzahl_VM 0;
BA_ "GenSigSwitchedByIgnition" SG_ 391 MO_Drehzahl_VM 0;
BA_ "GenSigSendType" SG_ 391 MO_Fehler_Notabschaltung_Klima 3;
BA_ "GenSigSwitchedByIgnition" SG_ 391 MO_Fehler_Notabschaltung_Klima 0;
BA_ "GenSigSendType" SG_ 391 MO_Fehler_NTKreis 0;
BA_ "GenSigSwitchedByIgnition" SG_ 391 MO_Fehler_NTKreis 0;
BA_ "Fehlerwert" SG_ 391 MO_Fehler_NTKreis 1;
BA_ "GenSigSendType" SG_ 391 MO_KLE_FStatus 0;
BA_ "GenSigSwitchedByIgnition" SG_ 391 MO_KLE_FStatus 0;
BA_ "Fehlerwert" SG_ 391 MO_KLE_FStatus 3;
BA_ "GenSigSendType" SG_ 391 MO_Tankbereitschaft_Status 0;
BA_ "GenSigSwitchedByIgnition" SG_ 391 MO_Tankbereitschaft_Status 0;
BA_ "GenSigSendType" SG_ 391 MO_Tankklappensteuerung 0;
BA_ "GenSigSwitchedByIgnition" SG_ 391 MO_Tankklappensteuerung 0;
BA_ "GenSigSendType" SG_ 391 MO_Waehlpos 3;
BA_ "GenSigSwitchedByIgnition" SG_ 391 MO_Waehlpos 0;
BA_ "Fehlerwert" SG_ 391 MO_Waehlpos 7;
BA_ "GenSigSendType" SG_ 391 MO_WH_Texte 3;
BA_ "GenSigSwitchedByIgnition" SG_ 391 MO_WH_Texte 0;
BA_ "GenSigSendType" SG_ 391 Motor_EV_01_BZ 0;
BA_ "GenSigFuncType" SG_ 391 Motor_EV_01_BZ 1;
BA_ "GenSigSwitchedByIgnition" SG_ 391 Motor_EV_01_BZ 0;
BA_ "GenSigSendType" SG_ 391 Motor_EV_01_CRC 0;
BA_ "GenSigFuncType" SG_ 391 Motor_EV_01_CRC 2;
BA_ "GenSigSwitchedByIgnition" SG_ 391 Motor_EV_01_CRC 0;
BA_ "GenSigSendType" SG_ 813 MO_akt_Betrieb 0;
BA_ "GenSigSwitchedByIgnition" SG_ 813 MO_akt_Betrieb 0;
BA_ "GenSigSendType" SG_ 813 MO_AnzeigeGasbetrieb 0;
BA_ "GenSigSwitchedByIgnition" SG_ 813 MO_AnzeigeGasbetrieb 0;
BA_ "GenSigSendType" SG_ 813 MO_CNG_LPG 0;
BA_ "GenSigSwitchedByIgnition" SG_ 813 MO_CNG_LPG 0;
BA_ "GenSigSwitchedByIgnition" SG_ 813 MO_CNG_Tankstopp 0;
BA_ "GenSigSwitchedByIgnition" SG_ 813 MO_CNG_Ueberlauf 0;
BA_ "GenSigSendType" SG_ 813 MO_Erdgasqualitaet 0;
BA_ "GenSigSwitchedByIgnition" SG_ 813 MO_Erdgasqualitaet 0;
BA_ "GenSigSwitchedByIgnition" SG_ 813 MO_Fuellstand_LPG 0;
BA_ "Fehlerwert" SG_ 813 MO_Fuellstand_LPG 1023;
BA_ "GenSigStartValue" SG_ 813 MO_Fuellungsgrad_CNG 254;
BA_ "GenSigSwitchedByIgnition" SG_ 813 MO_Fuellungsgrad_CNG 0;
BA_ "Fehlerwert" SG_ 813 MO_Fuellungsgrad_CNG 255;
BA_ "GenSigStartValue" SG_ 813 MO_Fuellungsgrad_LPG 254;
BA_ "GenSigSwitchedByIgnition" SG_ 813 MO_Fuellungsgrad_LPG 0;
BA_ "Fehlerwert" SG_ 813 MO_Fuellungsgrad_LPG 255;
BA_ "GenSigSwitchedByIgnition" SG_ 813 MO_LPG_Tankstopp 0;
BA_ "GenSigSwitchedByIgnition" SG_ 813 MO_LPG_Ueberlauf 0;
BA_ "GenSigSwitchedByIgnition" SG_ 813 MO_Tankmasse_CNG 0;
BA_ "Fehlerwert" SG_ 813 MO_Tankmasse_CNG 255;
BA_ "GenSigSwitchedByIgnition" SG_ 813 MO_Tankvolumen_LPG 0;
BA_ "Fehlerwert" SG_ 813 MO_Tankvolumen_LPG 255;
BA_ "GenSigSwitchedByIgnition" SG_ 813 MO_Verbrauch_CNG 0;
BA_ "GenSigSwitchedByIgnition" SG_ 813 MO_Verbrauch_LPG 0;
BA_ "GenSigSendType" SG_ 813 MO_Verbrauchsaequivalent 0;
BA_ "GenSigStartValue" SG_ 813 MO_Verbrauchsaequivalent 254;
BA_ "GenSigSwitchedByIgnition" SG_ 813 MO_Verbrauchsaequivalent 0;
BA_ "Fehlerwert" SG_ 813 MO_Verbrauchsaequivalent 255;
BA_ "GenSigSendType" SG_ 2589284112 MO_VTD_CDEODT_L 0;
BA_ "GenSigStartValue" SG_ 2589284112 MO_VTD_CDEODT_L 4294967294;
BA_ "GenSigSwitchedByIgnition" SG_ 2589284112 MO_VTD_CDEODT_L 0;
BA_ "Fehlerwert" SG_ 2589284112 MO_VTD_CDEODT_L 4294967295;
BA_ "GenSigSendType" SG_ 2589284112 MO_VTD_TD_L 0;
BA_ "GenSigStartValue" SG_ 2589284112 MO_VTD_TD_L 4294967294;
BA_ "GenSigSwitchedByIgnition" SG_ 2589284112 MO_VTD_TD_L 0;
BA_ "Fehlerwert" SG_ 2589284112 MO_VTD_TD_L 4294967295;
BA_ "GenSigSendType" SG_ 2589284113 SOK_Motor_VTD_01_Signatur 0;
BA_ "GenSigFuncType" SG_ 2589284113 SOK_Motor_VTD_01_Signatur 15;
BA_ "GenSigSwitchedByIgnition" SG_ 2589284113 SOK_Motor_VTD_01_Signatur 0;
BA_ "GenSigSendType" SG_ 2589284114 MO_VTD_CDERDT_L 0;
BA_ "GenSigStartValue" SG_ 2589284114 MO_VTD_CDERDT_L 4294967294;
BA_ "GenSigSwitchedByIgnition" SG_ 2589284114 MO_VTD_CDERDT_L 0;
BA_ "Fehlerwert" SG_ 2589284114 MO_VTD_CDERDT_L 4294967295;
BA_ "GenSigSendType" SG_ 2589284114 MO_VTD_CDFC_L 0;
BA_ "GenSigStartValue" SG_ 2589284114 MO_VTD_CDFC_L 4294967294;
BA_ "GenSigSwitchedByIgnition" SG_ 2589284114 MO_VTD_CDFC_L 0;
BA_ "Fehlerwert" SG_ 2589284114 MO_VTD_CDFC_L 4294967295;
BA_ "GenSigSendType" SG_ 2589284115 SOK_Motor_VTD_02_Signatur 0;
BA_ "GenSigFuncType" SG_ 2589284115 SOK_Motor_VTD_02_Signatur 15;
BA_ "GenSigSwitchedByIgnition" SG_ 2589284115 SOK_Motor_VTD_02_Signatur 0;
BA_ "GenSigSendType" SG_ 2589284116 MO_VTD_CIDT_L 0;
BA_ "GenSigStartValue" SG_ 2589284116 MO_VTD_CIDT_L 4294967294;
BA_ "GenSigSwitchedByIgnition" SG_ 2589284116 MO_VTD_CIDT_L 0;
BA_ "Fehlerwert" SG_ 2589284116 MO_VTD_CIDT_L 4294967295;
BA_ "GenSigSendType" SG_ 2589284116 MO_VTD_GE_L 0;
BA_ "GenSigStartValue" SG_ 2589284116 MO_VTD_GE_L 4294967294;
BA_ "GenSigSwitchedByIgnition" SG_ 2589284116 MO_VTD_GE_L 0;
BA_ "Fehlerwert" SG_ 2589284116 MO_VTD_GE_L 4294967295;
BA_ "GenSigSendType" SG_ 2589284117 SOK_Motor_VTD_03_Signatur 0;
BA_ "GenSigFuncType" SG_ 2589284117 SOK_Motor_VTD_03_Signatur 15;
BA_ "GenSigSwitchedByIgnition" SG_ 2589284117 SOK_Motor_VTD_03_Signatur 0;
BA_ "GenSigSendType" SG_ 2589284118 MO_VTD_CIFC_L 0;
BA_ "GenSigStartValue" SG_ 2589284118 MO_VTD_CIFC_L 4294967294;
BA_ "GenSigSwitchedByIgnition" SG_ 2589284118 MO_VTD_CIFC_L 0;
BA_ "Fehlerwert" SG_ 2589284118 MO_VTD_CIFC_L 4294967295;
BA_ "GenSigSendType" SG_ 2589284118 MO_VTD_FC_L 0;
BA_ "GenSigStartValue" SG_ 2589284118 MO_VTD_FC_L 4294967294;
BA_ "GenSigSwitchedByIgnition" SG_ 2589284118 MO_VTD_FC_L 0;
BA_ "Fehlerwert" SG_ 2589284118 MO_VTD_FC_L 4294967295;
BA_ "GenSigSendType" SG_ 2589284119 SOK_Motor_VTD_04_Signatur 0;
BA_ "GenSigFuncType" SG_ 2589284119 SOK_Motor_VTD_04_Signatur 15;
BA_ "GenSigSwitchedByIgnition" SG_ 2589284119 SOK_Motor_VTD_04_Signatur 0;
BA_ "GenSigSendType" SG_ 2583737729 NAD_AuthTime_SSN_Req_Data 3;
BA_ "GenSigFuncType" SG_ 2583737729 NAD_AuthTime_SSN_Req_Data 9;
BA_ "GenSigSwitchedByIgnition" SG_ 2583737729 NAD_AuthTime_SSN_Req_Data 0;
BA_ "GenSigSendType" SG_ 2583868801 NAD_AuthTime_SSN_Resp_Data 3;
BA_ "GenSigFuncType" SG_ 2583868801 NAD_AuthTime_SSN_Resp_Data 9;
BA_ "GenSigSwitchedByIgnition" SG_ 2583868801 NAD_AuthTime_SSN_Resp_Data 0;
BA_ "GenSigSendType" SG_ 1156 ND_GDOP 0;
BA_ "GenSigStartValue" SG_ 1156 ND_GDOP 254;
BA_ "GenSigSwitchedByIgnition" SG_ 1156 ND_GDOP 0;
BA_ "Fehlerwert" SG_ 1156 ND_GDOP 1023;
BA_ "GenSigSendType" SG_ 1156 ND_HDOP 0;
BA_ "GenSigStartValue" SG_ 1156 ND_HDOP 1022;
BA_ "GenSigSwitchedByIgnition" SG_ 1156 ND_HDOP 0;
BA_ "Fehlerwert" SG_ 1156 ND_HDOP 1023;
BA_ "GenSigSendType" SG_ 1156 ND_Heading 0;
BA_ "GenSigStartValue" SG_ 1156 ND_Heading 1022;
BA_ "GenSigSwitchedByIgnition" SG_ 1156 ND_Heading 0;
BA_ "Fehlerwert" SG_ 1156 ND_Heading 4095;
BA_ "GenSigSendType" SG_ 1156 ND_Init 0;
BA_ "GenSigSwitchedByIgnition" SG_ 1156 ND_Init 0;
BA_ "GenSigSendType" SG_ 1156 ND_PDOP 0;
BA_ "GenSigStartValue" SG_ 1156 ND_PDOP 1022;
BA_ "GenSigSwitchedByIgnition" SG_ 1156 ND_PDOP 0;
BA_ "Fehlerwert" SG_ 1156 ND_PDOP 1023;
BA_ "GenSigSendType" SG_ 1156 ND_TDOP 0;
BA_ "GenSigStartValue" SG_ 1156 ND_TDOP 1022;
BA_ "GenSigSwitchedByIgnition" SG_ 1156 ND_TDOP 0;
BA_ "Fehlerwert" SG_ 1156 ND_TDOP 1023;
BA_ "GenSigSendType" SG_ 1156 ND_VDOP 0;
BA_ "GenSigStartValue" SG_ 1156 ND_VDOP 1022;
BA_ "GenSigSwitchedByIgnition" SG_ 1156 ND_VDOP 0;
BA_ "Fehlerwert" SG_ 1156 ND_VDOP 1023;
BA_ "GenSigSendType" SG_ 1157 ND_SatInUse 0;
BA_ "GenSigStartValue" SG_ 1157 ND_SatInUse 30;
BA_ "GenSigSwitchedByIgnition" SG_ 1157 ND_SatInUse 0;
BA_ "Fehlerwert" SG_ 1157 ND_SatInUse 31;
BA_ "GenSigSendType" SG_ 1157 ND_SatInView 0;
BA_ "GenSigStartValue" SG_ 1157 ND_SatInView 30;
BA_ "GenSigSwitchedByIgnition" SG_ 1157 ND_SatInView 0;
BA_ "Fehlerwert" SG_ 1157 ND_SatInView 31;
BA_ "GenSigSendType" SG_ 1157 ND_UTC 0;
BA_ "GenSigStartValue" SG_ 1157 ND_UTC 1022;
BA_ "GenSigSwitchedByIgnition" SG_ 1157 ND_UTC 0;
BA_ "GenSigSendType" SG_ 1157 NP_Altitude 0;
BA_ "GenSigStartValue" SG_ 1157 NP_Altitude 4094;
BA_ "GenSigSwitchedByIgnition" SG_ 1157 NP_Altitude 0;
BA_ "Fehlerwert" SG_ 1157 NP_Altitude 4095;
BA_ "GenSigSendType" SG_ 1157 POS_Guete_horizontal 0;
BA_ "GenSigStartValue" SG_ 1157 POS_Guete_horizontal 126;
BA_ "GenSigSwitchedByIgnition" SG_ 1157 POS_Guete_horizontal 0;
BA_ "Fehlerwert" SG_ 1157 POS_Guete_horizontal 127;
BA_ "GenSigSendType" SG_ 1157 POS_Guete_horizontal_verfuegbar 0;
BA_ "GenSigSwitchedByIgnition" SG_ 1157 POS_Guete_horizontal_verfuegbar 0;
BA_ "GenSigSendType" SG_ 2527679512 ND_Fuelstation_detected 0;
BA_ "GenSigStartValue" SG_ 2527679512 ND_Fuelstation_detected 3;
BA_ "GenSigSwitchedByIgnition" SG_ 2527679512 ND_Fuelstation_detected 0;
BA_ "GenSigSendType" SG_ 2527679512 ND_NrSameMeasure 0;
BA_ "GenSigSwitchedByIgnition" SG_ 2527679512 ND_NrSameMeasure 0;
BA_ "GenSigSendType" SG_ 2527679512 ND_RecDelay 0;
BA_ "GenSigStartValue" SG_ 2527679512 ND_RecDelay 4094;
BA_ "GenSigSwitchedByIgnition" SG_ 2527679512 ND_RecDelay 0;
BA_ "Fehlerwert" SG_ 2527679512 ND_RecDelay 4095;
BA_ "GenSigSendType" SG_ 2527679512 ND_RouteType 0;
BA_ "GenSigSwitchedByIgnition" SG_ 2527679512 ND_RouteType 0;
BA_ "GenSigSendType" SG_ 2527679512 ND_SendDelay 0;
BA_ "GenSigStartValue" SG_ 2527679512 ND_SendDelay 4094;
BA_ "GenSigSwitchedByIgnition" SG_ 2527679512 ND_SendDelay 0;
BA_ "Fehlerwert" SG_ 2527679512 ND_SendDelay 4095;
BA_ "GenSigSendType" SG_ 2527679512 ND_TimeOffset 0;
BA_ "GenSigSwitchedByIgnition" SG_ 2527679512 ND_TimeOffset 0;
BA_ "GenSigSendType" SG_ 2527679512 ND_TimeToDestination 0;
BA_ "GenSigStartValue" SG_ 2527679512 ND_TimeToDestination 511;
BA_ "GenSigSwitchedByIgnition" SG_ 2527679512 ND_TimeToDestination 0;
BA_ "Fehlerwert" SG_ 2527679512 ND_TimeToDestination 510;
BA_ "GenSigSendType" SG_ 2527679512 ND_Timezone_DaylightSavingOffset 0;
BA_ "GenSigSwitchedByIgnition" SG_ 2527679512 ND_Timezone_DaylightSavingOffset 0;
BA_ "GenSigSendType" SG_ 2527679512 ND_Timezone_Offset 0;
BA_ "GenSigStartValue" SG_ 2527679512 ND_Timezone_Offset 14;
BA_ "GenSigSwitchedByIgnition" SG_ 2527679512 ND_Timezone_Offset 0;
BA_ "Fehlerwert" SG_ 2527679512 ND_Timezone_Offset 15;
BA_ "GenSigSendType" SG_ 2527679512 ND_Timezone_SignBit 0;
BA_ "GenSigSwitchedByIgnition" SG_ 2527679512 ND_Timezone_SignBit 0;
BA_ "GenSigSendType" SG_ 2527679512 ND_Timezone_Validity 0;
BA_ "GenSigSwitchedByIgnition" SG_ 2527679512 ND_Timezone_Validity 0;
BA_ "GenSigSendType" SG_ 2527679512 ND_Velocity 0;
BA_ "GenSigStartValue" SG_ 2527679512 ND_Velocity 1022;
BA_ "GenSigSwitchedByIgnition" SG_ 2527679512 ND_Velocity 0;
BA_ "Fehlerwert" SG_ 2527679512 ND_Velocity 1023;
BA_ "GenSigSendType" SG_ 2527679665 ND_Avrg_Speed_RangeData 0;
BA_ "GenSigStartValue" SG_ 2527679665 ND_Avrg_Speed_RangeData 254;
BA_ "GenSigSwitchedByIgnition" SG_ 2527679665 ND_Avrg_Speed_RangeData 0;
BA_ "Fehlerwert" SG_ 2527679665 ND_Avrg_Speed_RangeData 255;
BA_ "GenSigSendType" SG_ 2527679665 ND_PSD_Street_Category 0;
BA_ "GenSigStartValue" SG_ 2527679665 ND_PSD_Street_Category 7;
BA_ "GenSigSwitchedByIgnition" SG_ 2527679665 ND_PSD_Street_Category 0;
BA_ "GenSigSendType" SG_ 2527679770 NavMan_ApproachDistanceInPercent 0;
BA_ "GenSigStartValue" SG_ 2527679770 NavMan_ApproachDistanceInPercent 126;
BA_ "GenSigSwitchedByIgnition" SG_ 2527679770 NavMan_ApproachDistanceInPercent 0;
BA_ "GenSigSendType" SG_ 2527679770 NavMan_DirectionType 0;
BA_ "GenSigSwitchedByIgnition" SG_ 2527679770 NavMan_DirectionType 0;
BA_ "GenSigSendType" SG_ 2527679770 NavMan_Distance 0;
BA_ "GenSigSendType" SG_ 2527679770 NavMan_Distance_Unit 0;
BA_ "GenSigSendType" SG_ 2527679770 NavMan_MainType 0;
BA_ "GenSigSwitchedByIgnition" SG_ 2527679770 NavMan_MainType 0;
BA_ "GenSigSendType" SG_ 1158 NP_Fix 0;
BA_ "GenSigSwitchedByIgnition" SG_ 1158 NP_Fix 0;
BA_ "GenSigSendType" SG_ 1158 NP_LatDegree 0;
BA_ "GenSigStartValue" SG_ 1158 NP_LatDegree 134217726;
BA_ "GenSigSwitchedByIgnition" SG_ 1158 NP_LatDegree 0;
BA_ "Fehlerwert" SG_ 1158 NP_LatDegree 134217727;
BA_ "GenSigSendType" SG_ 1158 NP_LatDirection 0;
BA_ "GenSigStartValue" SG_ 1158 NP_LatDirection 1;
BA_ "GenSigSwitchedByIgnition" SG_ 1158 NP_LatDirection 0;
BA_ "GenSigSendType" SG_ 1158 NP_LongDegree 0;
BA_ "GenSigStartValue" SG_ 1158 NP_LongDegree 268435454;
BA_ "GenSigSwitchedByIgnition" SG_ 1158 NP_LongDegree 0;
BA_ "Fehlerwert" SG_ 1158 NP_LongDegree 268435455;
BA_ "GenSigSendType" SG_ 1158 NP_LongDirection 0;
BA_ "GenSigStartValue" SG_ 1158 NP_LongDirection 1;
BA_ "GenSigSwitchedByIgnition" SG_ 1158 NP_LongDirection 0;
BA_ "GenSigSendType" SG_ 1158 NP_Sat 0;
BA_ "GenSigStartValue" SG_ 1158 NP_Sat 30;
BA_ "GenSigSwitchedByIgnition" SG_ 1158 NP_Sat 0;
BA_ "Fehlerwert" SG_ 1158 NP_Sat 31;
BA_ "GenSigSwitchedByIgnition" SG_ 2589283496 POS_Heading 0;
BA_ "GenSigSwitchedByIgnition" SG_ 2589283496 POS_Heading_Trust 0;
BA_ "Fehlerwert" SG_ 2589283496 POS_Heading_Trust 3;
BA_ "GenSigSwitchedByIgnition" SG_ 2589283496 POS_Last_GPS_Sync 0;
BA_ "GenSigStartValue" SG_ 2589283496 POS_LatDegree 134217726;
BA_ "GenSigSwitchedByIgnition" SG_ 2589283496 POS_LatDegree 0;
BA_ "Fehlerwert" SG_ 2589283496 POS_LatDegree 134217727;
BA_ "GenSigSwitchedByIgnition" SG_ 2589283496 POS_LatDirection 0;
BA_ "GenSigStartValue" SG_ 2589283496 POS_LongDegree 268435454;
BA_ "GenSigSwitchedByIgnition" SG_ 2589283496 POS_LongDegree 0;
BA_ "Fehlerwert" SG_ 2589283496 POS_LongDegree 268435455;
BA_ "GenSigSwitchedByIgnition" SG_ 2589283496 POS_LongDirection 0;
BA_ "GenSigSendType" SG_ 2589283496 POS_MUX 0;
BA_ "GenSigStartValue" SG_ 2589283496 POS_MUX 3;
BA_ "GenSigSwitchedByIgnition" SG_ 2589283496 POS_MUX 0;
BA_ "GenSigSendType" SG_ 2589283496 POS_ODD_EVEN 0;
BA_ "GenSigSwitchedByIgnition" SG_ 2589283496 POS_ODD_EVEN 0;
BA_ "GenSigSwitchedByIgnition" SG_ 2589283496 POS_PosStati 0;
BA_ "GenSigSwitchedByIgnition" SG_ 2589283496 POS_UTC_REF 0;
BA_ "GenSigSendType" SG_ 2527679645 NFC_MiKo_ESM_aktiv 0;
BA_ "GenSigSwitchedByIgnition" SG_ 2527679645 NFC_MiKo_ESM_aktiv 0;
BA_ "GenSigSendType" SG_ 2527679645 NFC_MiKo_Fehler 0;
BA_ "GenSigSwitchedByIgnition" SG_ 2527679645 NFC_MiKo_Fehler 0;
BA_ "GenSigSendType" SG_ 2527679645 NFC_MiKo_Laden_unterbrechen 0;
BA_ "GenSigSwitchedByIgnition" SG_ 2527679645 NFC_MiKo_Laden_unterbrechen 0;
BA_ "GenSigSendType" SG_ 2527679645 NFC_MiKo_NFC_Device_gekoppelt 0;
BA_ "GenSigSwitchedByIgnition" SG_ 2527679645 NFC_MiKo_NFC_Device_gekoppelt 0;
BA_ "GenSigSendType" SG_ 2527679645 NFC_MiKo_NFC_Device_Status 0;
BA_ "GenSigSwitchedByIgnition" SG_ 2527679645 NFC_MiKo_NFC_Device_Status 0;
BA_ "GenSigFuncType" SG_ 2600468788 NM_BedienDisp_m_CAB_V14 16;
BA_ "GenSigSwitchedByIgnition" SG_ 2600468788 NM_BedienDisp_m_CAB_V14 0;
BA_ "GenSigSwitchedByIgnition" SG_ 2600468788 NM_BedienDisp_m_Car_Wakeup 0;
BA_ "GenSigSwitchedByIgnition" SG_ 2600468788 NM_BedienDisp_m_CBV_AWB 0;
BA_ "GenSigSwitchedByIgnition" SG_ 2600468788 NM_BedienDisp_m_CBV_CRI 0;
BA_ "GenSigSwitchedByIgnition" SG_ 2600468788 NM_BedienDisp_m_NM_aktiv_Diagnos 0;
BA_ "GenSigSwitchedByIgnition" SG_ 2600468788 NM_BedienDisp_m_NM_aktiv_KL15 0;
BA_ "GenSigSwitchedByIgnition" SG_ 2600468788 NM_BedienDisp_m_NM_aktiv_Tmin 0;
BA_ "GenSigSwitchedByIgnition" SG_ 2600468788 NM_BedienDisp_m_NM_State 0;
BA_ "GenSigSwitchedByIgnition" SG_ 2600468788 NM_BedienDisp_m_UDS_CC 0;
BA_ "GenSigFuncType" SG_ 2600468642 NM_BedienDisp_vm_CAB_V14 16;
BA_ "GenSigSwitchedByIgnition" SG_ 2600468642 NM_BedienDisp_vm_CAB_V14 0;
BA_ "GenSigSwitchedByIgnition" SG_ 2600468642 NM_BedienDisp_vm_Car_Wakeup 0;
BA_ "GenSigSwitchedByIgnition" SG_ 2600468642 NM_BedienDisp_vm_CBV_AWB 0;
BA_ "GenSigStartValue" SG_ 2600468642 NM_BedienDisp_vm_CBV_CRI 1;
BA_ "GenSigSwitchedByIgnition" SG_ 2600468642 NM_BedienDisp_vm_CBV_CRI 0;
BA_ "GenSigSwitchedByIgnition" SG_ 2600468642 NM_BedienDisp_vm_NM_aktiv_Diag 0;
BA_ "GenSigSwitchedByIgnition" SG_ 2600468642 NM_BedienDisp_vm_NM_aktiv_KL15 0;
BA_ "GenSigSwitchedByIgnition" SG_ 2600468642 NM_BedienDisp_vm_NM_aktiv_Tmin 0;
BA_ "GenSigSwitchedByIgnition" SG_ 2600468642 NM_BedienDisp_vm_NM_State 0;
BA_ "GenSigSwitchedByIgnition" SG_ 2600468642 NM_BedienDisp_vm_UDS_CC 0;
BA_ "GenSigFuncType" SG_ 2600468583 NM_eCall_CAB_V14 16;
BA_ "GenSigSwitchedByIgnition" SG_ 2600468583 NM_eCall_CAB_V14 0;
BA_ "GenSigSwitchedByIgnition" SG_ 2600468583 NM_eCall_Car_Wakeup 0;
BA_ "GenSigSwitchedByIgnition" SG_ 2600468583 NM_eCall_CBV_AWB 0;
BA_ "GenSigSwitchedByIgnition" SG_ 2600468583 NM_eCall_CBV_CRI 0;
BA_ "GenSigSwitchedByIgnition" SG_ 2600468583 NM_eCall_NM_aktiv_Call 0;
BA_ "GenSigSwitchedByIgnition" SG_ 2600468583 NM_eCall_NM_aktiv_Diagnose 0;
BA_ "GenSigSwitchedByIgnition" SG_ 2600468583 NM_eCall_NM_aktiv_Dienstabfrage 0;
BA_ "GenSigSwitchedByIgnition" SG_ 2600468583 NM_eCall_NM_aktiv_IAA 0;
BA_ "GenSigSwitchedByIgnition" SG_ 2600468583 NM_eCall_NM_aktiv_KL15 0;
BA_ "GenSigSwitchedByIgnition" SG_ 2600468583 NM_eCall_NM_aktiv_Klimatisieren 0;
BA_ "GenSigSwitchedByIgnition" SG_ 2600468583 NM_eCall_NM_aktiv_Laden 0;
BA_ "GenSigSwitchedByIgnition" SG_ 2600468583 NM_eCall_NM_aktiv_MQTT_GW 0;
BA_ "GenSigSwitchedByIgnition" SG_ 2600468583 NM_eCall_NM_aktiv_ORU_OCU 0;
BA_ "GenSigSwitchedByIgnition" SG_ 2600468583 NM_eCall_NM_aktiv_PSO 0;
BA_ "GenSigSwitchedByIgnition" SG_ 2600468583 NM_eCall_NM_aktiv_Remote_Control 0;
BA_ "GenSigSwitchedByIgnition" SG_ 2600468583 NM_eCall_NM_aktiv_RemoteStart 0;
BA_ "GenSigSwitchedByIgnition" SG_ 2600468583 NM_eCall_NM_aktiv_Settings 0;
BA_ "GenSigSwitchedByIgnition" SG_ 2600468583 NM_eCall_NM_aktiv_Status 0;
BA_ "GenSigSwitchedByIgnition" SG_ 2600468583 NM_eCall_NM_aktiv_Tmin 0;
BA_ "GenSigSwitchedByIgnition" SG_ 2600468583 NM_eCall_NM_State 0;
BA_ "GenSigSwitchedByIgnition" SG_ 2600468583 NM_eCall_UDS_CC 0;
BA_REL_ "GenSigTimeoutTime" BU_SG_REL_ BedienDisp_mi SG_ 2600468642 NM_BedienDisp_vm_NM_State 2000;
BA_REL_ "GenSigTimeoutTime" BU_SG_REL_ BedienDisp_mi SG_ 2600468583 NM_eCall_NM_State 2000;
BA_REL_ "GenSigTimeoutTime" BU_SG_REL_ BedienDisp_vo_mi SG_ 2600468788 NM_BedienDisp_m_NM_State 2000;
BA_REL_ "GenSigTimeoutTime" BU_SG_REL_ BedienDisp_vo_mi SG_ 2600468583 NM_eCall_NM_State 2000;
BA_REL_ "GenSigTimeoutTime" BU_SG_REL_ CDI SG_ 2589283496 POS_LatDegree 5000;
BA_REL_ "GenSigTimeoutTime" BU_SG_REL_ CDI SG_ 2589283496 POS_LongDegree 5000;
BA_REL_ "GenSigTimeoutTime" BU_SG_REL_ CDI SG_ 2600468788 NM_BedienDisp_m_NM_State 2000;
BA_REL_ "GenSigTimeoutTime" BU_SG_REL_ CDI SG_ 2600468642 NM_BedienDisp_vm_NM_State 2000;
BA_REL_ "GenSigTimeoutTime" BU_SG_REL_ CDI SG_ 2600468583 NM_eCall_NM_State 2000;
BA_REL_ "GenSigTimeoutTime" BU_SG_REL_ ConMod_CD SG_ 1648 MO_Fahrzeugtyp 5000;
BA_REL_ "GenSigTimeoutTime" BU_SG_REL_ ConMod_CD SG_ 1601 MO_Hybridfahrzeug 5000;
BA_REL_ "GenSigTimeoutTime" BU_SG_REL_ ConMod_CD SG_ 1601 MO_Kraftstoffart 5000;
BA_REL_ "GenSigTimeoutTime" BU_SG_REL_ ConMod_CD SG_ 2527679665 ND_PSD_Street_Category 2000;
BA_REL_ "GenSigTimeoutTime" BU_SG_REL_ ConMod_CD SG_ 2600468788 NM_BedienDisp_m_NM_State 2000;
BA_REL_ "GenSigTimeoutTime" BU_SG_REL_ ConMod_CD SG_ 2600468642 NM_BedienDisp_vm_NM_State 2000;
BA_REL_ "GenSigTimeoutTime" BU_SG_REL_ DashCAM SG_ 2600468788 NM_BedienDisp_m_NM_State 2000;
BA_REL_ "GenSigTimeoutTime" BU_SG_REL_ DashCAM SG_ 2600468642 NM_BedienDisp_vm_NM_State 2000;
BA_REL_ "GenSigTimeoutTime" BU_SG_REL_ DashCAM SG_ 2600468583 NM_eCall_NM_State 2000;
BA_REL_ "GenSigTimeoutTime" BU_SG_REL_ Gateway_Max SG_ 1156 ND_Heading 2000;
BA_REL_ "GenSigTimeoutTime" BU_SG_REL_ Gateway_Max SG_ 1157 ND_UTC 2000;
BA_REL_ "GenSigTimeoutTime" BU_SG_REL_ Gateway_Max SG_ 1158 NP_LatDegree 2000;
BA_REL_ "GenSigTimeoutTime" BU_SG_REL_ Gateway_Max SG_ 1158 NP_LongDegree 2000;
BA_REL_ "GenSigTimeoutTime" BU_SG_REL_ Gateway_Max SG_ 1158 NP_LatDirection 2000;
BA_REL_ "GenSigTimeoutTime" BU_SG_REL_ Gateway_Max SG_ 1158 NP_LongDirection 2000;
BA_REL_ "GenSigTimeoutTime" BU_SG_REL_ Gateway_Max SG_ 1158 NP_Fix 2000;
BA_REL_ "GenSigTimeoutTime" BU_SG_REL_ Gateway_Max SG_ 2589283496 POS_MUX 5000;
BA_REL_ "GenSigTimeoutTime" BU_SG_REL_ Gateway_Max SG_ 2589283496 POS_ODD_EVEN 5000;
BA_REL_ "GenSigTimeoutTime" BU_SG_REL_ Gateway_Max SG_ 2589283496 POS_PosStati 5000;
BA_REL_ "GenSigTimeoutTime" BU_SG_REL_ Gateway_Max SG_ 2589283496 POS_Heading 5000;
BA_REL_ "GenSigTimeoutTime" BU_SG_REL_ Gateway_Max SG_ 2589283496 POS_LatDirection 5000;
BA_REL_ "GenSigTimeoutTime" BU_SG_REL_ Gateway_Max SG_ 2589283496 POS_LatDegree 5000;
BA_REL_ "GenSigTimeoutTime" BU_SG_REL_ Gateway_Max SG_ 2589283496 POS_UTC_REF 5000;
BA_REL_ "GenSigTimeoutTime" BU_SG_REL_ Gateway_Max SG_ 2589283496 POS_LongDirection 5000;
BA_REL_ "GenSigTimeoutTime" BU_SG_REL_ Gateway_Max SG_ 2589283496 POS_LongDegree 5000;
BA_REL_ "GenSigTimeoutTime" BU_SG_REL_ Gateway_Max SG_ 2600468788 NM_BedienDisp_m_CBV_AWB 2000;
BA_REL_ "GenSigTimeoutTime" BU_SG_REL_ Gateway_Max SG_ 2600468788 NM_BedienDisp_m_CBV_CRI 2000;
BA_REL_ "GenSigTimeoutTime" BU_SG_REL_ Gateway_Max SG_ 2600468788 NM_BedienDisp_m_Car_Wakeup 2000;
BA_REL_ "GenSigTimeoutTime" BU_SG_REL_ Gateway_Max SG_ 2600468788 NM_BedienDisp_m_CAB_V14 2000;
BA_REL_ "GenSigTimeoutTime" BU_SG_REL_ Gateway_Max SG_ 2600468642 NM_BedienDisp_vm_CBV_AWB 2000;
BA_REL_ "GenSigTimeoutTime" BU_SG_REL_ Gateway_Max SG_ 2600468642 NM_BedienDisp_vm_CBV_CRI 2000;
BA_REL_ "GenSigTimeoutTime" BU_SG_REL_ Gateway_Max SG_ 2600468642 NM_BedienDisp_vm_Car_Wakeup 2000;
BA_REL_ "GenSigTimeoutTime" BU_SG_REL_ Gateway_Max SG_ 2600468642 NM_BedienDisp_vm_CAB_V14 2000;
BA_REL_ "GenSigTimeoutTime" BU_SG_REL_ Gateway_Max SG_ 2600468583 NM_eCall_CBV_AWB 2000;
BA_REL_ "GenSigTimeoutTime" BU_SG_REL_ Gateway_Max SG_ 2600468583 NM_eCall_CBV_CRI 2000;
BA_REL_ "GenSigTimeoutTime" BU_SG_REL_ Gateway_Max SG_ 2600468583 NM_eCall_Car_Wakeup 2000;
BA_REL_ "GenSigTimeoutTime" BU_SG_REL_ Gateway_Max SG_ 2600468583 NM_eCall_CAB_V14 2000;
BA_REL_ "GenSigTimeoutTime" BU_SG_REL_ ICC_IO_Node SG_ 958 MO_Kl_50 1000;
BA_REL_ "GenSigTimeoutTime" BU_SG_REL_ ICC_IO_Node SG_ 2600468788 NM_BedienDisp_m_NM_State 2000;
BA_REL_ "GenSigTimeoutTime" BU_SG_REL_ ICC_IO_Node SG_ 2600468642 NM_BedienDisp_vm_NM_State 2000;
BA_REL_ "GenSigTimeoutTime" BU_SG_REL_ ICC_IO_Node SG_ 2600468583 NM_eCall_NM_State 2000;
BA_REL_ "GenSigTimeoutTime" BU_SG_REL_ LSH SG_ 1600 MO_Hoeheninfo 5000;
BA_REL_ "GenSigTimeoutTime" BU_SG_REL_ LSH SG_ 1607 MO_E85_Sensor 5000;
BA_REL_ "GenSigTimeoutTime" BU_SG_REL_ LSH SG_ 958 MO_StartStopp_Wiederstart 1000;
BA_REL_ "GenSigTimeoutTime" BU_SG_REL_ LSH SG_ 958 MO_StartStopp_Motorstopp 1000;
BA_REL_ "GenSigTimeoutTime" BU_SG_REL_ LSH SG_ 958 MO_Motor_laeuft 1000;
BA_REL_ "GenSigTimeoutTime" BU_SG_REL_ LSH SG_ 1601 MO_Kraftstoffart 5000;
BA_REL_ "GenSigTimeoutTime" BU_SG_REL_ LSH SG_ 2600468788 NM_BedienDisp_m_NM_State 2000;
BA_REL_ "GenSigTimeoutTime" BU_SG_REL_ LSH SG_ 2600468642 NM_BedienDisp_vm_NM_State 2000;
BA_REL_ "GenSigTimeoutTime" BU_SG_REL_ LSH SG_ 2600468583 NM_eCall_NM_State 2000;
BA_REL_ "GenSigTimeoutTime" BU_SG_REL_ OCU SG_ 263 MO_Istgang 500;
BA_REL_ "GenSigTimeoutTime" BU_SG_REL_ OCU SG_ 263 MO_Sollgang 500;
BA_REL_ "GenSigTimeoutTime" BU_SG_REL_ OCU SG_ 263 MO_Anzeigedrehz 500;
BA_REL_ "GenSigTimeoutTime" BU_SG_REL_ OCU SG_ 263 MO_Fehler_Oeldrucksensor 500;
BA_REL_ "GenSigTimeoutTime" BU_SG_REL_ OCU SG_ 263 MO_Schaltempf_verfbar 500;
BA_REL_ "GenSigTimeoutTime" BU_SG_REL_ OCU SG_ 263 MO_Ladedruck 500;
BA_REL_ "GenSigTimeoutTime" BU_SG_REL_ OCU SG_ 263 MO_KVS 500;
BA_REL_ "GenSigTimeoutTime" BU_SG_REL_ OCU SG_ 263 MO_KVS_Ueberlauf 500;
BA_REL_ "GenSigTimeoutTime" BU_SG_REL_ OCU SG_ 1600 MO_QBit_Oel_Temp 5000;
BA_REL_ "GenSigTimeoutTime" BU_SG_REL_ OCU SG_ 1600 MO_QBit_Kuehlmittel_Temp 5000;
BA_REL_ "GenSigTimeoutTime" BU_SG_REL_ OCU SG_ 1600 MO_Ansaugluft_Temp 5000;
BA_REL_ "GenSigTimeoutTime" BU_SG_REL_ OCU SG_ 1600 MO_Oel_Temp 5000;
BA_REL_ "GenSigTimeoutTime" BU_SG_REL_ OCU SG_ 1600 MO_Kuehlmittel_Temp 5000;
BA_REL_ "GenSigTimeoutTime" BU_SG_REL_ OCU SG_ 1600 MO_Hoeheninfo 5000;
BA_REL_ "GenSigTimeoutTime" BU_SG_REL_ OCU SG_ 1600 MO_Mom_Traegheit_02 5000;
BA_REL_ "GenSigTimeoutTime" BU_SG_REL_ OCU SG_ 167 MO_Mom_Ist_Summe 500;
BA_REL_ "GenSigTimeoutTime" BU_SG_REL_ OCU SG_ 958 MO_StartStopp_Status 1000;
BA_REL_ "GenSigTimeoutTime" BU_SG_REL_ OCU SG_ 958 MO_StartStopp_Motorstopp 1000;
BA_REL_ "GenSigTimeoutTime" BU_SG_REL_ OCU SG_ 958 MO_Kl_75 1000;
BA_REL_ "GenSigTimeoutTime" BU_SG_REL_ OCU SG_ 958 MO_Kl_50 1000;
BA_REL_ "GenSigTimeoutTime" BU_SG_REL_ OCU SG_ 958 MO_Gangposition 1000;
BA_REL_ "GenSigTimeoutTime" BU_SG_REL_ OCU SG_ 958 MO_HYB_Fahrbereitschaft 1000;
BA_REL_ "GenSigTimeoutTime" BU_SG_REL_ OCU SG_ 958 MO_Fahrer_bremst 1000;
BA_REL_ "GenSigTimeoutTime" BU_SG_REL_ OCU SG_ 958 MO_QBit_Fahrer_bremst 1000;
BA_REL_ "GenSigTimeoutTime" BU_SG_REL_ OCU SG_ 958 MO_Kuppl_schalter 1000;
BA_REL_ "GenSigTimeoutTime" BU_SG_REL_ OCU SG_ 958 MO_Motor_laeuft 1000;
BA_REL_ "GenSigTimeoutTime" BU_SG_REL_ OCU SG_ 958 MO_Kickdown 1000;
BA_REL_ "GenSigTimeoutTime" BU_SG_REL_ OCU SG_ 958 MO_QBit_Gangposition 1000;
BA_REL_ "GenSigTimeoutTime" BU_SG_REL_ OCU SG_ 958 MO_Remotestart_Betrieb 1000;
BA_REL_ "GenSigTimeoutTime" BU_SG_REL_ OCU SG_ 1631 TSK_QBit_Steigung 5000;
BA_REL_ "GenSigTimeoutTime" BU_SG_REL_ OCU SG_ 1631 MO_DPF_reg 5000;
BA_REL_ "GenSigTimeoutTime" BU_SG_REL_ OCU SG_ 1631 TSK_Fahrzeugmasse_02 5000;
BA_REL_ "GenSigTimeoutTime" BU_SG_REL_ OCU SG_ 1631 TSK_Steigung_02 5000;
BA_REL_ "GenSigTimeoutTime" BU_SG_REL_ OCU SG_ 1648 MO_EPCL 5000;
BA_REL_ "GenSigTimeoutTime" BU_SG_REL_ OCU SG_ 1648 MO_Fahrzeugtyp 5000;
BA_REL_ "GenSigTimeoutTime" BU_SG_REL_ OCU SG_ 1648 MO_Abstellzeit 5000;
BA_REL_ "GenSigTimeoutTime" BU_SG_REL_ OCU SG_ 289 MO_Fahrpedalrohwert_01 500;
BA_REL_ "GenSigTimeoutTime" BU_SG_REL_ OCU SG_ 289 MO_Fahrpedalgradient 500;
BA_REL_ "GenSigTimeoutTime" BU_SG_REL_ OCU SG_ 289 MO_rel_Saugrohrdruck 500;
BA_REL_ "GenSigTimeoutTime" BU_SG_REL_ OCU SG_ 967 MO_Kuehlerluefter_1 1000;
BA_REL_ "GenSigTimeoutTime" BU_SG_REL_ OCU SG_ 967 MO_Kuehlerluefter_2 1000;
BA_REL_ "GenSigTimeoutTime" BU_SG_REL_ OCU SG_ 967 MO_ITM_Warnung_Pumpe 1000;
BA_REL_ "GenSigTimeoutTime" BU_SG_REL_ OCU SG_ 967 WIV_Oelmin_Warn 1000;
BA_REL_ "GenSigTimeoutTime" BU_SG_REL_ OCU SG_ 967 WIV_Schieflage 1000;
BA_REL_ "GenSigTimeoutTime" BU_SG_REL_ OCU SG_ 967 WIV_Oelstand 1000;
BA_REL_ "GenSigTimeoutTime" BU_SG_REL_ OCU SG_ 967 MO_Oelwarnung_max 1000;
BA_REL_ "GenSigTimeoutTime" BU_SG_REL_ OCU SG_ 967 WIV_nicht_betriebswarm 1000;
BA_REL_ "GenSigTimeoutTime" BU_SG_REL_ OCU SG_ 967 MO_Text_Partikelfil_Reg 1000;
BA_REL_ "GenSigTimeoutTime" BU_SG_REL_ OCU SG_ 967 WIV_Oelmenge 1000;
BA_REL_ "GenSigTimeoutTime" BU_SG_REL_ OCU SG_ 967 MO_Systemlampe 1000;
BA_REL_ "GenSigTimeoutTime" BU_SG_REL_ OCU SG_ 967 MO_OBD2_Lampe 1000;
BA_REL_ "GenSigTimeoutTime" BU_SG_REL_ OCU SG_ 967 MO_Heissleuchte 1000;
BA_REL_ "GenSigTimeoutTime" BU_SG_REL_ OCU SG_ 967 MO_Partikel_Lampe 1000;
BA_REL_ "GenSigTimeoutTime" BU_SG_REL_ OCU SG_ 967 WIV_Oeldr_Warn_Motor 1000;
BA_REL_ "GenSigTimeoutTime" BU_SG_REL_ OCU SG_ 327 MO_Anzeige_Drehmoment 500;
BA_REL_ "GenSigTimeoutTime" BU_SG_REL_ OCU SG_ 1601 MO_Faktor_Momente_02 5000;
BA_REL_ "GenSigTimeoutTime" BU_SG_REL_ OCU SG_ 1601 MO_Hybridfahrzeug 5000;
BA_REL_ "GenSigTimeoutTime" BU_SG_REL_ OCU SG_ 1601 MO_Code 5000;
BA_REL_ "GenSigTimeoutTime" BU_SG_REL_ OCU SG_ 1601 MO_Getriebe_Code 5000;
BA_REL_ "GenSigTimeoutTime" BU_SG_REL_ OCU SG_ 1601 MO_Kraftstoffart 5000;
BA_REL_ "GenSigTimeoutTime" BU_SG_REL_ OCU SG_ 1601 MO_Hubraum 5000;
BA_REL_ "GenSigTimeoutTime" BU_SG_REL_ OCU SG_ 1601 MO_Leistung 5000;
BA_REL_ "GenSigTimeoutTime" BU_SG_REL_ OCU SG_ 1601 MO_OBD_Typ 5000;
BA_REL_ "GenSigTimeoutTime" BU_SG_REL_ OCU SG_ 1601 TSK_Codierung 5000;
BA_REL_ "GenSigTimeoutTime" BU_SG_REL_ OCU SG_ 813 MO_Fuellungsgrad_CNG 500;
BA_REL_ "GenSigTimeoutTime" BU_SG_REL_ OCU SG_ 1156 ND_VDOP 2000;
BA_REL_ "GenSigTimeoutTime" BU_SG_REL_ OCU SG_ 1156 ND_TDOP 2000;
BA_REL_ "GenSigTimeoutTime" BU_SG_REL_ OCU SG_ 1156 ND_HDOP 2000;
BA_REL_ "GenSigTimeoutTime" BU_SG_REL_ OCU SG_ 1156 ND_GDOP 2000;
BA_REL_ "GenSigTimeoutTime" BU_SG_REL_ OCU SG_ 1156 ND_PDOP 2000;
BA_REL_ "GenSigTimeoutTime" BU_SG_REL_ OCU SG_ 1156 ND_Heading 2000;
BA_REL_ "GenSigTimeoutTime" BU_SG_REL_ OCU SG_ 1156 ND_Init 2000;
BA_REL_ "GenSigTimeoutTime" BU_SG_REL_ OCU SG_ 1157 ND_SatInUse 2000;
BA_REL_ "GenSigTimeoutTime" BU_SG_REL_ OCU SG_ 1157 POS_Guete_horizontal_verfuegbar 2000;
BA_REL_ "GenSigTimeoutTime" BU_SG_REL_ OCU SG_ 1157 ND_SatInView 2000;
BA_REL_ "GenSigTimeoutTime" BU_SG_REL_ OCU SG_ 1157 POS_Guete_horizontal 2000;
BA_REL_ "GenSigTimeoutTime" BU_SG_REL_ OCU SG_ 1157 NP_Altitude 2000;
BA_REL_ "GenSigTimeoutTime" BU_SG_REL_ OCU SG_ 1157 ND_UTC 2000;
BA_REL_ "GenSigTimeoutTime" BU_SG_REL_ OCU SG_ 2527679665 ND_PSD_Street_Category 2000;
BA_REL_ "GenSigTimeoutTime" BU_SG_REL_ OCU SG_ 1158 NP_LatDegree 2000;
BA_REL_ "GenSigTimeoutTime" BU_SG_REL_ OCU SG_ 1158 NP_LongDegree 2000;
BA_REL_ "GenSigTimeoutTime" BU_SG_REL_ OCU SG_ 1158 NP_LatDirection 2000;
BA_REL_ "GenSigTimeoutTime" BU_SG_REL_ OCU SG_ 1158 NP_LongDirection 2000;
BA_REL_ "GenSigTimeoutTime" BU_SG_REL_ OCU SG_ 1158 NP_Sat 2000;
BA_REL_ "GenSigTimeoutTime" BU_SG_REL_ OCU SG_ 1158 NP_Fix 2000;
BA_REL_ "GenSigTimeoutTime" BU_SG_REL_ OCU SG_ 2589283496 POS_MUX 5000;
BA_REL_ "GenSigTimeoutTime" BU_SG_REL_ OCU SG_ 2589283496 POS_ODD_EVEN 5000;
BA_REL_ "GenSigTimeoutTime" BU_SG_REL_ OCU SG_ 2589283496 POS_PosStati 5000;
BA_REL_ "GenSigTimeoutTime" BU_SG_REL_ OCU SG_ 2589283496 POS_Heading 5000;
BA_REL_ "GenSigTimeoutTime" BU_SG_REL_ OCU SG_ 2589283496 POS_LatDirection 5000;
BA_REL_ "GenSigTimeoutTime" BU_SG_REL_ OCU SG_ 2589283496 POS_LatDegree 5000;
BA_REL_ "GenSigTimeoutTime" BU_SG_REL_ OCU SG_ 2589283496 POS_Last_GPS_Sync 5000;
BA_REL_ "GenSigTimeoutTime" BU_SG_REL_ OCU SG_ 2589283496 POS_Heading_Trust 5000;
BA_REL_ "GenSigTimeoutTime" BU_SG_REL_ OCU SG_ 2589283496 POS_UTC_REF 5000;
BA_REL_ "GenSigTimeoutTime" BU_SG_REL_ OCU SG_ 2589283496 POS_LongDirection 5000;
BA_REL_ "GenSigTimeoutTime" BU_SG_REL_ OCU SG_ 2589283496 POS_LongDegree 5000;
BA_REL_ "GenSigTimeoutTime" BU_SG_REL_ OCU SG_ 2600468788 NM_BedienDisp_m_NM_State 2000;
BA_REL_ "GenSigTimeoutTime" BU_SG_REL_ OCU SG_ 2600468642 NM_BedienDisp_vm_NM_State 2000;
BA_REL_ "GenSigTimeoutTime" BU_SG_REL_ RDK_RS3 SG_ 2600468788 NM_BedienDisp_m_NM_State 2000;
BA_REL_ "GenSigTimeoutTime" BU_SG_REL_ RDK_RS3 SG_ 2600468642 NM_BedienDisp_vm_NM_State 2000;
BA_REL_ "GenSigTimeoutTime" BU_SG_REL_ RDK_RS3 SG_ 2600468583 NM_eCall_NM_State 2000;
BA_REL_ "GenSigTimeoutTime" BU_SG_REL_ Sound_MIB_ab_Gen3 SG_ 2600468788 NM_BedienDisp_m_NM_State 2000;
BA_REL_ "GenSigTimeoutTime" BU_SG_REL_ Sound_MIB_ab_Gen3 SG_ 2600468642 NM_BedienDisp_vm_NM_State 2000;
BA_REL_ "GenSigTimeoutTime" BU_SG_REL_ Sound_MIB_ab_Gen3 SG_ 2600468583 NM_eCall_NM_State 2000;
BA_REL_ "GenSigTimeoutTime" BU_SG_REL_ STH SG_ 1600 MO_Kuehlmittel_Temp 5000;
BA_REL_ "GenSigTimeoutTime" BU_SG_REL_ STH SG_ 1600 MO_Hoeheninfo 5000;
BA_REL_ "GenSigTimeoutTime" BU_SG_REL_ STH SG_ 1600 MO_Heizungspumpenansteuerung 5000;
BA_REL_ "GenSigTimeoutTime" BU_SG_REL_ STH SG_ 1600 MO_Nachlaufzeit_Heizungspumpe 5000;
BA_REL_ "GenSigTimeoutTime" BU_SG_REL_ STH SG_ 1607 MO_E85_Sensor 5000;
BA_REL_ "GenSigTimeoutTime" BU_SG_REL_ STH SG_ 958 MO_StartStopp_Wiederstart 1000;
BA_REL_ "GenSigTimeoutTime" BU_SG_REL_ STH SG_ 958 MO_StartStopp_Motorstopp 1000;
BA_REL_ "GenSigTimeoutTime" BU_SG_REL_ STH SG_ 958 MO_Kl_50 1000;
BA_REL_ "GenSigTimeoutTime" BU_SG_REL_ STH SG_ 958 MO_Handshake_STH 1000;
BA_REL_ "GenSigTimeoutTime" BU_SG_REL_ STH SG_ 1601 MO_Kraftstoffart 5000;
BA_REL_ "GenSigTimeoutTime" BU_SG_REL_ STH SG_ 2600468788 NM_BedienDisp_m_NM_State 2000;
BA_REL_ "GenSigTimeoutTime" BU_SG_REL_ STH SG_ 2600468642 NM_BedienDisp_vm_NM_State 2000;
BA_REL_ "GenSigTimeoutTime" BU_SG_REL_ STH SG_ 2600468583 NM_eCall_NM_State 2000;
BA_REL_ "GenSigTimeoutTime" BU_SG_REL_ ZR_MIB_EINSTIEG_ab_Gen3 SG_ 263 MO_rel_Ladedruck 500;
BA_REL_ "GenSigTimeoutTime" BU_SG_REL_ ZR_MIB_EINSTIEG_ab_Gen3 SG_ 263 MO_Istgang 500;
BA_REL_ "GenSigTimeoutTime" BU_SG_REL_ ZR_MIB_EINSTIEG_ab_Gen3 SG_ 263 MO_Sollgang 500;
BA_REL_ "GenSigTimeoutTime" BU_SG_REL_ ZR_MIB_EINSTIEG_ab_Gen3 SG_ 263 MO_Anzeigedrehz 500;
BA_REL_ "GenSigTimeoutTime" BU_SG_REL_ ZR_MIB_EINSTIEG_ab_Gen3 SG_ 263 MO_Schaltempf_verfbar 500;
BA_REL_ "GenSigTimeoutTime" BU_SG_REL_ ZR_MIB_EINSTIEG_ab_Gen3 SG_ 263 MO_Ladedruck 500;
BA_REL_ "GenSigTimeoutTime" BU_SG_REL_ ZR_MIB_EINSTIEG_ab_Gen3 SG_ 167 MO_Mom_Ist_Summe 500;
BA_REL_ "GenSigTimeoutTime" BU_SG_REL_ ZR_MIB_EINSTIEG_ab_Gen3 SG_ 958 MO_StartStopp_Status 1000;
BA_REL_ "GenSigTimeoutTime" BU_SG_REL_ ZR_MIB_EINSTIEG_ab_Gen3 SG_ 958 MO_StartStopp_Wiederstart 1000;
BA_REL_ "GenSigTimeoutTime" BU_SG_REL_ ZR_MIB_EINSTIEG_ab_Gen3 SG_ 958 MO_StartStopp_Motorstopp 1000;
BA_REL_ "GenSigTimeoutTime" BU_SG_REL_ ZR_MIB_EINSTIEG_ab_Gen3 SG_ 958 MO_Kl_75 1000;
BA_REL_ "GenSigTimeoutTime" BU_SG_REL_ ZR_MIB_EINSTIEG_ab_Gen3 SG_ 958 MO_Kl_50 1000;
BA_REL_ "GenSigTimeoutTime" BU_SG_REL_ ZR_MIB_EINSTIEG_ab_Gen3 SG_ 958 MO_Gangposition 1000;
BA_REL_ "GenSigTimeoutTime" BU_SG_REL_ ZR_MIB_EINSTIEG_ab_Gen3 SG_ 958 MO_Fahrer_bremst 1000;
BA_REL_ "GenSigTimeoutTime" BU_SG_REL_ ZR_MIB_EINSTIEG_ab_Gen3 SG_ 958 MO_QBit_Fahrer_bremst 1000;
BA_REL_ "GenSigTimeoutTime" BU_SG_REL_ ZR_MIB_EINSTIEG_ab_Gen3 SG_ 958 MO_Kuppl_schalter 1000;
BA_REL_ "GenSigTimeoutTime" BU_SG_REL_ ZR_MIB_EINSTIEG_ab_Gen3 SG_ 958 MO_Kickdown 1000;
BA_REL_ "GenSigTimeoutTime" BU_SG_REL_ ZR_MIB_EINSTIEG_ab_Gen3 SG_ 958 MO_QBit_Gangposition 1000;
BA_REL_ "GenSigTimeoutTime" BU_SG_REL_ ZR_MIB_EINSTIEG_ab_Gen3 SG_ 1631 TSK_QBit_Steigung 5000;
BA_REL_ "GenSigTimeoutTime" BU_SG_REL_ ZR_MIB_EINSTIEG_ab_Gen3 SG_ 1631 TSK_Steigung_02 5000;
BA_REL_ "GenSigTimeoutTime" BU_SG_REL_ ZR_MIB_EINSTIEG_ab_Gen3 SG_ 1648 MO_max_Ladedruck 5000;
BA_REL_ "GenSigTimeoutTime" BU_SG_REL_ ZR_MIB_EINSTIEG_ab_Gen3 SG_ 289 MO_Fahrpedalrohwert_01 500;
BA_REL_ "GenSigTimeoutTime" BU_SG_REL_ ZR_MIB_EINSTIEG_ab_Gen3 SG_ 1391 MO_Anzeige_Drehmoment_Max 5000;
BA_REL_ "GenSigTimeoutTime" BU_SG_REL_ ZR_MIB_EINSTIEG_ab_Gen3 SG_ 967 WIV_Anzeige_aktiv 1000;
BA_REL_ "GenSigTimeoutTime" BU_SG_REL_ ZR_MIB_EINSTIEG_ab_Gen3 SG_ 967 WIV_Oelmin_Warn 1000;
BA_REL_ "GenSigTimeoutTime" BU_SG_REL_ ZR_MIB_EINSTIEG_ab_Gen3 SG_ 967 WIV_Sensorfehler 1000;
BA_REL_ "GenSigTimeoutTime" BU_SG_REL_ ZR_MIB_EINSTIEG_ab_Gen3 SG_ 967 WIV_Schieflage 1000;
BA_REL_ "GenSigTimeoutTime" BU_SG_REL_ ZR_MIB_EINSTIEG_ab_Gen3 SG_ 967 WIV_Oelstand 1000;
BA_REL_ "GenSigTimeoutTime" BU_SG_REL_ ZR_MIB_EINSTIEG_ab_Gen3 SG_ 967 OLEV_Systemstoerung 1000;
BA_REL_ "GenSigTimeoutTime" BU_SG_REL_ ZR_MIB_EINSTIEG_ab_Gen3 SG_ 967 WIV_Oelsystem_aktiv 1000;
BA_REL_ "GenSigTimeoutTime" BU_SG_REL_ ZR_MIB_EINSTIEG_ab_Gen3 SG_ 967 WIV_nicht_betriebswarm 1000;
BA_REL_ "GenSigTimeoutTime" BU_SG_REL_ ZR_MIB_EINSTIEG_ab_Gen3 SG_ 967 WIV_Ueberfuell_Warn 1000;
BA_REL_ "GenSigTimeoutTime" BU_SG_REL_ ZR_MIB_EINSTIEG_ab_Gen3 SG_ 967 WIV_laufender_Motor 1000;
BA_REL_ "GenSigTimeoutTime" BU_SG_REL_ ZR_MIB_EINSTIEG_ab_Gen3 SG_ 967 OLEV_Oelstand_nicht_vorhanden 1000;
BA_REL_ "GenSigTimeoutTime" BU_SG_REL_ ZR_MIB_EINSTIEG_ab_Gen3 SG_ 967 WIV_Oelmenge 1000;
BA_REL_ "GenSigTimeoutTime" BU_SG_REL_ ZR_MIB_EINSTIEG_ab_Gen3 SG_ 967 WIV_Oelstand_nicht_vorhanden 1000;
BA_REL_ "GenSigTimeoutTime" BU_SG_REL_ ZR_MIB_EINSTIEG_ab_Gen3 SG_ 967 WIV_Unterfuell_Warn 1000;
BA_REL_ "GenSigTimeoutTime" BU_SG_REL_ ZR_MIB_EINSTIEG_ab_Gen3 SG_ 327 MO_Anzeige_Drehmoment 500;
BA_REL_ "GenSigTimeoutTime" BU_SG_REL_ ZR_MIB_EINSTIEG_ab_Gen3 SG_ 327 MO_Anzeige_Leistung 500;
BA_REL_ "GenSigTimeoutTime" BU_SG_REL_ ZR_MIB_EINSTIEG_ab_Gen3 SG_ 1601 MO_Faktor_Momente_02 5000;
BA_REL_ "GenSigTimeoutTime" BU_SG_REL_ ZR_MIB_EINSTIEG_ab_Gen3 SG_ 1601 MO_Kraftstoffart 5000;
BA_REL_ "GenSigTimeoutTime" BU_SG_REL_ ZR_MIB_EINSTIEG_ab_Gen3 SG_ 1601 MO_Hubraum 5000;
BA_REL_ "GenSigTimeoutTime" BU_SG_REL_ ZR_MIB_EINSTIEG_ab_Gen3 SG_ 1601 MO_Ansaugsystem 5000;
BA_REL_ "GenSigTimeoutTime" BU_SG_REL_ ZR_MIB_EINSTIEG_ab_Gen3 SG_ 1601 MO_Leistung 5000;
BA_REL_ "GenSigTimeoutTime" BU_SG_REL_ ZR_MIB_EINSTIEG_ab_Gen3 SG_ 391 MO_Waehlpos 1000;
BA_REL_ "GenSigTimeoutTime" BU_SG_REL_ ZR_MIB_EINSTIEG_ab_Gen3 SG_ 2600468788 NM_BedienDisp_m_NM_State 2000;
BA_REL_ "GenSigTimeoutTime" BU_SG_REL_ ZR_MIB_EINSTIEG_ab_Gen3 SG_ 2600468642 NM_BedienDisp_vm_NM_State 2000;
BA_REL_ "GenSigTimeoutTime" BU_SG_REL_ ZR_MIB_EINSTIEG_ab_Gen3 SG_ 2600468583 NM_eCall_NM_State 2000;
BA_REL_ "GenSigTimeoutTime" BU_SG_REL_ ZR_MIB_OPTION_ab_Gen3 SG_ 263 MO_rel_Ladedruck 500;
BA_REL_ "GenSigTimeoutTime" BU_SG_REL_ ZR_MIB_OPTION_ab_Gen3 SG_ 263 MO_Istgang 500;
BA_REL_ "GenSigTimeoutTime" BU_SG_REL_ ZR_MIB_OPTION_ab_Gen3 SG_ 263 MO_Sollgang 500;
BA_REL_ "GenSigTimeoutTime" BU_SG_REL_ ZR_MIB_OPTION_ab_Gen3 SG_ 263 MO_Anzeigedrehz 500;
BA_REL_ "GenSigTimeoutTime" BU_SG_REL_ ZR_MIB_OPTION_ab_Gen3 SG_ 263 MO_Schaltempf_verfbar 500;
BA_REL_ "GenSigTimeoutTime" BU_SG_REL_ ZR_MIB_OPTION_ab_Gen3 SG_ 263 MO_Ladedruck 500;
BA_REL_ "GenSigTimeoutTime" BU_SG_REL_ ZR_MIB_OPTION_ab_Gen3 SG_ 1600 MO_QBit_Oel_Temp 5000;
BA_REL_ "GenSigTimeoutTime" BU_SG_REL_ ZR_MIB_OPTION_ab_Gen3 SG_ 1600 MO_QBit_Kuehlmittel_Temp 5000;
BA_REL_ "GenSigTimeoutTime" BU_SG_REL_ ZR_MIB_OPTION_ab_Gen3 SG_ 1600 MO_Oel_Temp 5000;
BA_REL_ "GenSigTimeoutTime" BU_SG_REL_ ZR_MIB_OPTION_ab_Gen3 SG_ 1600 MO_Kuehlmittel_Temp 5000;
BA_REL_ "GenSigTimeoutTime" BU_SG_REL_ ZR_MIB_OPTION_ab_Gen3 SG_ 1607 MO_ITM_Kuehlmittel_Temp 5000;
BA_REL_ "GenSigTimeoutTime" BU_SG_REL_ ZR_MIB_OPTION_ab_Gen3 SG_ 167 MO_Mom_Ist_Summe 500;
BA_REL_ "GenSigTimeoutTime" BU_SG_REL_ ZR_MIB_OPTION_ab_Gen3 SG_ 958 MO_StartStopp_Wiederstart 1000;
BA_REL_ "GenSigTimeoutTime" BU_SG_REL_ ZR_MIB_OPTION_ab_Gen3 SG_ 958 MO_StartStopp_Motorstopp 1000;
BA_REL_ "GenSigTimeoutTime" BU_SG_REL_ ZR_MIB_OPTION_ab_Gen3 SG_ 958 MO_Kl_75 1000;
BA_REL_ "GenSigTimeoutTime" BU_SG_REL_ ZR_MIB_OPTION_ab_Gen3 SG_ 958 MO_Kl_50 1000;
BA_REL_ "GenSigTimeoutTime" BU_SG_REL_ ZR_MIB_OPTION_ab_Gen3 SG_ 958 MO_Gangposition 1000;
BA_REL_ "GenSigTimeoutTime" BU_SG_REL_ ZR_MIB_OPTION_ab_Gen3 SG_ 958 MO_Fahrer_bremst 1000;
BA_REL_ "GenSigTimeoutTime" BU_SG_REL_ ZR_MIB_OPTION_ab_Gen3 SG_ 958 MO_QBit_Fahrer_bremst 1000;
BA_REL_ "GenSigTimeoutTime" BU_SG_REL_ ZR_MIB_OPTION_ab_Gen3 SG_ 958 MO_Kuppl_schalter 1000;
BA_REL_ "GenSigTimeoutTime" BU_SG_REL_ ZR_MIB_OPTION_ab_Gen3 SG_ 958 MO_Kickdown 1000;
BA_REL_ "GenSigTimeoutTime" BU_SG_REL_ ZR_MIB_OPTION_ab_Gen3 SG_ 1648 MO_max_Ladedruck 5000;
BA_REL_ "GenSigTimeoutTime" BU_SG_REL_ ZR_MIB_OPTION_ab_Gen3 SG_ 289 MO_Fahrpedalrohwert_01 500;
BA_REL_ "GenSigTimeoutTime" BU_SG_REL_ ZR_MIB_OPTION_ab_Gen3 SG_ 1391 MO_Anzeige_Drehmoment_Max 5000;
BA_REL_ "GenSigTimeoutTime" BU_SG_REL_ ZR_MIB_OPTION_ab_Gen3 SG_ 967 WIV_Anzeige_aktiv 1000;
BA_REL_ "GenSigTimeoutTime" BU_SG_REL_ ZR_MIB_OPTION_ab_Gen3 SG_ 967 WIV_Oelmin_Warn 1000;
BA_REL_ "GenSigTimeoutTime" BU_SG_REL_ ZR_MIB_OPTION_ab_Gen3 SG_ 967 WIV_Sensorfehler 1000;
BA_REL_ "GenSigTimeoutTime" BU_SG_REL_ ZR_MIB_OPTION_ab_Gen3 SG_ 967 WIV_Schieflage 1000;
BA_REL_ "GenSigTimeoutTime" BU_SG_REL_ ZR_MIB_OPTION_ab_Gen3 SG_ 967 WIV_Oelstand 1000;
BA_REL_ "GenSigTimeoutTime" BU_SG_REL_ ZR_MIB_OPTION_ab_Gen3 SG_ 967 OLEV_Systemstoerung 1000;
BA_REL_ "GenSigTimeoutTime" BU_SG_REL_ ZR_MIB_OPTION_ab_Gen3 SG_ 967 WIV_Oelsystem_aktiv 1000;
BA_REL_ "GenSigTimeoutTime" BU_SG_REL_ ZR_MIB_OPTION_ab_Gen3 SG_ 967 WIV_nicht_betriebswarm 1000;
BA_REL_ "GenSigTimeoutTime" BU_SG_REL_ ZR_MIB_OPTION_ab_Gen3 SG_ 967 WIV_Ueberfuell_Warn 1000;
BA_REL_ "GenSigTimeoutTime" BU_SG_REL_ ZR_MIB_OPTION_ab_Gen3 SG_ 967 WIV_laufender_Motor 1000;
BA_REL_ "GenSigTimeoutTime" BU_SG_REL_ ZR_MIB_OPTION_ab_Gen3 SG_ 967 OLEV_Oelstand_nicht_vorhanden 1000;
BA_REL_ "GenSigTimeoutTime" BU_SG_REL_ ZR_MIB_OPTION_ab_Gen3 SG_ 967 WIV_Oelmenge 1000;
BA_REL_ "GenSigTimeoutTime" BU_SG_REL_ ZR_MIB_OPTION_ab_Gen3 SG_ 967 WIV_Oelstand_nicht_vorhanden 1000;
BA_REL_ "GenSigTimeoutTime" BU_SG_REL_ ZR_MIB_OPTION_ab_Gen3 SG_ 967 WIV_Unterfuell_Warn 1000;
BA_REL_ "GenSigTimeoutTime" BU_SG_REL_ ZR_MIB_OPTION_ab_Gen3 SG_ 327 MO_Anzeige_Drehmoment 500;
BA_REL_ "GenSigTimeoutTime" BU_SG_REL_ ZR_MIB_OPTION_ab_Gen3 SG_ 327 MO_Anzeige_Leistung 500;
BA_REL_ "GenSigTimeoutTime" BU_SG_REL_ ZR_MIB_OPTION_ab_Gen3 SG_ 1601 MO_Faktor_Momente_02 5000;
BA_REL_ "GenSigTimeoutTime" BU_SG_REL_ ZR_MIB_OPTION_ab_Gen3 SG_ 1601 MO_Hubraum 5000;
BA_REL_ "GenSigTimeoutTime" BU_SG_REL_ ZR_MIB_OPTION_ab_Gen3 SG_ 1601 MO_Ansaugsystem 5000;
BA_REL_ "GenSigTimeoutTime" BU_SG_REL_ ZR_MIB_OPTION_ab_Gen3 SG_ 1601 MO_Leistung 5000;
BA_REL_ "GenSigTimeoutTime" BU_SG_REL_ ZR_MIB_OPTION_ab_Gen3 SG_ 391 MO_Waehlpos 1000;
BA_REL_ "GenSigTimeoutTime" BU_SG_REL_ ZR_MIB_OPTION_ab_Gen3 SG_ 2589284113 SOK_Motor_VTD_01_Signatur 5000;
BA_REL_ "GenSigTimeoutTime" BU_SG_REL_ ZR_MIB_OPTION_ab_Gen3 SG_ 2589284112 MO_VTD_TD_L 5000;
BA_REL_ "GenSigTimeoutTime" BU_SG_REL_ ZR_MIB_OPTION_ab_Gen3 SG_ 2589284112 MO_VTD_CDEODT_L 5000;
BA_REL_ "GenSigTimeoutTime" BU_SG_REL_ ZR_MIB_OPTION_ab_Gen3 SG_ 2589284115 SOK_Motor_VTD_02_Signatur 5000;
BA_REL_ "GenSigTimeoutTime" BU_SG_REL_ ZR_MIB_OPTION_ab_Gen3 SG_ 2589284114 MO_VTD_CDFC_L 5000;
BA_REL_ "GenSigTimeoutTime" BU_SG_REL_ ZR_MIB_OPTION_ab_Gen3 SG_ 2589284114 MO_VTD_CDERDT_L 5000;
BA_REL_ "GenSigTimeoutTime" BU_SG_REL_ ZR_MIB_OPTION_ab_Gen3 SG_ 2589284117 SOK_Motor_VTD_03_Signatur 5000;
BA_REL_ "GenSigTimeoutTime" BU_SG_REL_ ZR_MIB_OPTION_ab_Gen3 SG_ 2589284116 MO_VTD_CIDT_L 5000;
BA_REL_ "GenSigTimeoutTime" BU_SG_REL_ ZR_MIB_OPTION_ab_Gen3 SG_ 2589284116 MO_VTD_GE_L 5000;
BA_REL_ "GenSigTimeoutTime" BU_SG_REL_ ZR_MIB_OPTION_ab_Gen3 SG_ 2589284119 SOK_Motor_VTD_04_Signatur 5000;
BA_REL_ "GenSigTimeoutTime" BU_SG_REL_ ZR_MIB_OPTION_ab_Gen3 SG_ 2589284118 MO_VTD_CIFC_L 5000;
BA_REL_ "GenSigTimeoutTime" BU_SG_REL_ ZR_MIB_OPTION_ab_Gen3 SG_ 2589284118 MO_VTD_FC_L 5000;
BA_REL_ "GenSigTimeoutTime" BU_SG_REL_ ZR_MIB_OPTION_ab_Gen3 SG_ 2600468788 NM_BedienDisp_m_NM_State 2000;
BA_REL_ "GenSigTimeoutTime" BU_SG_REL_ ZR_MIB_OPTION_ab_Gen3 SG_ 2600468642 NM_BedienDisp_vm_NM_State 2000;
BA_REL_ "GenSigTimeoutTime" BU_SG_REL_ ZR_MIB_OPTION_ab_Gen3 SG_ 2600468583 NM_eCall_NM_State 2000;
BA_REL_ "GenSigTimeoutTime" BU_SG_REL_ ZR_MIB_TOP_ab_Gen3 SG_ 263 MO_rel_Ladedruck 500;
BA_REL_ "GenSigTimeoutTime" BU_SG_REL_ ZR_MIB_TOP_ab_Gen3 SG_ 263 MO_Istgang 500;
BA_REL_ "GenSigTimeoutTime" BU_SG_REL_ ZR_MIB_TOP_ab_Gen3 SG_ 263 MO_Sollgang 500;
BA_REL_ "GenSigTimeoutTime" BU_SG_REL_ ZR_MIB_TOP_ab_Gen3 SG_ 263 MO_Anzeigedrehz 500;
BA_REL_ "GenSigTimeoutTime" BU_SG_REL_ ZR_MIB_TOP_ab_Gen3 SG_ 263 MO_Schaltempf_verfbar 500;
BA_REL_ "GenSigTimeoutTime" BU_SG_REL_ ZR_MIB_TOP_ab_Gen3 SG_ 263 MO_Ladedruck 500;
BA_REL_ "GenSigTimeoutTime" BU_SG_REL_ ZR_MIB_TOP_ab_Gen3 SG_ 167 MO_Mom_Ist_Summe 500;
BA_REL_ "GenSigTimeoutTime" BU_SG_REL_ ZR_MIB_TOP_ab_Gen3 SG_ 958 MO_StartStopp_Wiederstart 1000;
BA_REL_ "GenSigTimeoutTime" BU_SG_REL_ ZR_MIB_TOP_ab_Gen3 SG_ 958 MO_StartStopp_Motorstopp 1000;
BA_REL_ "GenSigTimeoutTime" BU_SG_REL_ ZR_MIB_TOP_ab_Gen3 SG_ 958 MO_Kl_75 1000;
BA_REL_ "GenSigTimeoutTime" BU_SG_REL_ ZR_MIB_TOP_ab_Gen3 SG_ 958 MO_Kl_50 1000;
BA_REL_ "GenSigTimeoutTime" BU_SG_REL_ ZR_MIB_TOP_ab_Gen3 SG_ 958 MO_Fahrer_bremst 1000;
BA_REL_ "GenSigTimeoutTime" BU_SG_REL_ ZR_MIB_TOP_ab_Gen3 SG_ 958 MO_QBit_Fahrer_bremst 1000;
BA_REL_ "GenSigTimeoutTime" BU_SG_REL_ ZR_MIB_TOP_ab_Gen3 SG_ 958 MO_Kuppl_schalter 1000;
BA_REL_ "GenSigTimeoutTime" BU_SG_REL_ ZR_MIB_TOP_ab_Gen3 SG_ 958 MO_Kickdown 1000;
BA_REL_ "GenSigTimeoutTime" BU_SG_REL_ ZR_MIB_TOP_ab_Gen3 SG_ 1631 TSK_QBit_Steigung 5000;
BA_REL_ "GenSigTimeoutTime" BU_SG_REL_ ZR_MIB_TOP_ab_Gen3 SG_ 1648 MO_max_Ladedruck 5000;
BA_REL_ "GenSigTimeoutTime" BU_SG_REL_ ZR_MIB_TOP_ab_Gen3 SG_ 289 MO_Fahrpedalrohwert_01 500;
BA_REL_ "GenSigTimeoutTime" BU_SG_REL_ ZR_MIB_TOP_ab_Gen3 SG_ 1391 MO_Anzeige_Leistung_Max 5000;
BA_REL_ "GenSigTimeoutTime" BU_SG_REL_ ZR_MIB_TOP_ab_Gen3 SG_ 1391 MO_Anzeige_Drehmoment_Max 5000;
BA_REL_ "GenSigTimeoutTime" BU_SG_REL_ ZR_MIB_TOP_ab_Gen3 SG_ 967 WIV_Anzeige_aktiv 1000;
BA_REL_ "GenSigTimeoutTime" BU_SG_REL_ ZR_MIB_TOP_ab_Gen3 SG_ 967 WIV_Oelmin_Warn 1000;
BA_REL_ "GenSigTimeoutTime" BU_SG_REL_ ZR_MIB_TOP_ab_Gen3 SG_ 967 WIV_Sensorfehler 1000;
BA_REL_ "GenSigTimeoutTime" BU_SG_REL_ ZR_MIB_TOP_ab_Gen3 SG_ 967 WIV_Schieflage 1000;
BA_REL_ "GenSigTimeoutTime" BU_SG_REL_ ZR_MIB_TOP_ab_Gen3 SG_ 967 WIV_Oelstand 1000;
BA_REL_ "GenSigTimeoutTime" BU_SG_REL_ ZR_MIB_TOP_ab_Gen3 SG_ 967 OLEV_Systemstoerung 1000;
BA_REL_ "GenSigTimeoutTime" BU_SG_REL_ ZR_MIB_TOP_ab_Gen3 SG_ 967 WIV_Oelsystem_aktiv 1000;
BA_REL_ "GenSigTimeoutTime" BU_SG_REL_ ZR_MIB_TOP_ab_Gen3 SG_ 967 WIV_nicht_betriebswarm 1000;
BA_REL_ "GenSigTimeoutTime" BU_SG_REL_ ZR_MIB_TOP_ab_Gen3 SG_ 967 WIV_Ueberfuell_Warn 1000;
BA_REL_ "GenSigTimeoutTime" BU_SG_REL_ ZR_MIB_TOP_ab_Gen3 SG_ 967 WIV_laufender_Motor 1000;
BA_REL_ "GenSigTimeoutTime" BU_SG_REL_ ZR_MIB_TOP_ab_Gen3 SG_ 967 OLEV_Oelstand_nicht_vorhanden 1000;
BA_REL_ "GenSigTimeoutTime" BU_SG_REL_ ZR_MIB_TOP_ab_Gen3 SG_ 967 WIV_Oelmenge 1000;
BA_REL_ "GenSigTimeoutTime" BU_SG_REL_ ZR_MIB_TOP_ab_Gen3 SG_ 967 MO_Heissleuchte 1000;
BA_REL_ "GenSigTimeoutTime" BU_SG_REL_ ZR_MIB_TOP_ab_Gen3 SG_ 967 WIV_Oelstand_nicht_vorhanden 1000;
BA_REL_ "GenSigTimeoutTime" BU_SG_REL_ ZR_MIB_TOP_ab_Gen3 SG_ 967 WIV_Unterfuell_Warn 1000;
BA_REL_ "GenSigTimeoutTime" BU_SG_REL_ ZR_MIB_TOP_ab_Gen3 SG_ 327 MO_Anzeige_Drehmoment 500;
BA_REL_ "GenSigTimeoutTime" BU_SG_REL_ ZR_MIB_TOP_ab_Gen3 SG_ 327 MO_Anzeige_Leistung 500;
BA_REL_ "GenSigTimeoutTime" BU_SG_REL_ ZR_MIB_TOP_ab_Gen3 SG_ 1601 MO_Faktor_Momente_02 5000;
BA_REL_ "GenSigTimeoutTime" BU_SG_REL_ ZR_MIB_TOP_ab_Gen3 SG_ 1601 MO_Kraftstoffart 5000;
BA_REL_ "GenSigTimeoutTime" BU_SG_REL_ ZR_MIB_TOP_ab_Gen3 SG_ 1601 MO_Hubraum 5000;
BA_REL_ "GenSigTimeoutTime" BU_SG_REL_ ZR_MIB_TOP_ab_Gen3 SG_ 1601 MO_Ansaugsystem 5000;
BA_REL_ "GenSigTimeoutTime" BU_SG_REL_ ZR_MIB_TOP_ab_Gen3 SG_ 1601 MO_Leistung 5000;
BA_REL_ "GenSigTimeoutTime" BU_SG_REL_ ZR_MIB_TOP_ab_Gen3 SG_ 813 MO_CNG_Tankstopp 500;
BA_REL_ "GenSigTimeoutTime" BU_SG_REL_ ZR_MIB_TOP_ab_Gen3 SG_ 2589284113 SOK_Motor_VTD_01_Signatur 5000;
BA_REL_ "GenSigTimeoutTime" BU_SG_REL_ ZR_MIB_TOP_ab_Gen3 SG_ 2589284112 MO_VTD_TD_L 5000;
BA_REL_ "GenSigTimeoutTime" BU_SG_REL_ ZR_MIB_TOP_ab_Gen3 SG_ 2589284112 MO_VTD_CDEODT_L 5000;
BA_REL_ "GenSigTimeoutTime" BU_SG_REL_ ZR_MIB_TOP_ab_Gen3 SG_ 2589284115 SOK_Motor_VTD_02_Signatur 5000;
BA_REL_ "GenSigTimeoutTime" BU_SG_REL_ ZR_MIB_TOP_ab_Gen3 SG_ 2589284114 MO_VTD_CDFC_L 5000;
BA_REL_ "GenSigTimeoutTime" BU_SG_REL_ ZR_MIB_TOP_ab_Gen3 SG_ 2589284114 MO_VTD_CDERDT_L 5000;
BA_REL_ "GenSigTimeoutTime" BU_SG_REL_ ZR_MIB_TOP_ab_Gen3 SG_ 2589284117 SOK_Motor_VTD_03_Signatur 5000;
BA_REL_ "GenSigTimeoutTime" BU_SG_REL_ ZR_MIB_TOP_ab_Gen3 SG_ 2589284116 MO_VTD_CIDT_L 5000;
BA_REL_ "GenSigTimeoutTime" BU_SG_REL_ ZR_MIB_TOP_ab_Gen3 SG_ 2589284116 MO_VTD_GE_L 5000;
BA_REL_ "GenSigTimeoutTime" BU_SG_REL_ ZR_MIB_TOP_ab_Gen3 SG_ 2589284119 SOK_Motor_VTD_04_Signatur 5000;
BA_REL_ "GenSigTimeoutTime" BU_SG_REL_ ZR_MIB_TOP_ab_Gen3 SG_ 2589284118 MO_VTD_CIFC_L 5000;
BA_REL_ "GenSigTimeoutTime" BU_SG_REL_ ZR_MIB_TOP_ab_Gen3 SG_ 2589284118 MO_VTD_FC_L 5000;
BA_REL_ "GenSigTimeoutTime" BU_SG_REL_ ZR_MIB_TOP_ab_Gen3 SG_ 2600468788 NM_BedienDisp_m_NM_State 2000;
BA_REL_ "GenSigTimeoutTime" BU_SG_REL_ ZR_MIB_TOP_ab_Gen3 SG_ 2600468642 NM_BedienDisp_vm_NM_State 2000;
BA_REL_ "GenSigTimeoutTime" BU_SG_REL_ ZR_MIB_TOP_ab_Gen3 SG_ 2600468583 NM_eCall_NM_State 2000;
VAL_ 263 MO_rel_Ladedruck 255 "Fehler" ;
VAL_ 263 MO_Istgang 0 "kein_Gang_eingelegt" 1 "Gang_1" 2 "Gang_2" 3 "Gang_3" 4 "Gang_4" 5 "Gang_5" 6 "Gang_6" 7 "Gang_7" 8 "Gang_8" 9 "Gang_9" ;
VAL_ 263 MO_Sollgang 0 "keine_Empfehlung" 1 "Gang_1" 2 "Gang_2" 3 "Gang_3" 4 "Gang_4" 5 "Gang_5" 6 "Gang_6" 7 "Gang_7" 8 "Gang_8" 9 "Gang_9" 15 "Neutralgang" ;
VAL_ 263 MO_Oeldruck 254 "Init" 255 "Fehler" ;
VAL_ 263 MO_Anzeigedrehz 4095 "reserviert" ;
VAL_ 263 MO_Effizienzmodus 0 "nicht_im_Effizienz_Modus" 1 "Effizienz_Modus" ;
VAL_ 263 MO_Fehler_Oeldrucksensor 0 "kein_Fehler" 1 "Fehler" ;
VAL_ 263 MO_Schaltempf_verfbar 0 "nicht_verfuegbar" 1 "verfuegbar" ;
VAL_ 263 MO_Ladedruck 511 "Fehler" ;
VAL_ 263 MO_KVS_Ueberlauf 0 "kein Ueberlauf" 1 "Kraftstoffverbrauchsignale mindestens 1x übergelaufen" ;
VAL_ 1600 MO_QBit_Ansaugluft_Temp 0 "gueltiger_Wert" 1 "Ersatz_Init_oder_Fehlerwert" ;
VAL_ 1600 MO_QBit_Oel_Temp 0 "gueltiger_Wert" 1 "Ersatz_Init_oder_Fehlerwert" ;
VAL_ 1600 MO_QBit_Kuehlmittel_Temp 0 "gueltiger_Wert" 1 "Ersatz_Init_oder_Fehlerwert" ;
VAL_ 1600 MO_KL15_Abschaltempfehlung 0 "Keine Empfehlung" 1 "Abschaltempfehlung" ;
VAL_ 1600 MO_HYB_Fehler_HV_Netz 0 "i_O" 1 "kein_generatorischer_Betrieb_moeglich" ;
VAL_ 1600 MO_aktives_Getriebeheizen 0 "kein_Ventil_ansteuern" 1 "Ventil_muss_angesteuert_werden" ;
VAL_ 1600 MO_Absperrventil_oeffnen 0 "nicht_verfuegbar" 1 "Ansteuerung_Ventil_zulaessig" 2 "Ventil_oeffnen_oder_geoeffnet" 3 "Ventil_schliessen_oder_geschlossen" ;
VAL_ 1600 MO_Ansaugluft_Temp 254 "Init" 255 "Fehler" ;
VAL_ 1600 MO_Oel_Temp 253 "nicht_verbaut" 254 "Init" 255 "Fehler" ;
VAL_ 1600 MO_Kuehlmittel_Temp 254 "Init" 255 "Fehler" ;
VAL_ 1600 MO_Hoeheninfo 255 "Fehler" ;
VAL_ 1600 MO_Kennfeldk 0 "keine Kennfeldkühlung vorhanden" 1 "Kennfeldkühlung vorhanden" ;
VAL_ 1600 MO_Versionsinfo_02 0 "zum_Projektbeginn_aufgeraeumter_CAN" 1 "Motor_03_mit_10ms" 16 "MQB_mit_neuer_Momentenschnittstelle" ;
VAL_ 1600 MO_QBit_Hoeheninfo 0 "gueltiger_Wert" 1 "Ersatz_Init_oder_Fehlerwert" ;
VAL_ 1600 MO_Getriebe_kuehlen 0 "nicht_kuehlen" 1 "kuehlen" ;
VAL_ 1600 MO_Heizungspumpenansteuerung 13 "Fehler" 14 "Init" 15 "nicht_verbaut" ;
VAL_ 1600 MO_SpannungsAnf 0 "keine_Anforderung" 1 "Anforderung" ;
VAL_ 1607 MO_ITM_Kuehlmittel_Temp 0 "nicht_verbaut" 1 "Init" 2 "Fehler" ;
VAL_ 1607 MO_E85_Sensor 13 "nicht_verbaut" 14 "Init" 15 "Fehler" ;
VAL_ 1607 SCR_Anz_Motorstarts 0 "Anzahl_moeglicher_Restarts" 1 "Anzahl_moeglicher_Restarts" 2 "Anzahl_moeglicher_Restarts" 3 "Anzahl_moeglicher_Restarts" 4 "Anzahl_moeglicher_Restarts" 5 "Anzahl_moeglicher_Restarts" 6 "Anzahl_moeglicher_Restarts" 7 "Anzahl_moeglicher_Restarts" 8 "Anzahl_moeglicher_Restarts" 9 "Anzahl_moeglicher_Restarts" 10 "Anzahl_moeglicher_Restarts" 11 "Anzahl_moeglicher_Restarts" 12 "Anzahl_moeglicher_Restarts" 13 "Anzahl_moeglicher_Restarts" 14 "Fahrbarkeitseinschraenkung" 15 "keine_Einschraenkung" ;
VAL_ 1607 SCR_Reichweite 32767 "keine_Anzeige" ;
VAL_ 1607 MO_Ethanol_Spuelhinweis 0 "Kein_Hinweis" 1 "Spuelhinweis_aktiv" ;
VAL_ 1607 SCR_Warnstufe_1 0 "nicht_aktiv" 1 "Warnstufe_1_aktiv" ;
VAL_ 1607 SCR_Warnstufe_2 0 "nicht_aktiv" 1 "Warnstufe_2_aktiv" ;
VAL_ 1607 SCR_Text 0 "kein_Text" 1 "Warntext_1" 2 "Warntext_2" 3 "Hinweis_Fuellstand" 4 "Reserve" 5 "SysFehler_1" 6 "SysFehler_2" 7 "Hinweis_Systemfehler" ;
VAL_ 1607 SCR_Akustik 0 "keine_Akustik" 1 "Akustik_1" 2 "Akustik_2" 3 "Akustik_bei_Hinweis" ;
VAL_ 1607 SCR_verbaut 0 "kein_SCR" 1 "SCR_verbaut" ;
VAL_ 1607 MO_Kraftstofffilter_Wasser 0 "keine_Anzeige" 1 "Abscheidevolumen_erschoepft" ;
VAL_ 1607 SCR_Systemfehler 0 "Warnung_nicht_aktiv" 1 "Warnung_aktiv" ;
VAL_ 1607 SCR_Inducement_Strategie 0 "Restart_Strategie" 1 "Reduced_Drivability_Strategie" ;
VAL_ 1607 MO_CO2_Faktor 0 "nicht_verbaut" 4095 "Fehler" ;
VAL_ 1607 MO_MKB_MUX 0 "MKB_01" 1 "MKB_02" 2 "MKB_03" 3 "MKB_04" ;
VAL_ 1607 MO_MKB_01 0 "Minus" 1 "A" 2 "B" 3 "C" 4 "D" 5 "E" 6 "F" 7 "G" 8 "H" 9 "I" 10 "J" 11 "K" 12 "L" 13 "M" 14 "N" 15 "O" 16 "P" 17 "Q" 18 "R" 19 "S" 20 "T" 21 "U" 22 "V" 23 "W" 24 "X" 25 "Y" 26 "Z" 27 "Leerzeichen" 28 "Leerzeichen" 29 "Leerzeichen" 30 "Leerzeichen" 31 "Unterstrich" ;
VAL_ 1607 MO_MKB_02 0 "Minus" 1 "A" 2 "B" 3 "C" 4 "D" 5 "E" 6 "F" 7 "G" 8 "H" 9 "I" 10 "J" 11 "K" 12 "L" 13 "M" 14 "N" 15 "O" 16 "P" 17 "Q" 18 "R" 19 "S" 20 "T" 21 "U" 22 "V" 23 "W" 24 "X" 25 "Y" 26 "Z" 27 "Leerzeichen" 28 "Leerzeichen" 29 "Leerzeichen" 30 "Leerzeichen" 31 "Unterstrich" ;
VAL_ 1607 MO_MKB_03 0 "Minus" 1 "A" 2 "B" 3 "C" 4 "D" 5 "E" 6 "F" 7 "G" 8 "H" 9 "I" 10 "J" 11 "K" 12 "L" 13 "M" 14 "N" 15 "O" 16 "P" 17 "Q" 18 "R" 19 "S" 20 "T" 21 "U" 22 "V" 23 "W" 24 "X" 25 "Y" 26 "Z" 27 "Leerzeichen" 28 "Leerzeichen" 29 "Leerzeichen" 30 "Leerzeichen" 31 "Unterstrich" ;
VAL_ 1607 MO_MKB_04 0 "Minus" 1 "A" 2 "B" 3 "C" 4 "D" 5 "E" 6 "F" 7 "G" 8 "H" 9 "I" 10 "J" 11 "K" 12 "L" 13 "M" 14 "N" 15 "O" 16 "P" 17 "Q" 18 "R" 19 "S" 20 "T" 21 "U" 22 "V" 23 "W" 24 "X" 25 "Y" 26 "Z" 27 "Leerzeichen" 28 "Leerzeichen" 29 "Leerzeichen" 30 "Leerzeichen" 31 "Unterstrich" ;
VAL_ 167 MO_Mom_Soll_Roh 1022 "Init" ;
VAL_ 167 MO_Mom_Ist_Summe 1022 "Init" ;
VAL_ 167 MO_Mom_Traegheit_Summe 1022 "Init" ;
VAL_ 167 MO_Mom_Soll_gefiltert 1022 "Init" ;
VAL_ 167 MO_Mom_Schub 510 "Init" ;
VAL_ 167 MO_Status_Normalbetrieb_01 0 "kein_Normalbetrieb" 1 "Normalbetrieb_erreicht" ;
VAL_ 167 MO_erste_Ungenauschwelle 0 "genau" 1 "Momente ungenauer >8%" ;
VAL_ 167 MO_QBit_Motormomente 0 "gueltiger_Wert" 1 "Ersatz_Init_oder_Fehlerwert" ;
VAL_ 958 MO_StartStopp_Status 0 "System_in_diesem_KL15_Zyklus_nicht_verfuegbar" 1 "System_aktiv_keine_Freigabe_durch_StartStop_Koordinator" 2 "System_aktiv_alle_Freigaben_liegen_vor" 3 "System_aktiv_mindestens_eine_Freigabe_fehlt" ;
VAL_ 958 MO_StartStopp_Wiederstart 0 "Wiederstart_inaktiv" 1 "Wiederstart_aktiv" ;
VAL_ 958 MO_StartStopp_Motorstopp 0 "Motor_Stop_inaktiv" 1 "Motor_Stop_aktiv" ;
VAL_ 958 MO_Freig_Reku 0 "Rekuperations-Modus aus" 1 "Empfehlung Spannungsanhebung" 2 "Empfehlung Spannungsabsenkung" 3 "Rekuperationsmodus aktiv, Spannungsvariation nicht notwendig" ;
VAL_ 958 MO_Kl_75 0 "Aus" 1 "Ein" ;
VAL_ 958 MO_Kl_50 0 "aus" 1 "KL50_ein_Startausfuehrung_Fahrer" ;
VAL_ 958 MO_Gangposition 0 "Gang_N" 1 "Gang_1" 2 "Gang_2" 3 "Gang_3" 4 "Gang_4" 5 "Gang_5" 6 "Gang_6" 7 "Gang_7" 8 "Gang_8" 9 "Automat_P" 10 "Automat_Vorwaerts_S" 11 "Automat_Vorwaerts_D/E" 12 "Zwischenstellung" 13 "Gang_R" 14 "Istgang_nicht_definiert" 15 "Fehler" ;
VAL_ 958 MO_StartStopp_Fahrerwunsch 0 "Init" 1 "Stoppverbot_durch_Fahrer" 2 "Stoppfreigabe_durch_Fahrer" 3 "Stoppanforderung_durch_Fahrer" ;
VAL_ 958 MO_HYB_Fahrbereitschaft 0 "keine_Fahrbereitschaft" 1 "Fahrbereitschaft" ;
VAL_ 958 MO_Ext_E_Fahrt_aktiv 0 "Rueckmeldung_E_Taster_aus" 1 "Rueckmeldung_E_Taster_ein" ;
VAL_ 958 MO_Fahrer_bremst 0 "kein_Bremsen" 1 "Bremse_betaetigt" ;
VAL_ 958 MO_QBit_Fahrer_bremst 0 "gueltiger_Wert" 1 "Ersatz_Init_oder_Fehlerwert" ;
VAL_ 958 MO_BLS 0 "kein_Bremsen" 1 "Bremse_betaetigt" ;
VAL_ 958 MO_Konsistenz_Bremsped 0 "Bremspedalinformation_plausibel" 1 "Bremspedalinformation_unplausibel" ;
VAL_ 958 MO_Timeout_ESP 0 "Empfang_iO" 1 "Timeout" ;
VAL_ 958 MO_Klima_Eingr 0 "kein Eingriff" 1 "Klimakompressor ausschalten" 2 "Klimakompressor Leistungsreduzierung" 3 "Klimakompressor aufgrund der Heissleuchtenvorwarnung ausschalten" ;
VAL_ 958 MO_Aussp_Anlass 0 "Anlasser_darf_angesteuert_werden" 1 "Anlasser_ausspuren__Ansteuerung_nicht_moeglich" ;
VAL_ 958 MO_Freig_Anlass 0 "Start_nicht_zulaessig" 1 "Startfreigabe" ;
VAL_ 958 MO_Kuppl_schalter 0 "Schalter_sagt_ausgekuppelt" 1 "Schalter_sagt_eingekuppelt" ;
VAL_ 958 MO_Interlock 0 "Interlockschalter_nicht_betaetigt" 1 "Interlockschalter_betaetigt" ;
VAL_ 958 MO_Motor_laeuft 0 "Motor_laeuft_nicht" 1 "Motor_laeuft_autark_und_stabil_und_darf_mechanisch_belastet_werden" ;
VAL_ 958 MO_Kickdown 0 "kein_Kickdown" 1 "Kickdown" ;
VAL_ 958 MO_QBit_KL_75 0 "gueltiger_Wert" 1 "Ersatz_Init_oder_Fehlerwert" ;
VAL_ 958 MO_EKlKomLeiRed 0 "keine_Leistungsbegr" 1 "Leistungsbegr_75" 2 "Leistungsbegr_50" 3 "Leistungsbegr_25" ;
VAL_ 958 MO_Handshake_STH 0 "keine EKP-Ansteuerung durch STH-Anforderung" 1 "EKP-Ansteuerung durch STH-Anforderung" ;
VAL_ 958 MO_BKV_Unterdruckwarnung 0 "Unterdruckhaushalt_iO" 1 "Unterdruckhaushalt_niO" ;
VAL_ 958 MO_Freigabe_Segeln 0 "Segelbetrieb_nicht_freigegeben" 1 "Segelbetrieb_freigegeben" ;
VAL_ 958 MO_PTC_Status 0 "nicht_unterstuetzt" 1 "Stufe_0" 2 "Stufe_1" 3 "Stufe_2" 4 "Stufe_3" 7 "PTC_am_BCM" ;
VAL_ 958 MO_QBit_Gangposition 0 "gueltiger_Wert" 1 "Ersatz_Init_oder_Fehlerwert" ;
VAL_ 958 MO_Signalquelle_Gangposition 0 "Sensorsignal" 1 "Modellsignal" ;
VAL_ 958 MO_Remotestart_Betrieb 0 "MSG_nicht_bereit_fuer_RS_Betrieb" 1 "MSG_bereit_fuer_oder_im_RS_Betrieb" ;
VAL_ 958 MO_Remotestart_moeglich 0 "Remotestart_nicht_moeglich" 1 "Remotestart_moeglich" ;
VAL_ 958 MO_FMAus_aktiv 0 "inaktiv" 1 "Segeln_mit_Motor_aus_aktiv" ;
VAL_ 958 MO_FMAus_Startvariante 0 "kein_Motorstart" 1 "Motorstart_elektrischer_Starter" 2 "GetriebeAnschleppstart" 3 "GetriebeNotAnschleppstart" ;
VAL_ 958 MO_BMS_NV_Anf_stuetzen 0 "nicht_notwendig" 1 "notwendig" ;
VAL_ 958 MO_Zylinderabschaltung 0 "Vollmotorbetrieb_VMB" 1 "Uebergang_HMB_in_VMB" 2 "Uebergang_VMB_in_HMB" 3 "Halbmotorbetrieb_HMB" ;
VAL_ 958 MO_HYB_VM_aktiv 0 "VM_nicht_aktiv" 1 "VM_aktiv" ;
VAL_ 958 MO_StartVorauss_erfuellt 0 "Signal_nicht_bedient" 1 "StartVorauss_nicht_ueberpruefbar" 2 "StartVorauss_nicht_erfuellt" 3 "StartVorauss_erfuellt" ;
VAL_ 1631 TSK_QBit_Steigung 0 "gueltiger_Wert" 1 "Ersatz_Init_oder_Fehlerwert" ;
VAL_ 1631 TSK_QBit_Fahrzeugmasse 0 "gueltiger_Wert" 1 "Ersatz_Init_oder_Fehlerwert" ;
VAL_ 1631 MO_SpannungsAnf_02 0 "keine_Anforderung" 1 "Anforderung_Stufe_1" 2 "Anforderung_Stufe_2" 3 "Anforderung_Stufe_3" ;
VAL_ 1631 MO_DPF_reg 0 "DPF_regeneriert_nicht" 1 "DPF_regeneriert" ;
VAL_ 1631 MO_Heizstrom_EKAT 127 "Fehler" ;
VAL_ 1631 MO_Heizstrom_SCR 63 "Fehler" ;
VAL_ 1631 MO_Anzeige_Kaltleuchte 0 "Lampe_aus" 1 "Lampe_an" ;
VAL_ 1631 MO_P_Generator_ungefiltert_Anf 0 "nicht_angefordert" 1 "angefordert" ;
VAL_ 1631 MO_Energieinhalt_BMS 4094 "Init" 4095 "Fehler" ;
VAL_ 1631 TSK_Fahrzeugmasse_02 255 "Fehler" ;
VAL_ 1631 TSK_Steigung_02 0 "Init_oder_nicht_verbaut" 255 "Fehler" ;
VAL_ 1648 MO_ANC_Kennfeld_Anf 0 "Kennfeld_1" 1 "Uebergang_Kennfeld_2_nach_1" 2 "Uebergang_Kennfeld_1_nach_2" 3 "Kennfeld_2" ;
VAL_ 1648 MO_Bremslicht_Reku 0 "Aus" 1 "Ein" ;
VAL_ 1648 MO_StartStopp_PopUp 0 "Statuswechsel_ohne_Taster (Init)" 1 "StSt_per_Taster_deaktiviert" 2 "StSt_per_Taster_aktiviert" 3 "nicht verwendet" ;
VAL_ 1648 MO1_Sperr_Info_WFS 0 "nicht_gesperrt" 1 "gesperrt" ;
VAL_ 1648 MO1_Freigabe_Info_WFS 0 "ungueltig" 1 "gueltig" ;
VAL_ 1648 MO_EPCL 0 "EPCL_aus_kein_Text" 1 "EPCL_gelb_Stoerung" 2 "EPCL_gelb_Leistungsbeschraenkung" 3 "EPCL_rot_Fzg_sicher_abstellen" ;
VAL_ 1648 MO_Zylabsch_Texte_02 0 "ein_ZAS_generell_keine_ZAS_Anzeigen" 1 "ZAS_im_VMB" 2 "ZAS_im_ASB_1_Zyl_aktiv" 3 "ZAS_im_ASB_2_Zyl_aktiv" 4 "ZAS_im_ASB_3_Zyl_aktiv" 5 "ZAS_im_ASB_4_Zyl_aktiv" 6 "ZAS_im_ASB_5_Zyl_aktiv" 7 "ZAS_im_ASB_6_Zyl_aktiv" 8 "ZAS_im_ASB_8_Zyl_aktiv" 9 "ZAS_im_ASB_12_Zyl_aktiv" 13 "Uebergangsbetrieb" 14 "keine_ZAS_Anzeige_ggf_Stopp_Schub_Betrieb" 15 "ZAS_Stoerungs_Anzeige" ;
VAL_ 1648 MO_Fahrzeugtyp 0 "Verbrenner_Fahrzeug" 1 "Hybrid" 2 "E_Fahrzeug" 3 "E_Fahrzeug_mit_Range_Extender" 4 "Brennstoffzellenfahrzeug" 5 "tbd" 6 "tbd" 7 "tbd" ;
VAL_ 1648 MO_Abstellzeit 254 "Init" 255 "reserviert" ;
VAL_ 1648 MO_Abstellzeit_Status 0 "Abstellzeit_nicht_berechnet" 1 "Abstellzeit_berechnet" 2 "Abstellzeit_Minimalwert" 3 "Abstellzeit_ungueltig" ;
VAL_ 1648 MO1_Freigabe_Verfallsinfo_WFS 0 "verfaellt_nicht" 1 "verfaellt" ;
VAL_ 1648 MO_Hybrid_StartStopp_LED 0 "LED_aus_und_Blinken_aus" 1 "LED_ein_und_Blinken_aus" 2 "LED_ein_und_Blinken_ein_50_percent" 3 "reserviert" ;
VAL_ 1648 MO_Fehler_Zylabsch 0 "kein_Fehler" 1 "Notlauf_Vollmotorbetrieb" 2 "Notlauf_mindestens_einem_abgesch_Zylinder" ;
VAL_ 1648 MO_Anzahl_Abgesch_Zyl 0 "Vollmotorbetrieb" 1 "1_Zylinder_abgeschaltet" 2 "2_Zylinder_abgeschaltet" 3 "3_Zylinder_abgeschaltet" 4 "4_Zylinder_abgeschaltet" 5 "5_Zylinder_abgeschaltet" 6 "6_Zylinder_abgeschaltet" 7 "8_Zylinder_abgeschaltet" ;
VAL_ 1648 MO_Zylabsch_Texte 0 "keine_Texte" 1 "Zylinderabschaltung_deaktivieren" 2 "Zylinderabschaltung_aktivieren" 3 "Zylinderabschaltung_unruhig" ;
VAL_ 1648 MO_Ethanol_BS_Texte 0 "kein_Text" 1 "E85_Warm_Up" 2 "FlexFuel_Warnung_Stufe_3" 3 "Warmfahrempfehlung_MQB__FlexFuel_Warnung_Stufe_1" 4 "FlexFuel_Warnung_Stufe_2" 5 "FlexFuel_Warnung_Stufe_4" 6 "E25_Warm_Up" ;
VAL_ 1648 MO_Drehzahl_Warnung 0 "keinen_Warnhinweis_anzeigen" 1 "Warnhinweis_anzeigen" ;
VAL_ 1648 MO_obere_Drehzahlgrenze 0 "Init" ;
VAL_ 289 MO_Fahrpedalrohwert_01 255 "Fehler" ;
VAL_ 289 MO_QBit_Fahrpedalwerte_01 0 "gueltiger_Wert" 1 "Ersatz_Init_oder_Fehlerwert" ;
VAL_ 289 MO_Fahrpedalgradient 255 "Fehler" ;
VAL_ 289 MO_Sig_Fahrpedalgradient 0 "Fahrpedalgradient positiv" 1 "Fahrpedalgradient negativ" ;
VAL_ 289 MO_rel_Saugrohrdruck 0 "Init_Ueberdruck" 63 "Fehler" ;
VAL_ 289 MO_rel_Saugrohrdruck_gem_err 0 "errechnet" 1 "gemessen" ;
VAL_ 289 MO_Moment_im_Leerlauf 0 "kein_Leergas" 1 "Leergas" ;
VAL_ 289 MO_Schubabschaltung 0 "keine_Schubabschaltung" 1 "Schubabschaltung_aktiv" ;
VAL_ 289 MO_StartStopp_StoppVorbereitung 0 "Motorstopp_nicht_in_Vorbereitung" 1 "Motorstopp_in_Vorbereitung" ;
VAL_ 289 MO_Entkopplung_Sollschlupf 125 "Notoeffnen_Anfahrelement" 126 "Init" ;
VAL_ 289 MO_temporaere_Fahrerabwesenheit 0 "nicht_erkannt" 1 "erkannt" ;
VAL_ 289 TSK_a_Soll_gradientenbegrenzt 127 "Init_oder_nicht_aktiv" ;
VAL_ 1391 MO_Anzeige_Aufheizfortschritt 126 "Init" 127 "Fehler" ;
VAL_ 1391 MO_IstLeistung_EKAT 126 "Init" 127 "Fehler" ;
VAL_ 1391 MO_HYB_Drehzahl_VM 65280 "Fehler" ;
VAL_ 967 MO_Kuehlerluefter_MUX 0 "Kuehlerluefter_1" 1 "Kuehlerluefter_2" ;
VAL_ 967 MO_Kuehlerluefter_1 126 "Init" 127 "Fehler" ;
VAL_ 967 MO_Kuehlerluefter_2 126 "Init" 127 "Fehler" ;
VAL_ 967 MO_EFLEX_Lampe 0 "Lampe_aus" 1 "Lampe_ein" 2 "Lampe_blinkend" 3 "Lampe_blinkend_mit_Akustik" ;
VAL_ 967 MO_KJS_nicht_bereit 0 "kein_Fehler" 1 "Fehler" ;
VAL_ 967 MO_ITM_Warnung_Pumpe 0 "keine_Warnung" 1 "ITM_Warnung" ;
VAL_ 967 WIV_Anzeige_aktiv 0 "Anzeige aus" 1 "WIV Anzeige aktiv" ;
VAL_ 967 WIV_Oelmin_Warn 0 "in_Ordnung" 1 "Warnung" ;
VAL_ 967 WIV_Sensorfehler 0 "in_Ordnung" 1 "Sensor_defekt" ;
VAL_ 967 WIV_Schieflage 0 "Fahrzeug_gerade" 1 "Fahrzeug_in_Schieflage" ;
VAL_ 967 MO_Zustand_HWP 0 "HWP_nicht_schaltbar" 1 "HWP_foerdert_nicht" 2 "HWP_foerdert" 3 "reserviert" ;
VAL_ 967 OLEV_Systemstoerung 0 "Ölsystem i.O." 1 "Systemstörung Ölsystem" ;
VAL_ 967 MO_Oelwarnung_max 0 "keine_Warnung" 1 "Warnfall_aktiv" ;
VAL_ 967 WIV_Oelsystem_aktiv 0 "Anzeige_aus" 1 "Anzeige_aktiv" ;
VAL_ 967 WIV_nicht_betriebswarm 0 "Motor_warm" 1 "Motor_nicht_betriebswarm" ;
VAL_ 967 WIV_Ueberfuell_Warn 0 "in_Ordnung" 1 "Ueberfuellwarnung" ;
VAL_ 967 WIV_laufender_Motor 0 "Messung_moeglich" 1 "Messung_nicht_moeglich" ;
VAL_ 967 MO_E_Warnungen 0 "keine_Anzeige" 1 "Fehler_Elektrosystem_Anhalten" 2 "Fehler_Elektrosystem_Werkstatt" 3 "Elektrosystem_ueberhitzt_Stopp" 4 "Fehler_Hybridsystem_Anhalten" 5 "Fehler_Hybridsystem_Werkstatt" 6 "Fehler_Wasserstoffsystem_Anhalte" 7 "Fehler_Wasserstoffsystem_Werksta" 8 "reserviert_keine_Anzeige" 9 "reserviert_keine_Anzeige" 10 "reserviert_keine_Anzeige" 11 "reserviert_keine_Anzeige" 12 "reserviert_keine_Anzeige" 13 "reserviert_keine_Anzeige" 14 "reserviert_keine_Anzeige" 15 "reserviert_keine_Anzeige" ;
VAL_ 967 MO_Text_Motorstart 0 "keine_Anzeige" 1 "Motor_im_Stoppbetrieb" 2 "StartStopp_sicherheitsbedingt_deaktiviert" 3 "System_fordert_Wiederstart" 4 "Aufforderung_Motorstart" 5 "Motorlauf_noetig" 6 "Motorlaufwarnung" 9 "Unerwuenschter_Motorstillstand" 10 "Motorstart_nicht_moeglich" 11 "Fehler_Kupplungsschalter" 12 "Motor_startet" 13 "Kupplung_betaetigen" 14 "Waehlhebel_in_PN_Position" 15 "Bremse_treten" ;
VAL_ 967 MO_E_Texte 0 "keine_Anzeige" 1 "Batterie_fast_leer" 2 "Ladestecker_nicht_fahrbereit" 3 "VM_Betrieb_erforderlich" 4 "Batterie_laedt_Nicht_ausschalten" 5 "Bitte_Bremse_treten" 6 "manueller_Neustart_erforderlich" 7 "Stopp_Fahrzeug_nicht_abschleppen" 8 "kein_Neustart_Haube_nicht_oeffnen" 9 "Motorstart_im_naechsten_Zyklus" 10 "VM_erforderlich_EVMode_abwaehlen" 11 "laengerer_VMBetrieb_Bordbuch" 12 "Tank_leer_VM_nicht_verfuegbar" 13 "Bitte_warten_Motor_startet" 14 "kein_Start_Batterietemperatur" 15 "Ende_elektrische_Reichweite_erreicht" ;
VAL_ 967 WIV_Oeldyn_avl 0 "Oeldyn_nicht_vorhanden" 1 "Oeldyn_vorhanden" ;
VAL_ 967 OLEV_Oelstand_nicht_vorhanden 0 "Ölstand vorhanden" 1 "Ölstand nicht vorhanden" ;
VAL_ 967 MO_Systemlampe 0 "Lampe aus" 1 "Lampe ein" ;
VAL_ 967 MO_OBD2_Lampe 0 "Lampe aus" 1 "Lampe ein" ;
VAL_ 967 MO_Heissleuchte 0 "Lampe aus" 1 "Lampe ein" ;
VAL_ 967 MO_Partikel_Lampe 0 "Lampe aus" 1 "Lampe ein" ;
VAL_ 967 MO_RedFahrleistung_Lampe 0 "Lampe_aus" 1 "Lampe_ein" ;
VAL_ 967 WIV_Oelstand_nicht_vorhanden 0 "Ölstand vorhanden" 1 "Ölstand nicht vorhanden" ;
VAL_ 967 WIV_nachfuellanzeige_ein 0 "keine_Nachfuellanzeige" 1 "Nachfuellanzeige" ;
VAL_ 967 WIV_Ueberfuell_deaktiv 0 "Ueberfuellwarnung_am_Kombi_aktiv" 1 "Ueberfuellwarnung_am_Kombi_deaktiv" ;
VAL_ 967 WIV_Unterfuell_Warn 0 "in_Ordnung" 1 "Unterfuellwarnung" ;
VAL_ 967 MO_Tankdeckel_Lampe 0 "Lampe aus" 1 "Lampe ein" ;
VAL_ 967 MO_Text_Tankdeckelwarn 0 "kein_Text" 1 "Anzeige_Text_Tankdeckelwarnung_im_Kombi" ;
VAL_ 967 MO_Vorglueh_Lampe 0 "Lampe_aus" 1 "Lampe_ein" ;
VAL_ 967 WIV_Oeldr_Warn_Motor 0 "keine_Warnung" 1 "niedrige_Oeldruckstufe_nicht_erreicht" ;
VAL_ 967 MO_E_Mode 0 "keine_Anzeige" 1 "E_Mode_passiv" 2 "E_Mode_aktiv" 3 "E_Mode_inaktiv_nicht_verfuegbar" 4 "E_Mode_aktiv_nicht_verfuegbar" 5 "reserviert_keine_Anzeige" 6 "reserviert_keine_Anzeige" 7 "reserviert_keine_Anzeige" ;
VAL_ 327 MO_Hochschaltdrehz 0 "keine_manuelle_Hochschaltung" 4095 "Fehler" ;
VAL_ 327 MO_Anzeige_Verbr_Einheit 0 "l_h" 1 "kg_h" ;
VAL_ 327 MO_Schaltblitz_Anz 101 "blinkende_Anzeige" 126 "Init_Funktion_nicht_aktiv" 127 "Fehler" ;
VAL_ 327 MO_Anzeige_Drehmoment 2046 "nicht_verbaut" 2047 "Fehler" ;
VAL_ 327 MO_Anzeige_Leistung 2046 "nicht_verbaut" 2047 "Fehler" ;
VAL_ 1601 MO_Faktor_Momente_02 0 "nicht_belegt" ;
VAL_ 1601 MO_Hybridfahrzeug 0 "kein_Hybridfahrzeug" 1 "Mild_Hybrid" 2 "Full_Hybrid" 3 "PlugIn_Hybrid" ;
VAL_ 1601 MO_Getriebe_Code 0 "Init" 2 "DL501" 3 "DL800" 4 "VL381" 5 "DL382_Front" 6 "DL382_Allrad" 7 "DL702" 8 "AL552_Allrad" 9 "AL552_Front" 10 "AL651" 11 "AL551__AL951__AL1000_8A" 12 "PDK_PAG" 13 "AL551_Hybrid" 15 "Handschalter_konventionell" 16 "AQ250_160" 17 "AQ450" 18 "DQ200" 19 "DQ250" 20 "DQ500" 21 "SQ100" 22 "SQ200" 23 "DQ400E" 24 "DQ381" 25 "AL550" 26 "AQ300" 31 "DL800E" 32 "Single_Gear__ohne_GSG_WH_am_MSG" 33 "EQ550_2P" ;
VAL_ 1601 MO_StartStopp_Codiert 0 "Start_Stopp_nicht_verbaut" 1 "Start_Stopp_verbaut" ;
VAL_ 1601 MO_Anzeige_StSt_gueltig 0 "MO_Text_Motorstart_gueltig" 1 "Signale_MO_Anzeige_StSt_gueltig" ;
VAL_ 1601 MO_Anzahl_Zyl 0 "kein_Zylinder" 1 "1_Zylinder" 2 "2_Zylinder" 3 "3_Zylinder" 4 "4_Zylinder" 5 "5_Zylinder" 6 "6_Zylinder" 7 "7_Zylinder" 8 "8_Zylinder" 9 "9_Zylinder" 10 "10_Zylinder" 11 "11_Zylinder" 12 "12_Zylinder" 13 "15_Zylinder" 14 "16_Zylinder" 15 "18_Zylinder" ;
VAL_ 1601 MO_Kraftstoffart 0 "Diesel" 1 "Benzin_inkl_E25_E85" 2 "CNG" 3 "LPG" 4 "Wasserstoff" 5 "E100_Ethanol" 15 "kein_Verbrennungskraftstoff" ;
VAL_ 1601 MO_Ansaugsystem 0 "Turbo" 1 "Sauger" ;
VAL_ 1601 MO_OBD_Typ 0 "NoOBD_RdW" 1 "EOBD" 2 "US_OBD" 3 "reserviert" ;
VAL_ 1601 MO_DPF_verbaut 0 "kein_DPF_verbaut" 1 "DPF_verbaut" ;
VAL_ 1601 TSK_Codierung 0 "kein_Fahrgeschwindigkeitsregler" 1 "GRA" 2 "GRA_Plus" 3 "Basis_ACC" 4 "ACC_Follow_to_Stop" 5 "ACC_Stop_and_Go" 7 "Codierung_in_Plausibilisierungsphase" ;
VAL_ 391 EV_Rekuperationsstufe 0 "keine_Anzeige" 1 "1" 2 "2" 3 "3" 4 "4" 5 "5" ;
VAL_ 391 MO_Waehlpos 0 "Init_nicht_unterstuetzt" 1 "reserviert" 2 "P" 3 "R" 4 "N" 5 "D" 6 "B" 7 "Fehler" ;
VAL_ 391 MO_Fehler_NTKreis 0 "kein_Fehler" 1 "Fehler" ;
VAL_ 391 MO_Fehler_Notabschaltung_Klima 0 "Init" 1 "HVIL_ist_OK" 2 "HVIL_Fehler" 3 "ohne_Funktion" ;
VAL_ 391 MO_KLE_FStatus 0 "kein_Fehler" 2 "Fehlerentprellung" 3 "Fehler" ;
VAL_ 391 MO_WH_Texte 0 "keine_Anzeige" 1 "ShiftLock__Fussbremse_betaetigen" 3 "Wegrollgefahr_bitte_P_einlegen" 4 "Parksperre_Warnstufe_I" 5 "Parksperre_Warnstufe_II" 6 "P_nur_im_Stillstand_moeglich" ;
VAL_ 391 MO_Tankbereitschaft_Status 0 "keine_Aktion_Init" 1 "Tankbereitschaft_wird_hergestellt" 2 "Tankbereitschaft_ist_hergestellt" 3 "Tankbereitschaft_kann_nicht_hergestellt_werden" 4 "Tanksystem_Systemfehler" 5 "Tankklappe_pruefen_schliessen" 6 "Tankvorgang_abgebrochen" ;
VAL_ 391 MO_Tankklappensteuerung 0 "Init_nicht_verbaut" 1 "Tankklappe_soll_entriegeln" 2 "Tankklappe_soll_verriegeln" 3 "keine_Aktion" ;
VAL_ 813 MO_Fuellstand_LPG 1022 "ungueltig" 1023 "Fehler" ;
VAL_ 813 MO_CNG_LPG 0 "CNG" 1 "LPG" ;
VAL_ 813 MO_CNG_Tankstopp 0 "kein_Tankstopp" 1 "Tankstopp_erkannt" ;
VAL_ 813 MO_LPG_Tankstopp 0 "kein_Tankstopp" 1 "Tankstopp_erkannt" ;
VAL_ 813 MO_AnzeigeGasbetrieb 0 "keine_Textmeldung" 1 "Umschaltung_Gasbetrieb" 2 "Gasbetrieb" 3 "Umschaltung_Benzinbetrieb" 4 "Benzinbetrieb" 5 "Umschaltung_nicht_moeglich" 6 "Gasbetrieb_nicht_moeglich" 7 "Benzintank_leer" 8 "GAP_CNG_Betrieb_verhindert" ;
VAL_ 813 MO_akt_Betrieb 0 "Benzinbetrieb" 1 "Gasbetrieb" ;
VAL_ 813 MO_Erdgasqualitaet 0 "Anzeige_in_MFA_Rolle_nicht_auswaehlbar" 1 "Qualitaet_xxx" 2 "Qualitaet_100" 3 "Qualitaet_90" 4 "Qualitaet_80" 5 "Qualitaet_70" 6 "Qualitaet_xxx" 7 "Qualitaet_xxx" ;
VAL_ 813 MO_Verbrauchsaequivalent 0 "Funktion_nicht_unterstuetzt" 254 "Init_Adaption_nach_Betankung" 255 "Fehler" ;
VAL_ 813 MO_Tankmasse_CNG 0 "Init" 255 "Fehler" ;
VAL_ 813 MO_Tankvolumen_LPG 0 "Init" 255 "Fehler" ;
VAL_ 813 MO_Fuellungsgrad_CNG 254 "Init" 255 "Fehler" ;
VAL_ 813 MO_Fuellungsgrad_LPG 254 "Init_ungueltig" 255 "Fehler" ;
VAL_ 813 MO_CNG_Ueberlauf 0 "kein_Ueberlauf" 1 "mind_1_Ueberlauf" ;
VAL_ 813 MO_LPG_Ueberlauf 0 "kein_Ueberlauf" 1 "mind_1_Ueberlauf" ;
VAL_ 2589284112 MO_VTD_TD_L -2 "Init" -1 "Fehler" ;
VAL_ 2589284112 MO_VTD_CDEODT_L -2 "Init" -1 "Fehler" ;
VAL_ 2589284114 MO_VTD_CDFC_L -2 "Init" -1 "Fehler" ;
VAL_ 2589284114 MO_VTD_CDERDT_L -2 "Init" -1 "Fehler" ;
VAL_ 2589284116 MO_VTD_CIDT_L -2 "Init" -1 "Fehler" ;
VAL_ 2589284116 MO_VTD_GE_L -2 "Init" -1 "Fehler" ;
VAL_ 2589284118 MO_VTD_CIFC_L -2 "Init" -1 "Fehler" ;
VAL_ 2589284118 MO_VTD_FC_L -2 "Init" -1 "Fehler" ;
VAL_ 1156 ND_VDOP 1022 "Init" 1023 "Fehler" ;
VAL_ 1156 ND_TDOP 1022 "Init" 1023 "Fehler" ;
VAL_ 1156 ND_HDOP 1022 "Init" 1023 "Fehler" ;
VAL_ 1156 ND_GDOP 1022 "Init" 1023 "Fehler" ;
VAL_ 1156 ND_PDOP 1022 "Init" 1023 "Fehler" ;
VAL_ 1156 ND_Heading 4094 "Init" 4095 "Fehler" ;
VAL_ 1156 ND_Init 0 "nicht_Initialisiert" 1 "Initialisiert" ;
VAL_ 1157 ND_SatInUse 30 "Init" 31 "Fehler" ;
VAL_ 1157 POS_Guete_horizontal_verfuegbar 0 "nicht_verfuegbar" 1 "verfuegbar" ;
VAL_ 1157 ND_SatInView 30 "Init" 31 "Fehler" ;
VAL_ 1157 POS_Guete_horizontal 124 "von_248m_bis_400m" 125 "mehr_als_400m" 126 "Init" 127 "Fehler" ;
VAL_ 1157 NP_Altitude 4094 "Init" 4095 "Fehler" ;
VAL_ 2527679512 ND_Timezone_Offset 14 "Init" 15 "Fehler" ;
VAL_ 2527679512 ND_Timezone_SignBit 0 "PLUS_Vorzeichen" 1 "MINUS_Vorzeichen" ;
VAL_ 2527679512 ND_Timezone_Validity 0 "invalid" 1 "valid" ;
VAL_ 2527679512 ND_TimeToDestination 510 "Fehler" 511 "Init" ;
VAL_ 2527679512 ND_RouteType 0 "keine_Zielfuehrung_oder_MPR_aktiv" 1 "MPR_aktiv" 2 "Zielfuehrung_aktiv" 3 "reserviert" ;
VAL_ 2527679512 ND_TimeOffset 0 "Ziel_in_gleicher_Zeitzone" 1 "Ziel_in_Zeitzone_plus_1" 2 "Ziel_in_Zeitzone_minus_1" 3 "Zielzeitzone_groesser_plus_minus_1" ;
VAL_ 2527679512 ND_Fuelstation_detected 0 "nicht_verbaut" 1 "Tankstelle_nicht_erkannt" 2 "Tankstelle_erkannt" 3 "Init" ;
VAL_ 2527679512 ND_Velocity 1022 "Init" 1023 "Fehler" ;
VAL_ 2527679512 ND_RecDelay 4094 "Init" 4095 "Fehler" ;
VAL_ 2527679512 ND_SendDelay 4094 "Init" 4095 "Fehler" ;
VAL_ 2527679665 ND_PSD_Street_Category 0 "Rest_Feldweg_Schotterweg_Privatw" 1 "Ortsstrasse" 2 "Kreisstrasse" 3 "Landstrasse" 4 "Bundesstrasse" 5 "Autobahn" 6 "nicht_belegt" 7 "Init" ;
VAL_ 2527679665 ND_Avrg_Speed_RangeData 254 "Init" 255 "Fehler" ;
VAL_ 2527679770 NavMan_MainType 0 "NoSymbol" 1 "NoInfo" 2 "DirectionToDestination" 3 "Arrived" 4 "NearDestination" 5 "ArrivedDestinationOffmap" 6 "OffRoad" 7 "OffMap" 8 "NoRoute" 9 "CalcRoute" 10 "RecalcRoute" 11 "FollowStreet" 12 "ChangeLane" 13 "Turn" 14 "TurnOnMainroad" 15 "ExitRight" 16 "ExitLeft" 17 "ServiceRoadRight" 18 "ServiceRoadLeft" 19 "Fork_2" 20 "Fork_3" 21 "RoundaboutTrsRight" 22 "RoundaboutTrsLeft" 23 "SquareTrsRight" 24 "SquareTrsLeft" 25 "Uturn" 26 "ExitRoudaboutTrsRight" 27 "ExitRoudaboutTrsLeft" 28 "PrepareTurn" 29 "PrepareRoundabout" 30 "PrepareSquare" 31 "PrepareUTurn" 32 "reserved_ExitRight_RampUp" 33 "reserved_ExitRight_RampDown" 34 "MichigangTurn" 35 "DoubleTurn" 36 "reserved_ExitLeft_RampUp" 37 "reserved_ExitLeft_RampDown" 38 "DirectionToWaypoint" 39 "reserved" 63 "reserved" ;
VAL_ 2527679770 NavMan_Distance_Unit 0 "meter" 1 "kilometer" 2 "yard" 3 "feet" 4 "mile_UK_and_US_statute_mile" 5 "quarter_mile" 6 "reserved" 7 "Init" ;
VAL_ 2527679770 NavMan_ApproachDistanceInPercent 101 "reserved" 125 "reserved" 126 "Init" ;
VAL_ 1158 NP_LatDegree 134217726 "Init" 134217727 "Fehler" ;
VAL_ 1158 NP_LongDegree 268435454 "Init" 268435455 "Fehler" ;
VAL_ 1158 NP_LatDirection 0 "Nord" 1 "Sued" ;
VAL_ 1158 NP_LongDirection 0 "Ost" 1 "West" ;
VAL_ 1158 NP_Sat 30 "Init" 31 "Fehler" ;
VAL_ 1158 NP_Fix 0 "Init" 1 "No_Fix" 2 "2D_Fix" 3 "3D_Fix" ;
VAL_ 2589283496 POS_MUX 0 "MUX_0" 1 "MUX_1" 2 "reserved" 3 "Init" ;
VAL_ 2589283496 POS_ODD_EVEN 0 "ODD" 1 "EVEN" ;
VAL_ 2589283496 POS_PosStati 0 "Init" 1 "NoNavAvailable" 2 "NoMapAvailable" 3 "NavBooting" 4 "NavError" 5 "NavCalibrating" 6 "NavNoGpsResyncSince1h" 7 "NavOffroadParkgarageRampOffset2" 8 "DeadReckoningWithoutGps" 9 "DeadReckoningWithGps" 10 "MapMatchedLowConfidence" 11 "MapMatchedLimitedConfidence" 12 "OffroadHighConfidence" 13 "MapMatchedHighConfidence" 14 "PosInSyncWithGpsAndMAP" ;
VAL_ 2589283496 POS_LatDirection 0 "North" 1 "South" ;
VAL_ 2589283496 POS_LatDegree 134217726 "Init" 134217727 "Fehler" ;
VAL_ 2589283496 POS_Heading_Trust 0 "Init" 1 "TrustLevel01" 2 "TrustLevel02" 3 "Fehler" ;
VAL_ 2589283496 POS_LongDirection 0 "East" 1 "West" ;
VAL_ 2589283496 POS_LongDegree 268435454 "Init" 268435455 "Fehler" ;
VAL_ 2527679645 NFC_MiKo_Fehler 0 "SG_iO" 1 "SG_defekt" 2 "Antenne_defekt" 4 "Unterspannung" 8 "Ueberspannung" 16 "Ueberhitzung" ;
VAL_ 2527679645 NFC_MiKo_NFC_Device_Status 0 "Init_nicht_erkannt" 1 "NFC_Device_erkannt" 2 "MDK_Framework_erkannt" 3 "MDK_Applet_erkannt" 4 "MDK_Servicekarte_erkannt" 5 "MDK_Device_authentifiziert" ;
VAL_ 2527679645 NFC_MiKo_NFC_Device_gekoppelt 0 "Init_kein_NFC_Device_gekoppelt" 1 "NFC_Device_gekoppelt" ;
VAL_ 2527679645 NFC_MiKo_Laden_unterbrechen 0 "Init_keine_Unterbrechung" 1 "Laden_unterbrechen" ;
VAL_ 2527679645 NFC_MiKo_ESM_aktiv 0 "Init_kein_ESM" 1 "ESM_aktiv" ;
VAL_ 2600468788 NM_BedienDisp_m_CBV_AWB 0 "Passiver_WakeUp" 1 "Aktiver_WakeUp" ;
VAL_ 2600468788 NM_BedienDisp_m_CBV_CRI 0 "NM_ohne_Clusteranforderungen" 1 "NM_mit_Clusteranforderungen" ;
VAL_ 2600468788 NM_BedienDisp_m_NM_State 0 "Init" 1 "NM_RM_aus_BSM" 2 "NM_RM_aus_PBSM" 4 "NM_NO_aus_RM" 8 "NM_NO_aus_RS" 16 "reserved" 32 "reserved" ;
VAL_ 2600468788 NM_BedienDisp_m_Car_Wakeup 0 "Inaktiv" 1 "Car_Wakeup" ;
VAL_ 2600468788 NM_BedienDisp_m_UDS_CC 0 "Init" 1 "CC_aktiv" ;
VAL_ 2600468788 NM_BedienDisp_m_NM_aktiv_KL15 0 "Inaktiv" 1 "KL15_EIN" ;
VAL_ 2600468788 NM_BedienDisp_m_NM_aktiv_Diagnos 0 "Init" 1 "Diagnose_aktiv" ;
VAL_ 2600468788 NM_BedienDisp_m_NM_aktiv_Tmin 0 "Inaktiv" 1 "Mindestaktivzeit" ;
VAL_ 2600468788 NM_BedienDisp_m_CAB_V14 0 "Init" 1 "CAB_01_Antrieb" 2 "CAB_02_Hybrid_Laden" 4 "CAB_03_Fahrwerk" 8 "CAB_04_Fahrerassistenz" 16 "CAB_05_Komfort" 32 "CAB_06_Anzeige" 64 "CAB_07_Connect" 128 "CAB_08_MIB" 256 "CAB_09_Standheizung" 1024 "CAB_11_VLAN_Fahrerassistenz" 2048 "CAB_12_VLAN_Komfort" 4096 "CAB_13_VLAN_Connect" 8192 "CAB_14_VLAN_Infotainment" 16384 "CAB_15_Laden" 32768 "CAB_16_Licht" ;
VAL_ 2600468642 NM_BedienDisp_vm_CBV_AWB 0 "Passiver_WakeUp" 1 "Aktiver_WakeUp" ;
VAL_ 2600468642 NM_BedienDisp_vm_CBV_CRI 0 "Standard_Layout" 1 "TNB_Layout" ;
VAL_ 2600468642 NM_BedienDisp_vm_NM_State 0 "Init" 1 "NM_RM_aus_BSM" 2 "NM_RM_aus_PBSM" 4 "NM_NO_aus_RM" 8 "NM_NO_aus_RS" 16 "reserved" 32 "reserved" ;
VAL_ 2600468642 NM_BedienDisp_vm_Car_Wakeup 0 "Inaktiv" 1 "Car_Wakeup" ;
VAL_ 2600468642 NM_BedienDisp_vm_UDS_CC 0 "Init" 1 "CC_aktiv" ;
VAL_ 2600468642 NM_BedienDisp_vm_NM_aktiv_KL15 0 "Inaktiv" 1 "KL15_EIN" ;
VAL_ 2600468642 NM_BedienDisp_vm_NM_aktiv_Diag 0 "Inaktiv" 1 "Diagnose_aktiv" ;
VAL_ 2600468642 NM_BedienDisp_vm_NM_aktiv_Tmin 0 "Inaktiv" 1 "Mindestaktivzeit" ;
VAL_ 2600468642 NM_BedienDisp_vm_CAB_V14 0 "Init" 1 "CAB_01_Antrieb" 2 "CAB_02_Hybrid_Laden" 4 "CAB_03_Fahrwerk" 8 "CAB_04_Fahrerassistenz" 16 "CAB_05_Komfort" 32 "CAB_06_Anzeige" 64 "CAB_07_Connect" 128 "CAB_08_MIB" 256 "CAB_09_Standheizung" 1024 "CAB_11_VLAN_Fahrerassistenz" 2048 "CAB_12_VLAN_Komfort" 4096 "CAB_13_VLAN_Connect" 8192 "CAB_14_VLAN_Infotainment" 16384 "CAB_15_Laden" 32768 "CAB_16_Licht" ;
VAL_ 2600468583 NM_eCall_CBV_AWB 0 "Passiver_WakeUp" 1 "Aktiver_WakeUp" ;
VAL_ 2600468583 NM_eCall_CBV_CRI 0 "NM_ohne_Clusteranforderungen" 1 "NM_mit_Clusteranforderungen" ;
VAL_ 2600468583 NM_eCall_NM_State 0 "Init" 1 "NM_RM_aus_BSM" 2 "NM_RM_aus_PBSM" 4 "NM_NO_aus_RM" 8 "NM_NO_aus_RS" 16 "reserved" 32 "reserved" ;
VAL_ 2600468583 NM_eCall_Car_Wakeup 0 "Inaktiv" 1 "Car_Wakeup" ;
VAL_ 2600468583 NM_eCall_UDS_CC 0 "Inaktiv" 1 "CC_aktiv" ;
VAL_ 2600468583 NM_eCall_NM_aktiv_KL15 0 "Inaktiv" 1 "KL15_EIN" ;
VAL_ 2600468583 NM_eCall_NM_aktiv_Diagnose 0 "Init" 1 "Diagnose_aktiv" ;
VAL_ 2600468583 NM_eCall_NM_aktiv_Tmin 0 "Inaktiv" 1 "Mindestaktivzeit" ;
VAL_ 2600468583 NM_eCall_NM_aktiv_Laden 0 "Init" 1 "Remote_Charging_aktiv" ;
VAL_ 2600468583 NM_eCall_NM_aktiv_Settings 0 "Init" 1 "Remote_Settings_aktiv" ;
VAL_ 2600468583 NM_eCall_NM_aktiv_Klimatisieren 0 "Init" 1 "Remote_Clima_aktiv" ;
VAL_ 2600468583 NM_eCall_NM_aktiv_Status 0 "Init" 1 "Remote_Status_aktiv" ;
VAL_ 2600468583 NM_eCall_NM_aktiv_Remote_Control 0 "Init" 1 "Remote_Control_aktiv" ;
VAL_ 2600468583 NM_eCall_NM_aktiv_Call 0 "Init" 1 "Anruf_aktiv" ;
VAL_ 2600468583 NM_eCall_NM_aktiv_Dienstabfrage 0 "Init" 1 "Abfrage_aktiv" ;
VAL_ 2600468583 NM_eCall_NM_aktiv_IAA 0 "Init" 1 "IAA_aktiv" ;
VAL_ 2600468583 NM_eCall_NM_aktiv_RemoteStart 0 "Init" 1 "RemoteStart_aktiv" ;
VAL_ 2600468583 NM_eCall_NM_aktiv_MQTT_GW 0 "Init" 1 "MQTT_GW_aktiv" ;
VAL_ 2600468583 NM_eCall_NM_aktiv_RPA 0 "Inaktiv" 1 "RPA_aktiv" ;
VAL_ 2600468583 NM_eCall_NM_aktiv_ORU_OCU 0 "Init" 1 "ORU_OCU_aktiv" ;
VAL_ 2600468583 NM_eCall_NM_aktiv_PSO 0 "Init" 1 "PSO_aktiv" ;
VAL_ 2600468583 NM_eCall_CAB_V14 0 "Init" 1 "CAB_01_Antrieb" 2 "CAB_02_Hybrid_Laden" 4 "CAB_03_Fahrwerk" 8 "CAB_04_Fahrerassistenz" 16 "CAB_05_Komfort" 32 "CAB_06_Anzeige" 64 "CAB_07_Connect" 128 "CAB_08_MIB" 256 "CAB_09_Standheizung" 1024 "CAB_11_VLAN_Fahrerassistenz" 2048 "CAB_12_VLAN_Komfort" 4096 "CAB_13_VLAN_Connect" 8192 "CAB_14_VLAN_Infotainment" 16384 "CAB_15_Laden" 32768 "CAB_16_Licht" ;
